VERSION ""

NS_ :

BS_:

BU_: HCM IPMA_ADAS PSCM GWM _delete SCCM PDM DDM GENERIC TSTR
VAL_TABLE_ NotPressed_Pressed_NotU_Faulty 3 "Faulty" 2 "NotUsed" 1 "Pressed" 0 "Not_Pressed" ;
VAL_TABLE_ TsrChime_D_Rq 3 "Null" 2 "Overspeed_chime" 1 "SL_change_chime" 0 "NotUsed" ;
VAL_TABLE_ Fast_Slow 1 "Slow" 0 "Fast" ;
VAL_TABLE_ Disabled_Enabled 1 "Enabled" 0 "Disabled" ;
VAL_TABLE_ NoRequest_Group1_Group2_Both 3 "Both" 2 "Group2" 1 "Group1" 0 "NoRequest" ;
VAL_TABLE_ StlnVeh1_D_StatLim 7 "NotUsed_3" 6 "NotUsed_2" 5 "NotUsed_1" 4 "Accepted" 3 "Pending" 2 "Denied" 1 "Possible" 0 "NotPossible" ;
VAL_TABLE_ StlnVeh1_D_ResLim 31 "NotUsed_14" 30 "NotUsed_13" 29 "NotUsed_12" 28 "NotUsed_11" 27 "NotUsed_10" 26 "NotUsed_9" 25 "NotUsed_8" 24 "NotUsed_7" 23 "NotUsed_6" 22 "NotUsed_5" 21 "NotUsed_4" 20 "NotUsed_3" 19 "NotUsed_2" 18 "NotUsed_1" 17 "ReversePropulsionOnly" 16 "ForwardPropulsionOnly" 15 "SaveEv" 14 "EvOnly" 13 "TqLimitMed_ReducedPower" 12 "TqLimitHigh_Truncation" 11 "VslCustom" 10 "VslHigh_HighwaySpeeds" 9 "VslMed_UrbanSpeeds" 8 "VslLow_ParkingLowSpeed" 7 "LimitedPropulsion" 6 "NonMotiveMode" 5 "SecureMode" 4 "PowerPackBlock_Inhibit" 3 "Custom2" 2 "Custom1" 1 "NoLimitRequested" 0 "Initializing" ;
VAL_TABLE_ TailLghtAnmtn_D_Stat 15 "Faulty" 14 "NotUsed_8" 13 "NotUsed_7" 12 "NotUsed_6" 11 "NotUsed_5" 10 "NotUsed_4" 9 "NotUsed_3" 8 "NotUsed_2" 7 "NotUsed_1" 6 "Type6" 5 "Type5" 4 "Type4" 3 "Type3" 2 "Type2" 1 "Type1" 0 "Null" ;
VAL_TABLE_ None_InProgress_Major_Minor 3 "Minor" 2 "Major" 1 "InProgress" 0 "None" ;
VAL_TABLE_ StopStrtImccTxt_D_Stat 7 "NotUsed_3" 6 "NotUsed_2" 5 "NotUsed_1" 4 "ClosedTimeout" 3 "ClosedYes" 2 "ClosedNo" 1 "ActiveOnDsply" 0 "NotActive" ;
VAL_TABLE_ StopStrtImccActv_D_St 7 "NotUsed_3" 6 "NotUsed_2" 5 "NotUsed_1" 4 "Deactivated" 3 "OnSuspended" 2 "OnActive" 1 "OnNotActive" 0 "Off" ;
VAL_TABLE_ TrakApplActvSet_D_Rq 15 "NotUsed_12" 14 "NotUsed_11" 13 "NotUsed_10" 12 "NotUsed_9" 11 "NotUsed_8" 10 "NotUsed_7" 9 "NotUsed_6" 8 "NotUsed_5" 7 "NotUsed_4" 6 "NotUsed_3" 5 "NotUsed_2" 4 "NotUsed_1" 3 "AccTimer_Start_Track" 2 "AccTimer_Start_Drag" 1 "AccTimer_Start_Automatic" 0 "Null" ;
VAL_TABLE_ TrakAppl_D_RqMnu 31 "NotUsed_15" 30 "NotUsed_14" 29 "NotUsed_13" 28 "NotUsed_12" 27 "NotUsed_11" 26 "NotUsed_10" 25 "NotUsed_9" 24 "NotUsed_8" 23 "NotUsed_7" 22 "NotUsed_6" 21 "NotUsed_5" 20 "NotUsed_4" 19 "NotUsed_3" 18 "NotUsed_2" 17 "NotUsed_1" 16 "Activate_LineLock" 15 "Activate_LapTimer" 14 "Activate_400m" 13 "Activate_200m" 12 "Activate_1/4mile" 11 "Activate_1/8mile" 10 "Activate_0-200kph" 9 "Activate_0-100kph" 8 "Activate_0-50kph" 7 "Activate_0-100mph" 6 "Activate_0-60mph" 5 "Activate_0-30mph" 4 "Activate_200-0kph" 3 "Activate_100-0kph" 2 "Activate_100-0mph" 1 "Activate_60-0mph" 0 "Deactivate_TrackApp" ;
VAL_TABLE_ RoadSignRgltry_D_Dsply 3 "NoEntry" 2 "Stop" 1 "Yield" 0 "None" ;
VAL_TABLE_ Null_Local_Soa_NotUsed_1 3 "NotUsed_1" 2 "Soa" 1 "Local" 0 "Null" ;
VAL_TABLE_ Null_Off_On_NotUsed 3 "NotUsed" 2 "On" 1 "Off" 0 "Null" ;
VAL_TABLE_ FailSuccess 1 "Success" 0 "Fail" ;
VAL_TABLE_ LaActAvail_D2_Actl 3 "Intervention_Available" 2 "NoIntervention_Available" 1 "Intervention_NotAvailable" 0 "NoIntervention_NotAvailabl" ;
VAL_TABLE_ LaActvStats_D2_Dsply 31 "Unused7" 30 "LA_Off" 29 "ECE_OFF_RTT" 28 "Unused4" 27 "Unused3" 26 "Unused2" 25 "Unused1" 24 "InerveneLeft_InterveneRght" 23 "WarnLeft_InterveneRight" 22 "SuppressLeft_InterveneRght" 21 "AvailLeft_InterveneRhtt" 20 "NoLeft_InterveneRight" 19 "InterveneLeft_WarnRight" 18 "WarnLeft_WarnRight" 17 "SuppressLeft_WarnRight" 16 "AvailableLeft_WarnRight" 15 "NoLeft_WarnRight" 14 "InterveneLeft_SuppressRght" 13 "WarnLeft_SuppressRight" 12 "SuppressLeft_SuppressRight" 11 "AvailLeft_SuppressRight" 10 "NoLeft_SuppressRight" 9 "InterveneLeft_AvailRight" 8 "WarnLeft_AvailRight" 7 "SuppressLeft_AvailRight" 6 "AvailableLeft_AvailRight" 5 "NoLeft_AvailableRight" 4 "InterveneLeft_NoRight" 3 "WarnLeft_NoRight" 2 "SuppressLeft_NoRight" 1 "AvailableLeft_NoRight" 0 "NoLeft_NoRight" ;
VAL_TABLE_ TjaCanclMsgTxt_D_Dsply 15 "NotUsed_9" 14 "NotUsed_8" 13 "NotUsed_7" 12 "NotUsed_6" 11 "NotUsed_5" 10 "NotUsed_4" 9 "NotUsed_3" 8 "NotUsed_2" 7 "NotUsed_1" 6 "DriverNotSeen2" 5 "DriverNotSeen1" 4 "HandsFreeUnavailInThisArea" 3 "HandsFreeUnavailForMaxSpd" 2 "CancelledForLaneConditions" 1 "CancelledForRoadCurvature" 0 "NoMessage" ;
VAL_TABLE_ NotPressed_PressedStuckNotUsed 3 "NotUsed" 2 "Stuck" 1 "Pressed" 0 "Not_Pressed" ;
VAL_TABLE_ GfhbMnu_D_Rq 3 "EnableADB" 2 "EnableGFHB" 1 "Disable" 0 "Null" ;
VAL_TABLE_ OffOn_Overruled_NotUsed_1 3 "NotUsed_1" 2 "Overruled" 1 "On" 0 "Off" ;
VAL_TABLE_ StrtrMtrCtlMsgTxt_D_Rq2 15 "Not_Used_12" 14 "Not_Used_11" 13 "Not_Used_10" 12 "Not_Used_9" 11 "Not_Used_8" 10 "Not_Used_7" 9 "Not_Used_6" 8 "Not_Used_5" 7 "Not_Used_4" 6 "Not_Used_3" 5 "Not_Used_2" 4 "Not_Used_1" 3 "Fault_UnableToStrtOrStop" 2 "PressTwiceToStart" 1 "Fault_GoToDealer" 0 "NoMessage" ;
VAL_TABLE_ BptStrtStop_D_Stat 3 "NotUsed_1" 2 "Start" 1 "Stop" 0 "NoRequest" ;
VAL_TABLE_ BptMde_D_Stat 7 "NotUsed_4" 6 "NotUsed_3" 5 "NotUsed_2" 4 "NotUsed_1" 3 "Automatic" 2 "Manual" 1 "Off" 0 "Null" ;
VAL_TABLE_ NoData_Faulty_7FFFFE_7FFFFF 8388607 "Faulty" 8388606 "NoDataExists" ;
VAL_TABLE_ NoData_Faulty_3FFFFE_3FFFFF 4194303 "Faulty" 4194302 "NoDataExists" ;
VAL_TABLE_ PersCtaSplitView_D_Rq 3 "EnabledFull" 2 "Enabled_180SwitchOnly" 1 "Disabled" 0 "Null" ;
VAL_TABLE_ DrvIdMde_D_Rq 7 "Faulty" 6 "NotUsed_2" 5 "KeepAwake" 4 "DeleteMid" 3 "ClearAll" 2 "Enroll" 1 "Recognize" 0 "Disable" ;
VAL_TABLE_ DrvIdMde_D_Stat 7 "Temp_unavailable" 6 "Idle" 5 "DBCorrupt" 4 "DeleteMid" 3 "ClearAll" 2 "Enroll" 1 "Recognize" 0 "Null" ;
VAL_TABLE_ Null_Fail_Success 3 "NotUsed" 2 "Success" 1 "Fail" 0 "Null" ;
VAL_TABLE_ DrvId_D_Stat 7 "NotUsed_3" 6 "NotUsed_2" 5 "NotUsed_1" 4 "FailTimeout" 3 "FailWeakMatch" 2 "OkNoMatch" 1 "OkMatched" 0 "Null" ;
VAL_TABLE_ DrvExpression_D_Stat 15 "NotUsed_5" 14 "NotUsed_4" 13 "NotUsed_3" 12 "FailMultipleMatches" 11 "FailNoSlot" 10 "HasRegister" 9 "ConstraintsOk" 8 "NotAFace" 7 "PoorTrackingQuality" 6 "EyesNotVisible" 5 "FaceBlockage" 4 "MouthOpen" 3 "OutsidePoseLimits" 2 "TooManyFaces" 1 "FaceNotInView" 0 "Null" ;
VAL_TABLE_ AhbFeat_D_Stat 3 "ADB" 2 "GFHB" 1 "AHBC" 0 "None" ;
VAL_TABLE_ NavIod_D_Rq 7 "NotUsed_5" 6 "NotUsed_4" 5 "NotUsed_3" 4 "NotUsed_2" 3 "NotUsed_1" 2 "ModeChange" 1 "VideoOutput" 0 "NoRequest" ;
VAL_TABLE_ NotAvailable_Down_Up_NotU 3 "NotUsed_1" 2 "Up" 1 "Down" 0 "NotAvailable" ;
VAL_TABLE_ EngIdlShutDownT_D_Stat 255 "NotUsed_13" 254 "NotUsed_12" 253 "NotUsed_11" 252 "NotUsed_10" 251 "NotUsed_9" 250 "NotUsed_8" 249 "NotUsed_7" 248 "NotUsed_6" 247 "NotUsed_5" 246 "NotUsed_4" 245 "NotUsed_3" 244 "NotUsed_2" 243 "NotUsed_1" 242 "Indefinite_Idle" 241 "Selectable_Idle_Not_Active" 240 "IdleMinutes_240" 239 "IdleMinutes_239" 238 "IdleMinutes_238" 237 "IdleMinutes_237" 236 "IdleMinutes_236" 235 "IdleMinutes_235" 234 "IdleMinutes_234" 233 "IdleMinutes_233" 232 "IdleMinutes_232" 231 "IdleMinutes_231" 230 "IdleMinutes_230" 229 "IdleMinutes_229" 228 "IdleMinutes_228" 227 "IdleMinutes_227" 226 "IdleMinutes_226" 225 "IdleMinutes_225" 224 "IdleMinutes_224" 223 "IdleMinutes_223" 222 "IdleMinutes_222" 221 "IdleMinutes_221" 220 "IdleMinutes_220" 219 "IdleMinutes_219" 218 "IdleMinutes_218" 217 "IdleMinutes_217" 216 "IdleMinutes_216" 215 "IdleMinutes_215" 214 "IdleMinutes_214" 213 "IdleMinutes_213" 212 "IdleMinutes_212" 211 "IdleMinutes_211" 210 "IdleMinutes_210" 209 "IdleMinutes_209" 208 "IdleMinutes_208" 207 "IdleMinutes_207" 206 "IdleMinutes_206" 205 "IdleMinutes_205" 204 "IdleMinutes_204" 203 "IdleMinutes_203" 202 "IdleMinutes_202" 201 "IdleMinutes_201" 200 "IdleMinutes_200" 199 "IdleMinutes_199" 198 "IdleMinutes_198" 197 "IdleMinutes_197" 196 "IdleMinutes_196" 195 "IdleMinutes_195" 194 "IdleMinutes_194" 193 "IdleMinutes_193" 192 "IdleMinutes_192" 191 "IdleMinutes_191" 190 "IdleMinutes_190" 189 "IdleMinutes_189" 188 "IdleMinutes_188" 187 "IdleMinutes_187" 186 "IdleMinutes_186" 185 "IdleMinutes_185" 184 "IdleMinutes_184" 183 "IdleMinutes_183" 182 "IdleMinutes_182" 181 "IdleMinutes_181" 180 "IdleMinutes_180" 179 "IdleMinutes_179" 178 "IdleMinutes_178" 177 "IdleMinutes_177" 176 "IdleMinutes_176" 175 "IdleMinutes_175" 174 "IdleMinutes_174" 173 "IdleMinutes_173" 172 "IdleMinutes_172" 171 "IdleMinutes_171" 170 "IdleMinutes_170" 169 "IdleMinutes_169" 168 "IdleMinutes_168" 167 "IdleMinutes_167" 166 "IdleMinutes_166" 165 "IdleMinutes_165" 164 "IdleMinutes_164" 163 "IdleMinutes_163" 162 "IdleMinutes_162" 161 "IdleMinutes_161" 160 "IdleMinutes_160" 159 "IdleMinutes_159" 158 "IdleMinutes_158" 157 "IdleMinutes_157" 156 "IdleMinutes_156" 155 "IdleMinutes_155" 154 "IdleMinutes_154" 153 "IdleMinutes_153" 152 "IdleMinutes_152" 151 "IdleMinutes_151" 150 "IdleMinutes_150" 149 "IdleMinutes_149" 148 "IdleMinutes_148" 147 "IdleMinutes_147" 146 "IdleMinutes_146" 145 "IdleMinutes_145" 144 "IdleMinutes_144" 143 "IdleMinutes_143" 142 "IdleMinutes_142" 141 "IdleMinutes_141" 140 "IdleMinutes_140" 139 "IdleMinutes_139" 138 "IdleMinutes_138" 137 "IdleMinutes_137" 136 "IdleMinutes_136" 135 "IdleMinutes_135" 134 "IdleMinutes_134" 133 "IdleMinutes_133" 132 "IdleMinutes_132" 131 "IdleMinutes_131" 130 "IdleMinutes_130" 129 "IdleMinutes_129" 128 "IdleMinutes_128" 127 "IdleMinutes_127" 126 "IdleMinutes_126" 125 "IdleMinutes_125" 124 "IdleMinutes_124" 123 "IdleMinutes_123" 122 "IdleMinutes_122" 121 "IdleMinutes_121" 120 "IdleMinutes_120" 119 "IdleMinutes_119" 118 "IdleMinutes_118" 117 "IdleMinutes_117" 116 "IdleMinutes_116" 115 "IdleMinutes_115" 114 "IdleMinutes_114" 113 "IdleMinutes_113" 112 "IdleMinutes_112" 111 "IdleMinutes_111" 110 "IdleMinutes_110" 109 "IdleMinutes_109" 108 "IdleMinutes_108" 107 "IdleMinutes_107" 106 "IdleMinutes_106" 105 "IdleMinutes_105" 104 "IdleMinutes_104" 103 "IdleMinutes_103" 102 "IdleMinutes_102" 101 "IdleMinutes_101" 100 "IdleMinutes_100" 99 "IdleMinutes_99" 98 "IdleMinutes_98" 97 "IdleMinutes_97" 96 "IdleMinutes_96" 95 "IdleMinutes_95" 94 "IdleMinutes_94" 93 "IdleMinutes_93" 92 "IdleMinutes_92" 91 "IdleMinutes_91" 90 "IdleMinutes_90" 89 "IdleMinutes_89" 88 "IdleMinutes_88" 87 "IdleMinutes_87" 86 "IdleMinutes_86" 85 "IdleMinutes_85" 84 "IdleMinutes_84" 83 "IdleMinutes_83" 82 "IdleMinutes_82" 81 "IdleMinutes_81" 80 "IdleMinutes_80" 79 "IdleMinutes_79" 78 "IdleMinutes_78" 77 "IdleMinutes_77" 76 "IdleMinutes_76" 75 "IdleMinutes_75" 74 "IdleMinutes_74" 73 "IdleMinutes_73" 72 "IdleMinutes_72" 71 "IdleMinutes_71" 70 "IdleMinutes_70" 69 "IdleMinutes_69" 68 "IdleMinutes_68" 67 "IdleMinutes_67" 66 "IdleMinutes_66" 65 "IdleMinutes_65" 64 "IdleMinutes_64" 63 "IdleMinutes_63" 62 "IdleMinutes_62" 61 "IdleMinutes_61" 60 "IdleMinutes_60" 59 "IdleMinutes_59" 58 "IdleMinutes_58" 57 "IdleMinutes_57" 56 "IdleMinutes_56" 55 "IdleMinutes_55" 54 "IdleMinutes_54" 53 "IdleMinutes_53" 52 "IdleMinutes_52" 51 "IdleMinutes_51" 50 "IdleMinutes_50" 49 "IdleMinutes_49" 48 "IdleMinutes_48" 47 "IdleMinutes_47" 46 "IdleMinutes_46" 45 "IdleMinutes_45" 44 "IdleMinutes_44" 43 "IdleMinutes_43" 42 "IdleMinutes_42" 41 "IdleMinutes_41" 40 "IdleMinutes_40" 39 "IdleMinutes_39" 38 "IdleMinutes_38" 37 "IdleMinutes_37" 36 "IdleMinutes_36" 35 "IdleMinutes_35" 34 "IdleMinutes_34" 33 "IdleMinutes_33" 32 "IdleMinutes_32" 31 "IdleMinutes_31" 30 "IdleMinutes_30" 29 "IdleMinutes_29" 28 "IdleMinutes_28" 27 "IdleMinutes_27" 26 "IdleMinutes_26" 25 "IdleMinutes_25" 24 "IdleMinutes_24" 23 "IdleMinutes_23" 22 "IdleMinutes_22" 21 "IdleMinutes_21" 20 "IdleMinutes_20" 19 "IdleMinutes_19" 18 "IdleMinutes_18" 17 "IdleMinutes_17" 16 "IdleMinutes_16" 15 "IdleMinutes_15" 14 "IdleMinutes_14" 13 "IdleMinutes_13" 12 "IdleMinutes_12" 11 "IdleMinutes_11" 10 "IdleMinutes_10" 9 "IdleMinutes_9" 8 "IdleMinutes_8" 7 "IdleMinutes_7" 6 "IdleMinutes_6" 5 "IdleMinutes_5" 4 "IdleMinutes_4" 3 "IdleMinutes_3" 2 "IdleMinutes_2" 1 "IdleMinute_1" 0 "Null" ;
VAL_TABLE_ NotCalibing_Calibing_NotU1_NotU2 3 "NotUsed_2" 2 "NotUsed_1" 1 "Calibrating" 0 "NotCalibrating" ;
VAL_TABLE_ CalibNotReq_CalibReq_NotU1_NotU2 3 "NotUsed_2" 2 "NotUsed_1" 1 "CalibrationRequested" 0 "CalibrationNotRequested" ;
VAL_TABLE_ TrlrCamraView_D_Rq 15 "NotUsed_9" 14 "NotUsed_8" 13 "NotUsed_7" 12 "NotUsed_6" 11 "NotUsed_5" 10 "NotUsed_4" 9 "NotUsed_3" 8 "NotUsed_2" 7 "NotUsed_1" 6 "TrailerRightSideView" 5 "TrailerLeftSideView" 4 "TrailerInteriorView2" 3 "TrailerInteriorView1" 2 "TrailerRearNormalView" 1 "Trailer360View" 0 "Off" ;
VAL_TABLE_ NotConnected_Conntd_NotU1_NotU2 3 "NotUsed_2" 2 "NotUsed_1" 1 "Connected" 0 "NotConnected" ;
VAL_TABLE_ SodAltLeft_D2_StatAft 3 "Faulty" 2 "ActiveDetection" 1 "ActiveNoDetection" 0 "Standby" ;
VAL_TABLE_ Null_RemoteKey_Handsfree_Not1to5 7 "NotUsed_5" 6 "NotUsed_4" 5 "NotUsed_3" 4 "NotUsed_2" 3 "NotUsed_1" 2 "Handsfree" 1 "RemoteKey" 0 "Null" ;
VAL_TABLE_ LckUnlckSrvc_D_Res 15 "Faulty" 14 "NotUsed_7" 13 "NotUsed_6" 12 "NotUsed_5" 11 "NotUsed_4" 10 "NotUsed_3" 9 "NotUsed_2" 8 "NotUsed_1" 7 "Invalid" 6 "In_Prog" 5 "Failed" 4 "Interrupted" 3 "Rejected" 2 "Pending" 1 "Success" 0 "Null" ;
VAL_TABLE_ Real_Inferred 1 "Inferred" 0 "Real" ;
VAL_TABLE_ Null_Locked_Unlocked_NoDevOrDoor 3 "NoDeviceOrDoor" 2 "Unlocked" 1 "Locked" 0 "Null" ;
VAL_TABLE_ TjaLc_D_ET 15 "NotUsed_7" 14 "NotUsed_6" 13 "NotUsed_5" 12 "NotUsed_4" 11 "NotUsed_3" 10 "NotUsed_2" 9 "NotUsed_1" 8 "LcActiveRight" 7 "LcActiveLeft" 6 "PreparingRight" 5 "PreparingLeft" 4 "AvailableLeftRight" 3 "AvailableRight" 2 "AvailableLeft" 1 "Standby" 0 "Off" ;
VAL_TABLE_ TjaLcWarn_D_ET2 7 "NotUsed_2" 6 "NotUsed_1" 5 "CancelSpeedTooLow" 4 "CancelLaneBusy" 3 "CancelNoLane" 2 "SystemCancel" 1 "DriverCancel" 0 "NoWarning" ;
VAL_TABLE_ TjaLcMsgTxt_D_ET 7 "NotUsed_2" 6 "NotUsed_1" 5 "TurnOffIndicator" 4 "AlcOff" 3 "AlcOn" 2 "LcSuggestionRight" 1 "LcSuggestionLeft" 0 "NoMessage" ;
VAL_TABLE_ Inactive_OFF_ON_NotUsed 0 "Inactive" 1 "Off" 2 "On" 3 "NotUsed" ;
VAL_TABLE_ UnlckSrcRl_D_Stat 3 "InnerHandle" 2 "RearInteriorSwitch" 1 "IpSwitch" 0 "Null" ;
VAL_TABLE_ WhlSpareMsgTxt_D_Rq 3 "NotUsed" 2 "PleaseChangeYourSpareTire" 1 "DoNotDriveAbove80kph" 0 "NoMessage" ;
VAL_TABLE_ WhlSpareDetct_D_Dsply 7 "NotUsed_2" 6 "NotUsed_1" 5 "DetectedAtVehicleRearRight" 4 "DetectedAtVehicleRearLeft" 3 "DetectedAtVehicleFrntRight" 2 "DetectedAtVehicleFrontLeft" 1 "Active" 0 "NotActive" ;
VAL_TABLE_ TiltableSteMsgTxt_D_Rq 15 "NotUsed_5" 14 "NotUsed_4" 13 "NotUsed_3" 12 "NotUsed_2" 11 "NotUsed_1" 10 "ShifToNtrlToEnblWhlTilting" 9 "VehMotionNotAllowed" 8 "Fault_VehMotionInhibited" 7 "Fault_VehNotSafeToDrive" 6 "Fault_WhlToBeForcedIntoPos" 5 "Fault_VehicleSafeToDrive" 4 "CntrSteWhlToEnblWhlTilting" 3 "ApplyPrkBrkToEnblWhlTilting" 2 "ShifToParkToEnblWhlTilting" 1 "VehMtnNotAllwAirbagDactv" 0 "NoMessage" ;
VAL_TABLE_ AflMde_D_Rq 15 "NotUsed_13" 14 "NotUsed_12" 13 "NotUsed_11" 12 "NotUsed_10" 11 "NotUsed_9" 10 "NotUsed_8" 9 "NotUsed_7" 8 "NotUsed_6" 7 "NotUsed_5" 6 "NotUsed_4" 5 "NotUsed_3" 4 "NotUsed_2" 3 "NotUsed_1" 2 "TrafficSignDeGlare" 1 "DarkSpot" 0 "None" ;
VAL_TABLE_ HeadLghtHi_D_Rq 7 "NotUsed_4" 6 "NotUsed_3" 5 "NotUsed_2" 4 "NotUsed_1" 3 "OnAutomatic" 2 "OnManual" 1 "Flash" 0 "Off" ;
VAL_TABLE_ OverruledOnOff 3 "NotUsed" 2 "Overruled" 1 "On" 0 "Off" ;
VAL_TABLE_ DcacChime_D_Rq 3 "NotUsed" 2 "SoftChime" 1 "InformationChime" 0 "NoChime" ;
VAL_TABLE_ _S_Off_On 1 "On" 0 "Off" ;
VAL_TABLE_ _S_InactiveActive 1 "Active" 0 "Inactive" ;
VAL_TABLE_ HvacCmprLim_D_Stat 7 "NotUsed_2" 6 "NotUsed_1" 5 "CompressorHeadPressure" 4 "AvailableTorque" 3 "PedalPosition" 2 "RPM" 1 "ECT" 0 "NoLimit" ;
VAL_TABLE_ VehOnSrc_D_Stat 15 "NotUsed_11" 14 "NotUsed_10" 13 "NotUsed_9" 12 "NotUsed_8" 11 "NotUsed_7" 10 "NotUsed_6" 9 "EsclRssd" 8 "AutonomousVehicle" 7 "SecureIdle" 6 "FleetVehicleInhibit" 5 "StolenVehicleInhibit" 4 "OverTheAir" 3 "RemoteParkAssist" 2 "RemoteStart" 1 "Manual" 0 "Off" ;
VAL_TABLE_ NoMessage_Msg1_63 31 "Message31" 30 "Message30" 29 "Message29" 28 "Message28" 27 "Message27" 26 "Message26" 25 "Message25" 24 "Message24" 23 "Message23" 22 "Message22" 21 "Message21" 20 "Message20" 19 "Message19" 18 "Message18" 17 "Message17" 16 "Message16" 15 "Message15" 14 "Message14" 13 "Message13" 12 "Message12" 11 "Message11" 10 "Message10" 9 "Message9" 8 "Message8" 7 "Message7" 6 "Message6" 5 "Message5" 4 "Message4" 3 "Message3" 2 "Message2" 1 "Message1" 0 "NoMessage" 63 "Message63" 47 "Message47" ;
VAL_TABLE_ TrlrRvrseEnbl_D2_Stat 7 "NotUsed" 6 "TbaActiveExpertActive" 5 "TbaActiveExpertAvail" 4 "TbaOffTrgActive" 3 "TbaOffTrgSetup" 2 "TbaSetup" 1 "TbaActive" 0 "Inactive" ;
VAL_TABLE_ StrtrMtrCtlMsgTxt_D2_Rq 3 "NoRequestPcmStartingMsgCtl" 2 "ShiftToNeutralToStart" 1 "ShiftToParkToStart" 0 "NoRequestBcmStartingMsgCtl" ;
VAL_TABLE_ PaakMyKey_D_Rq 3 "NotUsed" 2 "ConfirmNewPaakMyKey" 1 "RequestNewPaakMyKey" 0 "None" ;
VAL_TABLE_ GearPrkLck_D_Stat 7 "NotUsed_1" 6 "FetLifeLimitReached" 5 "FetOpenCircuit" 4 "FetOutputShortToPower" 3 "FetOutputShortToGround" 2 "FetNotControlled" 1 "OnPowerToLoad" 0 "OffNoPowerToLoad" ;
VAL_TABLE_ TrlrIdType_D_Stat 3 "Gooseneck" 2 "FifthWheel" 1 "Conventional" 0 "Null" ;
VAL_TABLE_ TrlrAidSetup_D2_Rq 15 "NotUsed_9" 14 "NotUsed_8" 13 "NotUsed_7" 12 "NotUsed_6" 11 "NotUsed_5" 10 "NotUsed_4" 9 "NotUsed_3" 8 "NotUsed_2" 7 "NotUsed_1" 6 "CompleteSetup" 5 "ReturnToSetup" 4 "StickerNotCircled" 3 "ConfirmSetup" 2 "EndSetup" 1 "BeginSetup" 0 "Inactive" ;
VAL_TABLE_ TrlrAidEnbl_D2_Rq 7 "NotUsed_4" 6 "NotUsed_3" 5 "NotUsed_2" 4 "NotUsed_1" 3 "Deactivate" 2 "ActivateTrg" 1 "ActivateTba" 0 "Inactive" ;
VAL_TABLE_ SwitchNotActive_Active 1 "Switch_Active" 0 "Switch_Not_Active" ;
VAL_TABLE_ LcwaMsgTxt_D_Stat 3 "SodXFaulty" 2 "SodXBlocked" 1 "TrailerConnected" 0 "NoMessage" ;
VAL_TABLE_ Level_0_3 3 "Level_3" 2 "Level_2" 1 "Level_1" 0 "Level_0" ;
VAL_TABLE_ SteWhlSwtchMde_D_Stat 3 "NotUsed_2" 2 "NotUsed_1" 1 "Dialog" 0 "Domain" ;
VAL_TABLE_ TrlrRvrse_D_Stat 3 "Faulty" 2 "TrailerReverseGuidanceLite" 1 "On" 0 "Off" ;
VAL_TABLE_ TrlrAid_D2_Stat 15 "Faulty" 14 "NotUsed_4" 13 "NotUsed_3" 12 "NotUsed_2" 11 "NotUsed_1" 10 "DirtyCamera" 9 "IncorrectLighting" 8 "TrackingLost" 7 "TrackingUnknownConfidence" 6 "TrackingHighConfidence" 5 "TrackingMediumConfidence" 4 "TrackingLowConfidence" 3 "TurnRequested" 2 "DriveStraighRequested" 1 "Initializing" 0 "NotTracking" ;
VAL_TABLE_ TrlrAidSetup_D2_Stat 7 "NotUsed_2" 6 "NotUsed_1" 5 "SetupAcquisitionSuccess" 4 "TbaTadMonitor" 3 "SetupStartAcquisition" 2 "SetupPrepForAcquisition" 1 "TbaActive" 0 "Null" ;
VAL_TABLE_ CamraRearOn_D2_Stat2 7 "Faulty" 6 "NotUsed_3" 5 "NotUsed_2" 4 "NotUsed_1" 3 "Decommission" 2 "Activate" 1 "Deactivate" 0 "Null" ;
VAL_TABLE_ OffNormalSoft 3 "NotUsed" 2 "Soft" 1 "Normal" 0 "Off" ;
VAL_TABLE_ OffOnDisabledInhibited 3 "Inhibited" 2 "Disabled" 1 "On" 0 "Off" ;
VAL_TABLE_ SldrrMsgTxt_D2_Rq 7 "NotUsed_3" 6 "NotUsed_2" 5 "NotUsed_1" 4 "SlidingDrCalibNeeded2" 3 "SlidingDrOpenCltchReleased" 2 "SlidingDrCalibNeeded" 1 "SlidingDrClutchReleased" 0 "Null" ;
VAL_TABLE_ FobTrgtZone_D_Rq 15 "NotUsed_9" 14 "NotUsed_8" 13 "NotUsed_7" 12 "NotUsed_6" 11 "NotUsed_5" 10 "NotUsed_4" 9 "NotUsed_3" 8 "NotUsed_2" 7 "NotUsed_1" 6 "Approach" 5 "RearInterior" 4 "RearExterior" 3 "Passenger" 2 "Driver" 1 "Interior" 0 "Null" ;
VAL_TABLE_ FobTrgtType_D_Rq 7 "NotUsed_4" 6 "NotUsed_3" 5 "NotUsed_2" 4 "NotUsed_1" 3 "Polling" 2 "Registry" 1 "Crypto" 0 "Null" ;
VAL_TABLE_ Null_Yes 1 "Yes" 0 "Null" ;
VAL_TABLE_ Null_NoFault_Fault 3 "NotUsed" 2 "Fault" 1 "NoFault" 0 "Null" ;
VAL_TABLE_ RstrnOnPsngr_D_RqMnu 15 "Faulty" 14 "NotUsed_11" 13 "NotUsed_10" 12 "ConfiguredOff" 11 "NotUsed_9" 10 "On" 9 "NotUsed_8" 8 "NotUsed_7" 7 "NotUsed_6" 6 "NotUsed_5" 5 "Off" 4 "NotUsed_4" 3 "NotUsed_3" 2 "NotUsed_2" 1 "NotUsed_1" 0 "NoAction" ;
VAL_TABLE_ PwStepLeft_D_Rq 1 "Deploy" 0 "Null" 3 "NotUsed" 2 "Stow" ;
VAL_TABLE_ SldrlUnlckSwtch_D_Stat 3 "InnerHandle" 2 "RearInteriorSwitch" 1 "IpSwitch" 0 "Null" ;
VAL_TABLE_ SldrlChime_D_Rq 7 "NotUsed3" 6 "NotUsed2" 5 "NotUsed1" 4 "Warning" 3 "WarningRepeated" 2 "Programming" 1 "Operation" 0 "Off" ;
VAL_TABLE_ Sldrl_D_Stat 3 "NotCalibrated" 2 "Closing" 1 "Opening" 0 "NotMoving" ;
VAL_TABLE_ NoReq_AutoUp_Stop 3 "NotUsed" 2 "Stop" 1 "AutoUp" 0 "NoRequest" ;
VAL_TABLE_ BalrSnsLeft_D_Falt 3 "Invalid" 2 "SystemFailure" 1 "Blocked" 0 "Clear" ;
VAL_TABLE_ Null_Low_Med_High 3 "High" 2 "Medium" 1 "Low" 0 "Null" ;
VAL_TABLE_ Null_NotPressed_Pressed 3 "NotUsed" 2 "Pressed" 1 "NotPressed" 0 "Null" ;
VAL_TABLE_ Low_Med_High 3 "NotUsed" 2 "High" 1 "Medium" 0 "Low" ;
VAL_TABLE_ Null_NotAvail_Avail 3 "NotUsed" 2 "Available" 1 "NotAvailable" 0 "Null" ;
VAL_TABLE_ ChrgGoTMnte_D_Stat 15 "NotUsed_4" 14 "NotUsed_3" 13 "NotUsed_2" 12 "NotUsed_1" 11 "Minute_55" 10 "Minute_50" 9 "Minute_45" 8 "Minute_40" 7 "Minute_35" 6 "Minute_30" 5 "Minute_25" 4 "Minute_20" 3 "Minute_15" 2 "Minute_10" 1 "Minute_5" 0 "Minute_0" ;
VAL_TABLE_ NoData_Faulty_1E_1F 31 "Faulty" 30 "NoDataExists" ;
VAL_TABLE_ TrlrAidMsgTxt_D2_Rq 63 "Message63" 62 "Message62" 61 "Message61" 60 "Message60" 55 "Message55" 50 "Message50" 45 "Message45" 40 "Message40" 35 "Message35" 31 "Message31" 30 "Message30" 29 "Message29" 28 "Message28" 27 "Message27" 26 "Message26" 25 "Message25" 24 "Message24" 23 "Message23" 22 "Message22" 21 "Message21" 20 "Message20" 19 "Message19" 18 "Message18" 17 "Message17" 16 "Message16" 15 "Message15" 14 "Message14" 13 "Message13" 12 "Message12" 11 "Message11" 10 "Message10" 9 "Message9" 8 "Message8" 7 "Message7" 6 "Message6" 5 "Message5" 4 "Message4" 3 "Message3" 2 "Message2" 1 "Message1" 0 "NoMessage" ;
VAL_TABLE_ TrlrAidEnbl_D2_Stat 7 "NotUsed_1" 6 "TbaActiveExpertActive" 5 "TbaActiveExpertAvail" 4 "TbaOffTrgActive" 3 "TbaOffTrgSetup" 2 "TbaSetup" 1 "TbaActive" 0 "Inactive" ;
VAL_TABLE_ RbaCta_D_Stat 7 "Faulty" 6 "NotUsed_2" 5 "NotUsed_1" 4 "Invalid" 3 "Disabled" 2 "On" 1 "Trailer_Tow_Off" 0 "Off" ;
VAL_TABLE_ NoRequest_Mode1_2_3 3 "Mode_3" 2 "Mode_2" 1 "Mode_1" 0 "NoRequest" ;
VAL_TABLE_ RvltnMatchAllw_D_Stat 3 "RevolutionMatchDisabled" 2 "RevolutionMatchEnabled" 1 "ChangeWithDriveMode" 0 "NoSelection" ;
VAL_TABLE_ NotDiagnose_FailPass 3 "NotUsed" 2 "Pass" 1 "Fail" 0 "Not_Diagnose_Yet" ;
VAL_TABLE_ Null_Off_UnavailFaulty 3 "Faulty" 2 "Unavailable" 1 "Off" 0 "Null" ;
VAL_TABLE_ OffOnDisabledNotUsed 3 "NotUsed" 2 "Disabled" 1 "On" 0 "Off" ;
VAL_TABLE_ OffGraphicTextBoth 3 "Both" 2 "Text" 1 "Graphic" 0 "Off" ;
VAL_TABLE_ NoneInactiveActive_NotUsed 3 "NotUsed" 2 "Active" 1 "Inactive" 0 "None" ;
VAL_TABLE_ Off_On_NotUsed 3 "NotUsed_2" 2 "NotUsed_1" 1 "On" 0 "Off" ;
VAL_TABLE_ OffNoPowerToLoad 7 "FetLowSideOpenOrShort" 6 "FetLifeLimitReached" 5 "FetOpenCircuit" 4 "FetOutputShortToPower" 3 "FetOutputShortToGround" 2 "FetNotControlled" 1 "OnPowerToLoad" 0 "OffNoPowerToLoad" ;
VAL_TABLE_ Null_NotPressed_Faulty 3 "Faulty" 2 "Pressed" 1 "NotPressed" 0 "Null" ;
VAL_TABLE_ Null_Off_LowMedHigh 7 "NotUsed_3" 6 "NotUsed_2" 5 "NotUsed_1" 4 "High" 3 "Medium" 2 "Low" 1 "Off" 0 "Null" ;
VAL_TABLE_ TrailCtl_D_Stat 7 "Faulty" 6 "DescentOnly" 5 "EnabledDeny" 4 "StandbyOverThreshold" 3 "StandbyOverride" 2 "Active" 1 "EnabledDescent" 0 "Off" ;
VAL_TABLE_ Faulty_3F 63 "Faulty" ;
VAL_TABLE_ ChrgOvrdExitScrn_D_Rq 3 "NotUsed_1" 2 "Request_override" 1 "Do_not_request_override" 0 "Inactive" ;
VAL_TABLE_ TrlrHitchYaw_D_Stat 15 "Faulty" 14 "NotUsed_4" 13 "NotUsed_3" 12 "NotUsed_2" 11 "NotUsed_1" 10 "FaultyYrsuConnection" 9 "FaultyYrsu" 8 "HiConfdLrndAngle" 7 "LowConfdLrndAngle" 6 "HiConfdAngleMem" 5 "LowConfdAngleMem" 4 "InitNoTadAngle" 3 "InitInputs" 2 "TadTrlrDataOutOfRange" 1 "TadNotWithinSpecification" 0 "NoConnectionWithYrsu" ;
VAL_TABLE_ NoData_Faulty_FFFFFFFFFFFE_FF -1 "Faulty_FFFFFFFFFFFF" -2 "NoDataExists_FFFFFFFFFFFE" ;
VAL_TABLE_ NoFault_Fault 1 "Fault" 0 "NoFault" ;
VAL_TABLE_ OtaTrg_D_Stat 3 "NotUsed_1" 2 "Accepted" 1 "NotAccepted" 0 "Null" ;
VAL_TABLE_ AwdCnnct_D_Stat 3 "Connecting" 2 "Disconnecting" 1 "Connected" 0 "Disconnected" ;
VAL_TABLE_ Null_Invalid_Valid 3 "NotUsed" 2 "Valid" 1 "Invalid" 0 "Null" ;
VAL_TABLE_ ElPwPoint_D_Rq 3 "On" 2 "Off2" 1 "Off1" 0 "Null" ;
VAL_TABLE_ EngExhMdeQuiet_D2_Rq 7 "NotUsed_3" 6 "NotUsed_2" 5 "NotUsed_1" 4 "Track" 3 "Sport" 2 "Normal" 1 "Stealth" 0 "Null" ;
VAL_TABLE_ NoInhibit_Inhibit 1 "Inhibit" 0 "NoInhibit" ;
VAL_TABLE_ PersRecallSrc_D_Actl 7 "NotUsed_3" 6 "NotUsed_2" 5 "NotUsed_1" 4 "MemorySwitch" 3 "RemoteStart" 2 "KeyFob" 1 "CenterStack" 0 "Null" ;
VAL_TABLE_ Null_NotInUse_InUse 3 "NotUsed" 2 "InUse" 1 "NotInUse" 0 "Null" ;
VAL_TABLE_ DrHandle_D_Stat 7 "NotUsed" 6 "Transition" 5 "FlushFault" 4 "DeployFault2" 3 "DeployFault1" 2 "Flush" 1 "Deploy" 0 "None" ;
VAL_TABLE_ TailLghtLoadMde_D_Stat 7 "Faulty" 6 "NotUsed_2" 5 "NotUsed_1" 4 "TailLightModeOverride" 3 "FalrModeActive" 2 "HitchLoadModeActive" 1 "PayloadModeActive" 0 "NoTailLightActive" ;
VAL_TABLE_ Inactive_Disable_Enable_NotUsed 3 "NotUsed" 0 "Inactive" 2 "Enable" 1 "Disable" ;
VAL_TABLE_ CrtsyLghtRear_D_Stat 3 "NotUsed_1" 2 "Automatic" 1 "Manual" 0 "Null" ;
VAL_TABLE_ Low_Med_High_Faulty 3 "Faulty" 2 "High" 1 "Medium" 0 "Low" ;
VAL_TABLE_ TrlrTireCnt_D_Stat 7 "Faulty" 6 "TwelveTire" 5 "EightTire" 4 "FourTireOneAxle" 3 "SixTire" 2 "FourTire" 1 "TwoTire" 0 "Unconfigured" ;
VAL_TABLE_ TrlrTireDual_D_Stat 15 "NotUsed_11" 14 "NotUsed_10" 13 "NotUsed_9" 12 "NotUsed_8" 11 "NotUsed_7" 10 "NotUsed_6" 9 "NotUsed_5" 8 "NotUsed_4" 7 "NotUsed_3" 6 "NotUsed_2" 5 "NotUsed_1" 4 "NotSupported" 3 "Invalid" 2 "InnerTire" 1 "OuterTire" 0 "SystemUnknown" ;
VAL_TABLE_ LoadShedRelayMde_D_Stat 3 "NotUsed_1" 2 "EngRunRelay" 1 "SnowPlow" 0 "LoadShed" ;
VAL_TABLE_ TjaLaneBias_D_Stat 7 "NotUsed" 6 "ElBiasRight" 5 "ElBiasLeft" 4 "SystemBiasRight" 3 "SystemBiasLeft" 2 "ManualBiasRight" 1 "ManualBiasLeft" 0 "NoBias" ;
VAL_TABLE_ NotAvail_OffOn_Faulty 3 "Faulty" 2 "On" 1 "Off" 0 "NotAvailable" ;
VAL_TABLE_ ClrExitAsstMsgTxt2_D_Rq 15 "NotUsed_7" 14 "NotUsed_6" 13 "NotUsed_5" 12 "NotUsed_4" 11 "NotUsed_3" 10 "NotUsed_2" 9 "NotUsed_1" 8 "FrontLeftRearRight" 7 "RearLeftFrontRight" 6 "FrontLeftFrontRight" 5 "RearLeftRearRight" 4 "FrontRight" 3 "FrontLeft" 2 "RearRight" 1 "RearLeft" 0 "NoMessage" ;
VAL_TABLE_ ApaDrvRq2MsgTxt_D_Rq 15 "NotUsed_7" 14 "NotUsed_6" 13 "NotUsed_5" 12 "NotUsed_4" 11 "NotUsed_3" 10 "NotUsed_2" 9 "NotUsed_1" 8 "CloseDoor" 7 "TakeControl" 6 "ReleaseEpb" 5 "ReleaseSteering" 4 "ReleaseBrake" 3 "DriveBackward" 2 "DriveForward" 1 "Stop" 0 "NoRequest" ;
VAL_TABLE_ ApaDrvRq1MsgTxt_D_Rq 7 "NotUsed" 6 "ExitVehicle" 5 "PressApaButton" 4 "ShiftToP" 3 "ShiftToN" 2 "ShiftToD" 1 "ShiftToR" 0 "NoRequest" ;
VAL_TABLE_ PulledAtRest 1 "Pulled" 0 "AtRest" ;
VAL_TABLE_ DcacFaltMsgTxt_D2_Rq 35 "NotUsed_1" 34 "FrontTrnkPlgWarnDertExceed" 33 "FrontTrnkPlgWarnDerate" 32 "FrontTrnkPlgWarnFullPw" 31 "IpcPlugWarnDrive" 30 "DcacbOvercurrentLp" 29 "DcacbService" 28 "DcacbNotAvailable" 27 "DcacbAcOnOutput" 26 "DcacbTemperature" 25 "DcacbGfci" 24 "DcacbOvercurrent" 23 "PpoUsageWhenVehlsCharging" 22 "RpsNewKeyCycleWarning" 21 "LowSocRpsWarning" 20 "RpsResetWarn_ChngDrvToPark" 19 "RpsResetWarning" 18 "FirstRpsWarning" 63 "NotUsed_29" 17 "PowerTakeoff" 16 "HevDerate" 15 "HvacOn" 14 "OvercurrentLP" 13 "EngineRun" 12 "Service" 11 "NotAvailable" 10 "PlugWarn" 9 "PlugWarnDrive" 8 "BreakerC" 7 "BreakerB" 6 "BreakerA" 5 "FuelLow" 4 "AcOnOutput" 3 "Temperature" 2 "Gfci" 1 "Overcurrent" 0 "Ok" ;
VAL_TABLE_ Hour5bitNull 31 "NotUsed_7" 30 "NotUsed_6" 29 "NotUsed_5" 28 "NotUsed_4" 27 "NotUsed_3" 26 "NotUsed_2" 25 "NotUsed_1" 24 "Hour23_11pm" 23 "Hour22_10pm" 22 "Hour21_9pm" 21 "Hour20_8pm" 20 "Hour19_7pm" 19 "Hour18_6pm" 18 "Hour17_5pm" 17 "Hour16_4pm" 16 "Hour15_3pm" 15 "Hour14_2pm" 14 "Hour13_1pm" 13 "Hour12_12pm" 12 "Hour11_11am" 11 "Hour10_10am" 10 "Hour9_9am" 9 "Hour8_8am" 8 "Hour7_7am" 7 "Hour6_6am" 6 "Hour5_5am" 5 "Hour4_4am" 4 "Hour3_3am" 3 "Hour2_2am" 2 "Hour1_1am" 1 "Hour0_12am" 0 "Null" ;
VAL_TABLE_ Null_Dis_En_NotConfig 3 "NotConfigured" 2 "Enabled" 1 "Disabled" 0 "Null" ;
VAL_TABLE_ IaccVAdjReas_D_Dsply 15 "NotUsed_21" 11 "NotUsed_1" 10 "SpeedSign" 9 "LeftRamp" 8 "RightRamp" 7 "Roundabout_CCW" 6 "Roundabout_CW" 5 "LeftCurve" 4 "RightCurve" 3 "LeftTurnIntersection" 2 "RightTurnIntersection" 1 "RoadGeometryUnavailable" 0 "NoDisplay" ;
VAL_TABLE_ SdarsAudioRtng_D_Stat 3 "NotUsed" 2 "APIMStereoOut" 1 "X40l2SStereoOut" 0 "NotDetermined" ;
VAL_TABLE_ ApaSlotAlrtSet_D_RqDrv 3 "TemporarySuppression" 2 "Disable" 1 "Enable" 0 "None" ;
VAL_TABLE_ ApaFeat_D_RqDrv 7 "Faulty" 6 "Off" 5 "RePA" 4 "ParkIn" 3 "POA" 2 "PPA" 1 "SAPP" 0 "Inactive" ;
VAL_TABLE_ ApaSlot_D_Stat 7 "NotUsed_3" 6 "NotUsed_2" 5 "NotUsed_1" 4 "IPeReady" 3 "IPeFound" 2 "IPaReady" 1 "IPaFound" 0 "None" ;
VAL_TABLE_ OffOnOutageFaulty 3 "Faulty" 2 "Outage" 1 "On" 0 "Off" ;
VAL_TABLE_ RmtCtlConfgSrc_D_Stat 7 "NotUsed_2" 6 "NotUsed_1" 5 "BPO" 4 "ApaHmi" 3 "FAP_Handover" 2 "User" 1 "None" 0 "NotDetermined" ;
VAL_TABLE_ RmtCtlPathPlan_D_Stat 7 "NotUsed_3" 6 "NotUsed_2" 5 "NotUsed_1" 4 "FinishedMovesExceeded" 3 "FinishedDistanceExceeded" 2 "Finished" 1 "Ongoing" 0 "None" ;
VAL_TABLE_ RmtCtlAdas_D_Stat 7 "Paused" 6 "Abort" 5 "ManeuverFinished" 4 "EndPositionReached" 3 "Backward" 2 "Forward" 1 "ManeuverBegin" 0 "Inactive" ;
VAL_TABLE_ RmtCtlSns_D_Stat 3 "Zone3" 2 "Zone2" 1 "Zone1" 0 "Off" ;
VAL_TABLE_ PrkMde_D_ET 3 "NotUsed" 2 "FreeDrive" 1 "ParkIn" 0 "None" ;
VAL_TABLE_ RmtCtlPrkInSlot_D_ET 7 "NotUsed_3" 6 "NotUsed_2" 5 "NotUsed_1" 4 "Right" 3 "Left" 2 "Rear" 1 "Front" 0 "None" ;
VAL_TABLE_ Orientation_D_ET 3 "NotUsed" 2 "Backward" 1 "Forward" 0 "Null" ;
VAL_TABLE_ MoveDir_D_ET 3 "NotUsed" 2 "Backward" 1 "Forward" 0 "None" ;
VAL_TABLE_ RmtCtlOrientAvail_D_ET 7 "NotUsed_3" 6 "NotUsed_2" 5 "NotUsed_1" 4 "Both" 3 "Backward" 2 "Forward" 1 "None" 0 "NotDetermined" ;
VAL_TABLE_ Faulty_NoData_NotWithinSpec_OK 3 "OK" 2 "NotWithinSpecifications" 1 "NoDataExists" 0 "Faulty" ;
VAL_TABLE_ ApaSys_D2_Stat 15 "NotUsed_5" 14 "NotUsed_4" 13 "NotUsed_3" 12 "NotUsed_2" 11 "NotUsed_1" 10 "NoSideSelectable" 9 "RightSideSelectable" 8 "LeftSideSelectable" 7 "BothSidesSelectable" 6 "Faulty" 5 "Finished" 4 "Cancelled" 3 "NotAvailable" 2 "Overspeed" 1 "Pause" 0 "NormalOperation" ;
VAL_TABLE_ ApaSlotTrgt_D_Stat 15 "NotUsed_7" 14 "NotUsed_6" 13 "NotUsed_5" 12 "NotUsed_4" 11 "NotUsed_3" 10 "NotUsed_2" 9 "NotUsed_1" 8 "Front" 7 "Rear" 6 "Right3" 5 "Right2" 4 "Right1" 3 "Left3" 2 "Left2" 1 "Left1" 0 "None" ;
VAL_TABLE_ ApaMsgTxt_D2_Stat 15 "ReducedFunction" 14 "TrailerFeatureNotAvailable" 13 "AcceleratorPedalInactive" 12 "SensorsBlocked" 11 "TrailerAttached" 10 "TcsDeactivated" 9 "WheelSlip" 8 "HighInclination" 7 "DoorOpen" 6 "SteeringInteraction" 5 "WrongDirection" 4 "SpeedLimitExceeded" 3 "BrakeEvent" 2 "ObstacleInPath" 1 "WaitForSteering" 0 "None" ;
VAL_TABLE_ DisplayMode 3 "NotUsed" 2 "FullScreen" 1 "Menu" 0 "Off" ;
VAL_TABLE_ ClrExitAsstMsgTxt_D_Rq 15 "NotUsed_8" 14 "NotUsed_7" 13 "NotUsed_6" 12 "NotUsed_5" 11 "NotUsed_4" 10 "NotUsed_3" 9 "NotUsed_2" 8 "NotUsed_1" 7 "SystemFault" 6 "ChildLockMaintained" 5 "WarningRight" 4 "WarningLeft" 3 "InformationRight" 2 "InformationLeft" 1 "Shutdown" 0 "NoMessage" ;
VAL_TABLE_ InactiveDisableEnableNotUsed 3 "NotUsed" 0 "Inactive" 2 "Enable" 1 "Disable" ;
VAL_TABLE_ ClrExitAsstChime_D_Rq 7 "NotUsed_4" 6 "NotUsed_3" 5 "NotUsed_2" 4 "NotUsed_1" 3 "WarningChimeFront" 2 "WarningChimeRear" 1 "InformationChime" 0 "Off" ;
VAL_TABLE_ BrkPwTest_D_Stat 3 "Faulted" 2 "Aborted" 1 "Running" 0 "NotRunning" ;
VAL_TABLE_ Null_Manual_Automatic 3 "NotUsed" 2 "Automatic" 1 "Manual" 0 "Null" ;
VAL_TABLE_ NotParked_Parked 1 "Parked" 0 "NotParked" ;
VAL_TABLE_ LongCtlSrcScnd_D_Actl 3 "MobilityController" 2 "HumanDriver" 1 "VirtualDriver" 0 "Default" ;
VAL_TABLE_ Degraded_Ok 1 "Ok" 0 "Degraded" ;
VAL_TABLE_ TrlrAlarmSpprt_D_Stat 3 "SupportedByBrakesAndLights" 2 "SupportedByLights" 1 "SupportedByBrakes" 0 "NotSupported" ;
VAL_TABLE_ Null_Extend_Retract 3 "NotUsed" 2 "Retract" 1 "Extend" 0 "Null" ;
VAL_TABLE_ SeatSlprPosPsngr_D_Stat 3 "Faulty" 2 "Sleeper" 1 "Upright" 0 "Null" ;
VAL_TABLE_ TrailOnePdlMde_D_Ind 7 "NotUsed_4" 6 "NotUsed_3" 5 "NotUsed_2" 4 "NotUsed_1" 3 "Standby" 2 "Active" 1 "Fault" 0 "Off" ;
VAL_TABLE_ DsmcMsgTxt_D_Dsply 3 "Blockage" 2 "DriverNotSeen" 1 "Fault" 0 "NoMessage" ;
VAL_TABLE_ VehInhbtMde_D_Stat 7 "NotUsed_3" 6 "NotUsed_2" 5 "NotUsed_1" 4 "FullVehicleOta" 3 "Iviota" 2 "SyncOta" 1 "NoOtaSupport" 0 "Unconfigured" ;
VAL_TABLE_ TlghtTest_D_Stat 3 "InProgress" 2 "Ended" 1 "Completed" 0 "Null" ;
VAL_TABLE_ TlightTest_D_Rq 3 "TestEndAcknowledge" 2 "StartTest" 1 "StopTest" 0 "Null" ;
VAL_TABLE_ TlghtTestPrecnd_D_Stat 7 "Error" 6 "NotStationary" 5 "InteractionPresent" 4 "PreconditionsPassed" 3 "BattSocLessThan75Percent" 2 "TailLightsOn" 1 "IgnitionNotOn" 0 "Null" ;
VAL_TABLE_ TlghtTestLght_D_Stat 7 "Error" 6 "AllOff" 5 "TestingReverseLights" 4 "TestingBrakeLights" 3 "TestingLeftTurnSignal" 2 "TestingRightTurnSignal" 1 "ParkingLightsIlluminated" 0 "Null" ;
VAL_TABLE_ RmtCtlTrgt_D_Rq 3 "NotUsed" 2 "Null" 1 "RemoteParkAssist" 0 "ManeuverId" ;
VAL_TABLE_ RmtCtlBody_D_Stat 15 "NotUsed_6" 14 "NotUsed_5" 13 "NotUsed_4" 12 "NotUsed_3" 11 "NotUsed_2" 10 "NotUsed_1" 9 "Shutdown" 8 "ManeuverFinished" 7 "ReadyForResume" 6 "Pause" 5 "Maneuvering" 4 "ReadyForManeuvering" 3 "Activation" 2 "Initialize" 1 "Preparation" 0 "Disabled" ;
VAL_TABLE_ RmtCtl_D_RqBody 7 "NotUsed_2" 6 "NotUsed_1" 5 "Error" 4 "Abort" 3 "PauseKeypad" 2 "PauseHazard" 1 "PauseDoorHandle" 0 "Null" ;
VAL_TABLE_ Null_Disabled_Enabled 3 "NotUsed" 2 "Enabled" 1 "Disabled" 0 "Null" ;
VAL_TABLE_ LghtAmbDrvMde_D_Rq 3 "NotUsed" 2 "Automatic" 1 "Manual" 0 "Null" ;
VAL_TABLE_ LghtAmbDrvMde_B_Stat 1 "Automatic" 0 "Manual" ;
VAL_TABLE_ RmtCtlRngSet_D_Rq 3 "NotUsed" 2 "RangeSetB" 1 "RangeSetA" 0 "None" ;
VAL_TABLE_ Null_NoPolling_Polling 3 "NotUsed" 2 "Polling" 1 "NoPolling" 0 "Null" ;
VAL_TABLE_ RmtCtl_D_Stat 15 "Faulty" 14 "NotUsed_5" 13 "NotUsed_4" 12 "NotUsed_3" 11 "NotUsed_2" 10 "NotUsed_1" 9 "Shutdown" 8 "ManeuverFinished" 7 "ReadyForResume" 6 "Pause" 5 "Maneuvering" 4 "ReadyForManeuvering" 3 "Activation" 2 "Initialize" 1 "Preparation" 0 "Disabled" ;
VAL_TABLE_ SelDrvMdeChassis2_D_Rq 31 "Faulty" 30 "NotUsed17" 29 "NotUsed16" 28 "NotUsed15" 27 "NotUsed14" 26 "NotUsed13" 25 "NotUsed12" 24 "NotUsed11" 23 "NotUsed10" 22 "NotUsed9" 21 "NotUsed8" 20 "NotUsed7" 19 "NotUsed6" 18 "NotUsed5" 17 "NotUsed4" 16 "OnePedalDrive" 15 "DragMode" 14 "RoughRoadMode" 13 "TrackMode" 12 "HighSpeedDesertMode" 11 "TowHaulMode" 10 "RockCrawlMode" 9 "SandMode" 8 "MudAndRutsMode" 7 "LowMuMode" 6 "ComfortAdaptiveMode" 5 "ComfortMode" 4 "SportAdaptiveMode" 3 "SportMode" 2 "EconomyMode" 1 "NormalAdaptiveMode" 0 "NormalMode" ;
VAL_TABLE_ CCOI_Policy 15 "NotUsed_4" 14 "NotUsed_3" 13 "NotUsed_2" 12 "NotUsed_1" 11 "DataStorageError" 10 "StateMachineInconsistent" 9 "UnrecoverableSyncError" 8 "OnBoardSyncFailed" 7 "OnBoardImplemented" 6 "OnBoardSynchronized" 5 "OnBoardSynchronizing" 4 "OnBoardSyncNeeded" 3 "OffBoardUpdatePending" 2 "OnBoardUpdatePending" 1 "Waiting" 0 "Null" ;
VAL_TABLE_ FactoryReset_Rq 1 "ResetFactoryDefaults" 0 "Inactive" ;
VAL_TABLE_ TCU_Init_Actvtn_St 3 "NotUsed" 2 "InitialActivateDeny" 1 "InitialActivateAccept" 0 "Invalid" ;
VAL_TABLE_ TCU_Final_Actvtn_St 3 "NotUsed" 2 "FinalActivateDeny" 1 "FinalActivateAccept" 0 "Invalid" ;
VAL_TABLE_ Null_Disable_Enable 3 "NotUsed" 2 "Enable" 1 "Disable" 0 "Null" ;
VAL_TABLE_ WaitToStartLamp_D_Falt 3 "NotUsed" 2 "Wait_to_start_lamp_failed" 1 "Diagnosis_not_ready" 0 "Wait_to_start_lamp_OK" ;
VAL_TABLE_ NonMagnetic_Magnetic 1 "Magnetic" 0 "NonMagnetic" ;
VAL_TABLE_ AutoTowAllw_D_StatMnu 3 "TowHaulCommandedOn" 2 "AutoTowHaulEnabled" 1 "AutoTowHaulDisabled" 0 "NoSelection" ;
VAL_TABLE_ SrpEventRight_D_Stat 3 "Faulty" 2 "Bump" 1 "Pothole" 0 "NoEvent" ;
VAL_TABLE_ SpkrStd_D_Stat 3 "Faulty" 2 "Normal" 1 "NotPresent" 0 "Null" ;
VAL_TABLE_ NotAllowed_Allowed 1 "Allowed" 0 "NotAllowed" ;
VAL_TABLE_ EngTrlrCnnct_D_Stat 3 "NotUsed_1" 2 "UnverifiedTrailer" 1 "HeavyTrailer" 0 "NoTrailer" ;
VAL_TABLE_ AirSprngRate_D_Rq 3 "NoRequest" 2 "Firm" 1 "Medium" 0 "Soft" ;
VAL_TABLE_ GearLvr_D_ActlDrv 15 "Fault" 14 "Unknown_Position" 13 "NotUsed_2" 12 "NotUsed_1" 11 "Range6" 10 "Range5" 9 "Range4" 8 "Range3_M3_L3" 7 "Range2_M2_L2" 6 "Range1_M1_L1" 5 "Low" 4 "Sport_DriveSport_Mposition" 3 "Drive" 2 "Neutral" 1 "Reverse" 0 "Park" ;
VAL_TABLE_ LkaActvStats_D2_Req 7 "NotUsed" 6 "LkaIncrIntervRight" 5 "LkaSupprRight" 4 "LkaStandIntervRight" 3 "LkaSupprLeft" 2 "LkaStandIntervLeft" 1 "LkaIncrIntervLeft" 0 "LkaNoInterv" ;
VAL_TABLE_ NoMessage_Msg1_3 3 "Message3" 2 "Message2" 1 "Message1" 0 "NoMessage" ;
VAL_TABLE_ TrnRng_D_RqGsm 15 "Fault" 14 "UnknownPosition" 13 "Undefined_2" 12 "Undefined_1" 11 "_6" 10 "_5" 9 "_4" 8 "_3" 7 "_2" 6 "_1" 5 "Low" 4 "Sport_DriveSport" 3 "Drive" 2 "Neutral" 1 "Reverse" 0 "Park" ;
VAL_TABLE_ PrkBrkActv_D_RqGsmGear 3 "NotUsed" 2 "RequestParkBrakeEngage" 1 "NoRequest" 0 "Null" ;
VAL_TABLE_ TrnPrkSys_D_Actl 15 "Faulty" 14 "NotUsed_5" 13 "NotUsed_4" 12 "NotUsed_3" 11 "NotUsed_2" 10 "NotUsed_1" 9 "FrequencyError" 8 "OutOfRangeHigh" 7 "OutOfRangeLow" 6 "Override" 5 "OutOfPark" 4 "TransitionCloseToOutOfPark" 3 "AtNoSpring" 2 "TransitionCloseToPark" 1 "Park" 0 "NotKnown" ;
VAL_TABLE_ OKLowUnknownInvalid 3 "Invalid" 2 "Unknown" 1 "Low" 0 "OK" ;
VAL_TABLE_ PrkAidDrvDir_D_Stat 7 "NotUsed_2" 6 "NotUsed_1" 5 "BackwardNegative" 4 "ForwardNegative" 3 "BackwardPositive" 2 "ForwardPositive" 1 "NoMotion" 0 "DirectionNotKnown" ;
VAL_TABLE_ EngExhMdeQuiet_D2_Stat 7 "Faulty" 6 "NotUsed_2" 5 "NotUsed_1" 4 "Track" 3 "Sport" 2 "Normal" 1 "Stealth" 0 "Null" ;
VAL_TABLE_ GasPrtc_D_RqDsply 7 "NotUsed_5" 6 "NotUsed_4" 5 "NotUsed_3" 4 "NotUsed_2" 3 "NotUsed_1" 2 "GpfOverLimit" 1 "GpfAtLimit" 0 "NormalOperation" ;
VAL_TABLE_ TjaWarn_D_Rq 7 "HardTakeOverEyesOff" 6 "SoftTakeOverEyesOff" 5 "HaLaneDeptWarningLeft" 4 "HaLaneDeptWarningRight" 3 "HardTakeOverLevel2" 2 "HardTakeOverLevel1" 1 "TrafficJamAssistCancel" 0 "NoWarning" ;
VAL_TABLE_ Faulty_7FF 2047 "Faulty" ;
VAL_TABLE_ Tja_D_Stat 7 "ExtendedActive" 6 "ActiveWarningRight" 5 "ActiveWarningLeft" 4 "ActiveInterventionRight" 3 "ActiveInterventionLeft" 2 "Active" 1 "Standby" 0 "Off" ;
VAL_TABLE_ TjaMsgTxt_D_Dsply 7 "Disclaimer" 6 "SmartOffering" 5 "HaSelected" 4 "HaUnavailable" 3 "TurnOnAdaptCruiseControl" 2 "TrafficJamAssistSelected" 1 "TrafficJamAssistUnavailabl" 0 "NoMessage" ;
VAL_TABLE_ ApaTrgtDist_D_Stat 15 "Step15" 14 "Step14" 13 "Step13" 12 "Step12" 11 "Step11" 10 "Step10" 9 "Step9" 8 "Step8" 7 "Step7" 6 "Step6" 5 "Step5" 4 "Step4" 3 "Step3" 2 "Step2" 1 "Step1" 0 "Off" ;
VAL_TABLE_ ApaMsgTxt_D_Rq 15 "NotUsed_6" 14 "NotUsed_5" 13 "NotUsed_4" 12 "NotUsed_3" 11 "ReleaseEpb" 10 "TrailerFeatureNotAvailable" 9 "AccelPedalInactive" 8 "WrongDirection" 7 "SteeringInteraction" 6 "BrakingActive" 5 "HighInclination" 4 "SpeedLimitExceeded" 3 "TcsDisabled" 2 "WheelSlip" 1 "None" 0 "Null" ;
VAL_TABLE_ Memory_2_SwPsngr_Stat 1 "Pressed" 0 "Null" ;
VAL_TABLE_ Pers3Key_D_Stat 3 "NotUsed_1" 2 "KeyUnAssociated" 1 "KeyAssociated" 0 "Null" ;
VAL_TABLE_ AccMsgTxt_D2_Rq 15 "Brakes_Warm" 14 "NCC_Enabled_Warning" 13 "IACC_TJA_Selected" 12 "ACC_TJA_Selected" 11 "IACC_Selected" 10 "Press_Brake_To_Hold" 9 "Only_Following_In_Low_Spd" 8 "TJA_Unavailable" 7 "Shift_Down" 6 "IACC_Unavailable" 5 "ACC_Selected" 4 "ACC_Overridden" 3 "Brake_Capacity_Warning" 2 "ACC_Cancelled" 1 "ACC_Unavailable" 0 "No_Text" ;
VAL_TABLE_ WakeAlarm0_B_Typ 1 "CanAndEcuDriveCircuit" 0 "CanOnly" ;
VAL_TABLE_ EmPrflNo_D_Rq 7 "NotUsed_3" 6 "NotUsed_2" 5 "NotUsed_1" 4 "Pers4" 3 "Pers3" 2 "Pers2" 1 "Pers1" 0 "Null" ;
VAL_TABLE_ EmPrflKeyAssoc_D_Rq 7 "NotUsed_3" 6 "DisassociatePhone" 5 "EnterPhoneAssociation" 4 "OverwriteKey" 3 "DisassociateKey" 2 "ExitKeyAssociation" 1 "EnterKeyAssociation" 0 "Null" ;
VAL_TABLE_ Em_D_Stat 3 "NotSupported" 2 "ProfilesOff" 1 "ProfilesOn" 0 "Null" ;
VAL_TABLE_ EmButtn_D_Stat 7 "ButtonAssociationFailed" 6 "ButtonAssociationExited" 5 "ButtonAssociationEntered" 4 "Button4Pressed" 3 "Button3Pressed" 2 "Button2Pressed" 1 "Button1Pressed" 0 "Null" ;
VAL_TABLE_ EmPrflButtnAssoc_D_Rq 3 "NotUsed" 2 "ExitButtonAssociation" 1 "EnterButtonAssociation" 0 "Null" ;
VAL_TABLE_ EmPrflNo_D_Stat 7 "NotUsed_3" 6 "NotUsed_2" 5 "NotUsed_1" 4 "Pers4" 3 "Pers3" 2 "Pers2" 1 "Pers1" 0 "Null" ;
VAL_TABLE_ EmPrflKeyAssoc_D_Stat 7 "WrongDevice" 6 "KeyAssociateFailed" 5 "KeyAssociateSuccess" 4 "KeyAlreadyInUse" 3 "KeyDisassociated" 2 "KeyAssociationExited" 1 "KeyAssociationEntered" 0 "Null" ;
VAL_TABLE_ EsaEnbl_D2_Rq 3 "NotConfigured" 2 "Enabled" 1 "Pending" 0 "Disabled" ;
VAL_TABLE_ PersNo_D_Actl 7 "Unused_3" 6 "Unused_2" 5 "NotDetermined" 4 "Vehicle" 3 "PERS_4" 2 "PERS_3" 1 "PERS_2" 0 "PERS_1" ;
VAL_TABLE_ WiprFront_D_Stat2 15 "NO_DATA_EXISTS" 14 "STALLED" 13 "NotUsed" 12 "AUTO_ADJUST" 11 "COURTESYWIPE" 10 "AUTO_HIGH" 9 "AUTO_LOW" 8 "WASH" 7 "MIST_FLICK" 6 "MAN_HIGH" 5 "MAN_LOW" 4 "MAN_INT_ON" 3 "MAN_INT_OFF" 2 "OFF_MOVING" 1 "AUTO_OFF" 0 "OFF" ;
VAL_TABLE_ TurnLghtSwtch_D_Stat2 3 "NotUsed" 2 "Right" 1 "Left" 0 "Off" ;
VAL_TABLE_ CcButtnOnOffCnclPress3 1 "Pressed" 0 "Not pressed" ;
VAL_TABLE_ SelDrvMdePos01_B_Avail 1 "Available" 0 "NotAvailable" ;
VAL_TABLE_ SelDrvMdePos01_D_Stat 31 "Faulty" 30 "SelDrvMde31" 29 "SelDrvMde30" 28 "SelDrvMde29" 27 "SelDrvMde28" 26 "SelDrvMde27" 25 "SelDrvMde26" 24 "SelDrvMde25" 23 "SelDrvMde24" 22 "SelDrvMde23" 21 "SelDrvMde22" 20 "SelDrvMde21" 19 "SelDrvMde20" 18 "SelDrvMde19" 17 "SelDrvMde18" 16 "SelDrvMde17" 15 "SelDrvMde16" 14 "SelDrvMde15" 13 "SelDrvMde14" 12 "SelDrvMde13" 11 "SelDrvMde12" 10 "SelDrvMde11" 9 "SelDrvMde10" 8 "SelDrvMde09" 7 "SelDrvMde08" 6 "SelDrvMde07" 5 "SelDrvMde06" 4 "SelDrvMde05" 3 "SelDrvMde04" 2 "SelDrvMde03" 1 "SelDrvMde02" 0 "SelDrvMde01" ;
VAL_TABLE_ ImmedFastMediumSlow 3 "Slow" 2 "Medium" 1 "Fast" 0 "Immediately" ;
VAL_TABLE_ AdbHiBeamKeepOff_D_Rq 3 "KeepBothOff" 2 "KeepLeftOff" 1 "KeepRightOff" 0 "BothFreeRunning" ;
VAL_TABLE_ AdbLampOnOff_D_Rq 3 "BothOn" 2 "LeftOnRightOff" 1 "RightOnLeftOff" 0 "BothOff" ;
VAL_TABLE_ Closed_Open_Active_Denied 3 "Denied" 2 "Active" 1 "Open" 0 "Closed" ;
VAL_TABLE_ IaccLamp_D_Rq 3 "NotUsed_2" 2 "NotUsed_1" 1 "DisplayIaccIcon" 0 "DoNotDisplayIaccIcon" ;
VAL_TABLE_ Low_High_Confidence 1 "High_Confidence" 0 "Low_Confidence" ;
VAL_TABLE_ Fault_Occupied_Empty_Un 3 "Unknown" 2 "Empty" 1 "Occupied" 0 "Fault" ;
VAL_TABLE_ Off_On_Flash_Triggered 3 "Triggered" 2 "Flash" 1 "On" 0 "Off" ;
VAL_TABLE_ KeyOffMde_D_Actl 15 "NotUsed_11" 14 "NotUsed_10" 13 "NotUsed_9" 12 "NotUsed_8" 11 "NotUsed_7" 10 "NotUsed_6" 9 "NotUsed_5" 8 "NotUsed_4" 7 "NotUsed_3" 6 "NotUsed_2" 5 "NotUsed_1" 4 "CriticalBattery" 3 "Hibernate" 2 "Transport" 1 "Factory" 0 "Normal" ;
VAL_TABLE_ IaccVLim_D_Rq 252 "NotUsed_2" 250 "LimitSpeed_250" 240 "LimitSpeed_240" 230 "LimitSpeed_230" 220 "LimitSpeed_220" 210 "LimitSpeed_210" 200 "LimitSpeed_200" 190 "LimitSpeed_190" 150 "LimitSpeed_150" 140 "LimitSpeed_140" 130 "LimitSpeed_130" 120 "LimitSpeed_120" 110 "LimitSpeed_110" 100 "LimitSpeed_100" 90 "LimitSpeed_90" 80 "LimitSpeed_80" 70 "LimitSpeed_70" 60 "LimitSpeed_60" 50 "LimitSpeed_50" 40 "LimitSpeed_40" 30 "LimitSpeed_30" 20 "LimtSpeed_20" 251 "NotUsed_1" 255 "Faulty" 254 "NoDataExists" 253 "NotUsed_3" 180 "LimitSpeed_180" 179 "LimitSpeed_179" 178 "LimitSpeed_178" 177 "LimitSpeed_177" 176 "LimitSpeed_176" 175 "LimitSpeed_175" 174 "LimitSpeed_174" 173 "LimitSpeed_173" 172 "LimitSpeed_172" 171 "LimitSpeed_171" 170 "LimitSpeed_170" 169 "LimitSpeed_169" 168 "LimitSpeed_168" 167 "LimitSpeed_167" 166 "LimitSpeed_166" 165 "LimitSpeed_165" 164 "LimitSpeed_164" 163 "LimitSpeed_163" 162 "LimitSpeed_162" 161 "LimitSpeed_161" 160 "LimitSpeed_160" 15 "LimitSpeed_15" 14 "LimitSpeed_14" 13 "LimitSpeed_13" 12 "LimitSpeed_12" 11 "LimitSpeed_11" 10 "LimitSpeed_10" 9 "LimitSpeed_9" 8 "LimitSpeed_8" 7 "LimitSpeed_7" 6 "LimitSpeed_6" 5 "LimitSpeed_5" 4 "LimitSpeed_4" 3 "LimitSpeed_3" 2 "LimitSpeed_2" 1 "LimitSpeed_1" 0 "LimitSpeed_0" ;
VAL_TABLE_ IaccVLimUnit_D_Rq 3 "NoDataExists" 2 "Mph" 1 "Kph" 0 "Null" ;
VAL_TABLE_ SelDrvMdeAwd_D_Rq 31 "Faulty" 30 "NotUsed_17" 29 "NotUsed_16" 28 "NotUsed_15" 27 "NotUsed_14" 26 "NotUsed_13" 25 "NotUsed_12" 24 "NotUsed_11" 23 "NotUsed_10" 22 "NotUsed_9" 21 "NotUsed_8" 20 "CustomMode" 19 "OnePedalDrive" 18 "DragMode" 17 "EvLaterChargeMode" 16 "EvNowMode" 15 "TrackMode" 14 "RoughRoadMode" 13 "NotAvailable" 12 "HighSpeedDesertMode_Baja" 11 "SportAdaptiveMode" 10 "RockCrawlMode" 9 "MudRutsMode" 8 "SandMode" 7 "EconomyMode" 6 "GrassGravelSnow" 5 "TowHaulMode" 4 "SportMode" 3 "Normal_4L" 2 "Normal_4A" 1 "Normal_2H" 0 "NormalMode" ;
VAL_TABLE_ SelDrvMdeAwd_D_Stat 0 "NotAvailable" 1 "Available" 2 "TemporarilyNotAvailable" 3 "Faulty" ;
VAL_TABLE_ RearDiffLckMsg2_D_Rq 15 "NotUsed_3" 14 "NotUsed_2" 13 "NotUsed_1" 12 "ElsdReduced" 11 "LockingFeatureNotAvailable" 10 "EsldOff" 9 "ElsdRestored" 8 "ElsdOverheated" 7 "Locker_Disabled" 6 "Locker_Enabled" 5 "LockerSpeed5" 4 "LockerSpeed4" 3 "LockerSpeed3" 2 "LockerSpeed2" 1 "LockerSpeed1" 0 "NormalNoMessage " ;
VAL_TABLE_ Counts_ZeroToSeven 4 "FourCounts" 3 "ThreeCounts" 2 "TwoCounts" 1 "OneCount" 0 "ZeroCounts" 7 "SevenOrMoreCounts" 6 "SixCounts" 5 "FiveCounts" ;
VAL_TABLE_ HeadLghtHiPrmsn_D_Stat 3 "CancelAndSuppress" 2 "Cancel" 1 "Hold" 0 "AllowChange" ;
VAL_TABLE_ SelDrvMdeSwtch 3 "Faulty" 2 "SwitchState2" 1 "SwitchState1" 0 "NotPressed" ;
VAL_TABLE_ NotAvail_Temp_Faulty 3 "Faulty" 2 "TemporarilyNotAvailable" 1 "Available" 0 "NotAvailable" ;
VAL_TABLE_ AwdDrvMde 7 "Faulty" 6 "NotAvailable" 5 "RockCrawl" 4 "Baja" 3 "MudAndSand" 2 "Weather" 1 "Sport" 0 "Normal" ;
VAL_TABLE_ SelDrvMdePt_D_Rq 31 "Faulty" 30 "NotUsed15" 29 "NotUsed14" 28 "NotUsed13" 27 "NotUsed12" 26 "NotUsed11" 25 "NotUsed10" 24 "NotUsed9" 23 "NotUsed8" 22 "NotUsed7" 21 "CustomMode" 20 "TrackMode" 19 "OnePedalDrive" 18 "EvLaterChargerMode" 17 "EvNowMode" 16 "DragMode" 15 "HighSpeedDesertMode_Baja" 14 "SportAdaptiveMode" 13 "NotAvailable_13" 12 "NotAvailable_12" 11 "NotAvailable_11" 10 "NotAvailable_10" 9 "RockCrawlMode" 8 "MudRutsMode" 7 "SandMode" 6 "EconomyMode" 5 "GrassGravelSnow" 4 "NotAvailable_04" 3 "TowHaulMode" 2 "NotAvailable_02" 1 "SportMode" 0 "NormalMode" ;
VAL_TABLE_ SelDrvMde_D_Stat 3 "NotUsed" 2 "DriveModeChangeRequest" 1 "DriveModeChangeSelection" 0 "NoDriveModeChangeRequest" ;
VAL_TABLE_ NoMessage_Msg1_15 15 "Message15" 14 "Message14" 13 "Message13" 12 "Message12" 11 "Message11" 10 "Message10" 9 "Message9" 8 "Message8" 7 "Message7" 6 "Message6" 5 "Message5" 4 "Message4" 3 "Message3" 2 "Message2" 1 "Message1" 0 "NoMessage" ;
VAL_TABLE_ SelDrvMdeChassis_D_Rq 31 "Faulty" 30 "NotUsed17" 29 "NotUsed16" 28 "NotUsed15" 27 "NotUsed14" 26 "NotUsed13" 25 "NotUsed12" 24 "NotUsed11" 23 "NotUsed10" 22 "NotUsed9" 21 "NotUsed8" 20 "NotUsed7" 19 "NotUsed6" 18 "NotUsed5" 17 "NotUsed4" 16 "OnePedalDrive" 15 "DragMode" 14 "RoughRoadMode" 13 "TrackMode" 12 "HighSpeedDesertMode" 11 "TowHaulMode" 10 "RockCrawlMode" 9 "SandMode" 8 "MudAndRutsMode" 7 "LowMuMode" 6 "ComfortAdaptiveMode" 5 "ComfortMode" 4 "SportAdaptiveMode" 3 "SportMode" 2 "EconomyMode" 1 "NormalAdaptiveMode" 0 "NormalMode" ;
VAL_TABLE_ NotAvailable_Available 1 "Available" 0 "NotAvailable" ;
VAL_TABLE_ NoMessage_Msg1_31 31 "Message31" 30 "Message30" 29 "Message29" 28 "Message28" 27 "Message27" 26 "Message26" 25 "Message25" 24 "Message24" 23 "Message23" 22 "Message22" 21 "Message21" 20 "Message20" 19 "Message19" 18 "Message18" 17 "Message17" 16 "Message16" 15 "Message15" 14 "Message14" 13 "Message13" 12 "Message12" 11 "Message11" 10 "Message10" 9 "Message9" 8 "Message8" 7 "Message7" 6 "Message6" 5 "Message5" 4 "Message4" 3 "Message3" 2 "Message2" 1 "Message1" 0 "NoMessage" ;
VAL_TABLE_ VehTrvlDir_D_Stat 7 "Faulty" 6 "NoDataExists" 5 "NotUsed2" 4 "NotUsed1" 3 "Reverse" 2 "LikelyReverse" 1 "Forward" 0 "LikelyForward" ;
VAL_TABLE_ TrnRng_D_RqFap 7 "NotUsed3" 6 "NotUsed2" 5 "NotUsed1" 4 "Backwards" 3 "Forwards" 2 "NoMotion" 1 "Immobilize" 0 "NoRequest" ;
VAL_TABLE_ SelDrvMdeSusp_D_Stat 3 "Faulty" 2 "TemporarilyNotAvailable" 1 "Available" 0 "NotAvailable" ;
VAL_TABLE_ OffOnNoReqFaulty 3 "Faulty" 2 "NoRequest" 1 "On" 0 "Off" ;
VAL_TABLE_ LatCtlSte_D_Stat 7 "NotUsed3" 6 "NotUsed2" 5 "NotUsed1" 4 "Denied" 3 "RampOut" 2 "ContLatControlInProgress" 1 "Available" 0 "Unavailable" ;
VAL_TABLE_ SlowMedFastImmed 3 "Immediately" 2 "Fast" 1 "Medium" 0 "Slow" ;
VAL_TABLE_ ComfortablePreciseNotUsed 3 "NotUsed2" 2 "NotUsed1" 1 "Precise" 0 "Comfortable" ;
VAL_TABLE_ LatCtlLim_D_Stat 3 "LimitWithDriverActive" 2 "LimitReached" 1 "LimitClose" 0 "LimitNotReached" ;
VAL_TABLE_ AwdMde_D_RqDrv 7 "Faulty" 6 "NotUsed2" 5 "NoRequest" 4 "Neutral" 3 "FourByFourLow" 2 "FourByFourHigh" 1 "FourByFourAuto" 0 "FourByTwo" ;
VAL_TABLE_ ApaBrk_D_Stat 3 "Denied" 2 "Active" 1 "Open" 0 "Closed" ;
VAL_TABLE_ AdptDrvMdePt_D_Rq 7 "Faulty" 6 "NotUsed3" 5 "NotUsed2" 4 "NotUsed1" 3 "Powertrain2Sport" 2 "Powertrain2Normal" 1 "Powertrain2Comfort" 0 "AdaptiveNotActive" ;
VAL_TABLE_ AdptDrvMdeChassis_D_Rq 7 "Faulty" 6 "NotUsed3" 5 "NotUsed2" 4 "NotUsed1" 3 "Chassis2Sport" 2 "Chassis2Normal" 1 "Chassis2Comfort" 0 "AdaptiveNotActive" ;
VAL_TABLE_ OffLowMedHigh 3 "High" 2 "Medium" 1 "Low" 0 "Off" ;
VAL_TABLE_ NotDeterminedLowMedHigh 3 "High" 2 "Medium" 1 "Low" 0 "NotDetermined" ;
VAL_TABLE_ CmbbObjClass_D_Stat 15 "NotUsed_9" 14 "NotUsed_8" 13 "NotUsed_7" 12 "NotUsed_6" 11 "NotUsed_5" 10 "NotUsed_4" 9 "NotUsed_3" 8 "NotUsed_2" 7 "NotUsed_1" 6 "Unclassified_Vehicle" 5 "Bicycle" 4 "Pedestrian" 3 "Truck" 2 "Motorcycle" 1 "Vehicle" 0 "Undetermined" ;
VAL_TABLE_ HeadLghtHiCtrl_D_RqAhb 7 "NotUsed2" 6 "NotUsed1" 5 "Auto_HiBeam" 4 "Auto_LoBeam" 3 "Flash" 2 "Man_HiBeam" 1 "Man_LoBeam" 0 "Null" ;
VAL_TABLE_ AhbHiBeam_D_Rq 3 "NotUsed" 2 "HighBeamRecommended" 1 "LowBeamRecommended" 0 "DeactivatedUnavailable" ;
VAL_TABLE_ AhbStatGfhbFdbk_D_Actl 3 "GfhbHighBeamFullyOn" 2 "GfhbHighBeamPartlyOn" 1 "GfhbHighBeamOff" 0 "GfhbUnavailable" ;
VAL_TABLE_ AhbcRampingV_D_Rq 3 "Slow" 2 "Medium" 1 "Fast" 0 "Immediately" ;
VAL_TABLE_ ApaGearShif_D_RqDrv 7 "NotUSed2" 6 "NotUsed1" 5 "ShiftToP" 4 "ShiftToN" 3 "ShiftToD" 2 "ShiftToR" 1 "NoRequest" 0 "Null" ;
VAL_TABLE_ ApaLongCtl_D_RqDrv 7 "NotUsed3" 6 "NotUsed2" 5 "ReleaseBrake" 4 "DriveBackward" 3 "DriveForward" 2 "Stop" 1 "NoRequest" 0 "Null" ;
VAL_TABLE_ ApaActvSide2_D_Stat 3 "NoSide" 2 "Right" 1 "Left" 0 "Null" ;
VAL_TABLE_ ApaScan_D_Stat 3 "ParkSlotReady" 2 "ParkSlotFound" 1 "NoParkSlot" 0 "Null" ;
VAL_TABLE_ ApaSelSapp_D_Stat 3 "NotConfigured" 2 "NotSelectable" 1 "Selectable" 0 "Null" ;
VAL_TABLE_ ApaSys_D_Stat 7 "Faulty" 6 "Finished" 5 "NotAccessible" 4 "ApaCancelled" 3 "Overspeed" 2 "On" 1 "Off" 0 "Null" ;
VAL_TABLE_ ApaAcsy_D_RqDrv 7 "CloseDoor" 6 "SelectSideRight" 5 "SelectSideLeft" 4 "CheckForObject" 3 "PressApaButton" 2 "SelectSide" 1 "NoRequest" 0 "Null" ;
VAL_TABLE_ ApaSteWhl_D_RqDrv 3 "TakeControl" 2 "RemoveHands" 1 "NoRequest" 0 "Null" ;
VAL_TABLE_ WiprFrontSwtch_D_Stat 15 "NotUsed6" 14 "NotUsed5" 13 "NotUsed4" 12 "NotUsed3" 11 "NotUsed2" 10 "NotUsed1" 9 "PositionNotDetermined" 8 "High" 7 "Low" 6 "Position6" 5 "Position5" 4 "Position4" 3 "Position3" 2 "Position2" 1 "Position1" 0 "Off" ;
VAL_TABLE_ TrlrTireSys_D_Stat 15 "NotUsed" 14 "TiresNotTrained" 13 "TrainingComplete" 12 "TrainLMTire" 11 "TrainLRTire" 10 "TrainRMTire" 9 "TrainRRTire" 8 "TrainRFTire" 7 "TrainLFTire" 6 "RequestPressureThresh" 5 "RequestTireCount" 4 "SystemActive" 3 "TireLow" 2 "SensorFault" 1 "System Fault" 0 "SystemUnknown" ;
VAL_TABLE_ Chirp_D_RqTrlr 3 "NotUsed" 2 "Chirp_2" 1 "Chirp_1" 0 "NoRequest" ;
VAL_TABLE_ Off_On_Unknown_Invalid 3 "Invalid" 2 "Unknown" 1 "On" 0 "Off" ;
VAL_TABLE_ Unknown_7FFE_Invalid_7FFF 32767 "Invalid" 32766 "Unknown" ;
VAL_TABLE_ OffOnNotUsedFaulty 3 "Faulty" 2 "NotUsed" 1 "On" 0 "Off" ;
VAL_TABLE_ BrkBstrVac_D_Stat 3 "NotUsed" 2 "BoosterVacEstimator" 1 "BoosterVacSensor" 0 "NoBoosterVacuumMonitor" ;
VAL_TABLE_ AwdMde_D_RqArb 7 "Faulty" 6 "NotUsed2" 5 "NoRequest" 4 "Neutral" 3 "FourByFourLow" 2 "FourByFourHigh" 1 "FourByFourAuto" 0 "FourByTwo" ;
VAL_TABLE_ SeatPos_D_Stat 7 "NotUsed3" 6 "NotUsed2" 5 "Error" 4 "Drive" 3 "Moving" 2 "Pending" 1 "EasyEntry" 0 "Null" ;
VAL_TABLE_ CtaAlrt2_D_Stat 7 "NotUsed3" 6 "NotUsed2" 5 "NotUsed1" 4 "AlertZone4" 3 "AlertZone3" 2 "AlertZone2" 1 "AlertZone1" 0 "Off" ;
VAL_TABLE_ BttRightLeft_D_Stat 7 "BTT5GFault" 6 "Disabled" 5 "Off" 4 "OffTemp" 3 "NotConnected" 2 "Pending" 1 "Connected" 0 "NotDetermined" ;
VAL_TABLE_ Null_NoRequest_Request 3 "NotUsed" 2 "Request" 1 "NoRequest" 0 "Null" ;
VAL_TABLE_ PoliceIdlMde_D_Stat 15 "NotUsed_7" 14 "NotUsed_6" 13 "NotUsed_5" 12 "NotUsed_4" 11 "NotUsed_3" 10 "UtilityIdleActive" 9 "PepsActive" 8 "Decommissioned" 7 "ActiveFault" 6 "ArmFault" 5 "PrearmedFault" 4 "OffFault" 3 "Active" 2 "Arm" 1 "Prearmed" 0 "Off" ;
VAL_TABLE_ LghtAmbIntns_D_Sns 3 "Faulty" 2 "High" 1 "Low" 0 "Null" ;
VAL_TABLE_ TripComputerMetricImperial 0 "TripComputer_metric" 1 "TripComputer_imperial" ;
VAL_TABLE_ PrkBrkMsgTxt_D_Rq 15 "Message15" 14 "Message14" 13 "Message13" 12 "Message12" 11 "Message11" 10 "Message10" 9 "Message9" 8 "Message8" 7 "Message7" 6 "Message6" 5 "Message5" 4 "Message4" 3 "Message3" 2 "Message2" 1 "Message1" 0 "No_Message" ;
VAL_TABLE_ AutoHoldMsgTxt_D_Rq 15 "Message15" 14 "Message14" 13 "Message13" 12 "Message12" 11 "Message11" 10 "Message10" 9 "Message9" 8 "Message8" 7 "Message7" 6 "Message6" 5 "Message5" 4 "Message4" 3 "Message3" 2 "Message2" 1 "Message1" 0 "NoMessage" ;
VAL_TABLE_ AutoHoldMde_D_Ind 3 "Indication_3" 2 "Indication_2" 1 "Indication_1" 0 "Off" ;
VAL_TABLE_ TrnGearMsgTxt_D_Rq 15 "Message_15" 14 "Message_14" 13 "Message_13" 12 "Message_12" 11 "Message_11" 10 "Message_10" 9 "Message_9" 8 "Message_8" 7 "Message_7" 6 "Message_6" 5 "Message_5" 4 "Message_4" 3 "Message_3" 2 "Message_2" 1 "Message_1" 0 "NoMessage" ;
VAL_TABLE_ ACU_AutoStoreResult_St 2 "No_Station_Found" 1 "Inactive" 0 "Invalid" ;
VAL_TABLE_ ACU_DirectTune_St 2 "Valid_Station" 1 "Invalid_Station" 0 "Invalid" ;
VAL_TABLE_ ACU_RadioSeekMode2_St 16 "ContAutoDown" 15 "ContAutoUp" 14 "PISeek" 13 "TpSeek" 12 "Autostore" 11 "PtySeekDown" 10 "PtySeekUp" 9 "ScanDown" 8 "ScanUp" 7 "ContManualDown" 6 "ContManualUp" 5 "ManSingleStepDown" 4 "ManSingleStepUp" 3 "AutoDown" 2 "AutoUp" 1 "SeekOff" 0 "Invalid" ;
VAL_TABLE_ ACU_CurrTUBand_St 10 "SAT2" 9 "SAT1" 8 "DAB2" 7 "DAB1" 6 "Fm3" 5 "AmAst" 4 "Am" 3 "FmAst" 2 "Fm2" 1 "Fm1" 0 "Invalid" 13 "reserved1" 15 "reserved_last" 12 "DAB3" 11 "SAT3" ;
VAL_TABLE_ EngExhMdeQuiet_D_Stat 3 "Faulty" 2 "QuietExhaust" 1 "LoudExhaust" 0 "Null" ;
VAL_TABLE_ GearSelLck_D_Rq 3 "PreventionBlocker" 2 "Unlock" 1 "Lock" 0 "Null" ;
VAL_TABLE_ BrkPadMsgTxt_D_Rq 3 "Faulty" 2 "PadsOk" 1 "ReplacePads" 0 "Null" ;
VAL_TABLE_ SuspDrvMde_D_Rq 7 "Faulty" 6 "NotUsed2" 5 "NotUsed1" 4 "Drag" 3 "Track" 2 "Snow_Wet" 1 "Sport" 0 "Normal" ;
VAL_TABLE_ NotPressed_PressedNotUsed 3 "NotUsed2" 2 "NotUsed1" 1 "Pressed" 0 "Not_Pressed" ;
VAL_TABLE_ TracKeyMde_D_Stat 3 "NotUsed" 2 "NotActive" 1 "Active" 0 "ModeNotDetermined" ;
VAL_TABLE_ LsmcBrkDecel_D_Stat 7 "NotUsed_3" 6 "NotUsed_2" 5 "NotUsed_1" 4 "Denied" 3 "FaultDegraded" 2 "FaultExt" 1 "On" 0 "Off" ;
VAL_TABLE_ StePinOffst_D_Stat 3 "FineOffset" 2 "CoarseOffset" 1 "StoredOffset" 0 "OffsetNotCalculated" ;
VAL_TABLE_ NoMessage_Override_Faulty 3 "NotUsed" 2 "Faulty" 1 "Override" 0 "NoMessage" ;
VAL_TABLE_ TrnIpcDsplyRng2_D_Actl 15 "No_Range_Selected" 14 "Range_14" 13 "Range_13" 12 "Range_12" 11 "Range_11" 10 "Range_10" 9 "Range_9" 8 "Range_8" 7 "Range_7" 6 "Range_6" 5 "Range_5" 4 "Range_4" 3 "Range_3" 2 "Range_2" 1 "Range_1" 0 "NotUsed" ;
VAL_TABLE_ OffOn_RampUpDown 3 "Ramp_Down" 2 "Ramp_Up" 1 "On" 0 "Off" ;
VAL_TABLE_ NoMessage_Msg1_7 7 "Message7" 6 "Message6" 5 "Message5" 4 "Message4" 3 "Message3" 2 "Message2" 1 "Message1" 0 "NoMessage" ;
VAL_TABLE_ LnchCtl 3 "NotUsed2" 2 "NotUsed1" 1 "LC_On" 0 "LC_Off" ;
VAL_TABLE_ BrkLineLck_D_Rq 3 "Off" 2 "Engage" 1 "Initiate" 0 "NoRequest" ;
VAL_TABLE_ BrkLineLck_D_Stat 7 "NotUsed_3" 6 "NotUsed_2" 5 "NotUsed_1" 4 "NotAvailable" 3 "Off" 2 "Engaged" 1 "Initiated" 0 "Available" ;
VAL_TABLE_ LnchCtlSys_D_Stat 7 "NotUsed" 6 "On_LC_Unavailable_TC_Off" 5 "On_LC_Available_TC_Off" 4 "On_LC_Unavailable_TC_On" 3 "On_LC_Unavailable" 2 "On_LC_Available" 1 "On_LC_Active" 0 "LC_OFF" ;
VAL_TABLE_ ActvFrontSteLck_D_Stat 3 "Test_passed" 2 "Test_failed" 1 "Test_cannot_run" 0 "Test_incomplete" ;
VAL_TABLE_ Rght_Lefthand_Traffic 1 "Left_Hand_Traffic" 0 "Right_Hand_Traffic" ;
VAL_TABLE_ NotPressed_Pressed_Faulty 3 "Faulty" 2 "NotUsed" 1 "Pressed" 0 "Not_Pressed" ;
VAL_TABLE_ TrlrTrgtAcquire_D_Rq 7 "NotUsed_2" 6 "NotUsed_1" 5 "ActivateRVCforTBA" 4 "CancelAcquisition" 3 "RetryAcquisition" 2 "AcquisitionSuccessful" 1 "StartAcquisition" 0 "Inactive" ;
VAL_TABLE_ TrlrTrgtAcquire_D_Stat 7 "Faulty" 6 "NotUsed_2" 5 "NotUsed_1" 4 "RVCforTBA_Activated" 3 "Processing" 2 "TargetNotAcquired" 1 "TargetAcquired" 0 "Null" ;
VAL_TABLE_ TrlBrkInitOut 3 "Heavy" 2 "Medium" 1 "Light" 0 "Null" ;
VAL_TABLE_ IsaOffst_D_Stat 15 "Faulty" 14 "Null" 13 "Thirteen" 12 "Twelve" 11 "Eleven" 10 "Ten" 9 "Nine" 8 "Eight" 7 "Seven" 6 "Six" 5 "Five" 4 "Four" 3 "Three" 2 "Two" 1 "One" 0 "Zero" ;
VAL_TABLE_ IsaVLimUnit_D_Rq 3 "NoDataExists" 2 "Mph" 1 "Kph" 0 "Null" ;
VAL_TABLE_ ApaChime_D_Rq 7 "NotUsed2" 6 "NotUsed1" 5 "Warning_Chime" 4 "Finish_Chime" 3 "Stop_Now_Chime" 2 "Spot_Ready_Chime" 1 "Spot_Found_Chime" 0 "No_Chime" ;
VAL_TABLE_ SlMde_D_Rq 3 "IsaNotConfigured" 2 "Manual_Mode" 1 "Auto_Mode" 0 "Null" ;
VAL_TABLE_ OffOn_NotUsed_NoData 3 "No_Data_Present" 2 "NotUsed" 1 "On" 0 "Off" ;
VAL_TABLE_ Faulty_FF 255 "Faulty" ;
VAL_TABLE_ BrkDrvMde_D_Rq 7 "Faulty" 6 "RockCrawl" 5 "Baja" 4 "DragOrMudAndSand" 3 "Track" 2 "Snow_Wet" 1 "Sport" 0 "Normal" ;
VAL_TABLE_ TrnIpcDsplyRng_D_Stat 3 "NotUsed" 2 "Flash" 1 "On" 0 "Blank_No_Display" ;
VAL_TABLE_ NoYesNoDataFaulty 3 "Faulty" 2 "NoDataExists" 1 "Yes" 0 "No" ;
VAL_TABLE_ SidePrkSnsR4_D_Stat 15 "NotUsed" 14 "NotFullyScannedYet" 13 "NoObjectInSector" 12 "Zone12" 11 "Zone11" 10 "Zone10" 9 "Zone9" 8 "Zone8" 7 "Zone7" 6 "Zone6" 5 "Zone5" 4 "Zone4" 3 "Zone3" 2 "Zone2" 1 "Zone1" 0 "Off" ;
VAL_TABLE_ TsrVlPrmntMsgTxt_D_Rq 3 "NotUsed" 2 "ShowPermanentlyWithSupp" 1 "ShowPermanentlyWithoutSupp" 0 "DoNotShowSignPermanent" ;
VAL_TABLE_ TsrVl1RstrcMsgTxt2_D_Rq 7 "NotUsed" 6 "Time" 5 "Trailer" 4 "Snow" 3 "RainWet" 2 "NoRecognizableRestrictn" 1 "NoSpeedLimitRestrictn" 0 "Null" ;
VAL_TABLE_ PtDrvMde_D_Rq 15 "Faulty" 14 "NotUsed11" 13 "NotUsed10" 12 "NotUsed9" 11 "NotUsed8" 10 "NotUsed7" 9 "NotUsed6" 8 "Track" 7 "Drag" 6 "Rock" 5 "Baja" 4 "Sand" 3 "TowHaulGradeAssist" 2 "SnowWet" 1 "Sport" 0 "Normal" ;
VAL_TABLE_ SteEffort_D_Stat 7 "NotUsed_3" 6 "NotUsed_2" 5 "NotUsed_1" 4 "SpecialMode_2" 3 "SpecialMode_1" 2 "Comfort" 1 "Sport" 0 "Normal" ;
VAL_TABLE_ TsrOvtkMsgTxt2_D_Rq 15 "NotUsed5" 14 "NotUsed4" 13 "NotUsed3" 12 "NotUsed2" 11 "NotUsed1" 10 "LimForTrucksCancelled" 9 "LimForTrucksWoQlfdRstrc" 8 "LimForTrucksWithoutRstrc" 7 "LimAllCancelled" 6 "LimAllWithRstrcTime" 5 "LimAllWithRstrcTrailer" 4 "LimAllWithRstrcSnow" 3 "LimAllWithRstrcRain" 2 "LimAllWithoutQlfdRstrc" 1 "LimAllWithoutRestriction" 0 "OvertakingAllowed" ;
VAL_TABLE_ TrlrAnOffstDir 3 "NotUSed" 2 "Right" 1 "Left_or_Center" 0 "Null" ;
VAL_TABLE_ Null_Off_On 3 "NotUsed" 2 "On" 1 "Off" 0 "Null" ;
VAL_TABLE_ TrlrBrkMde_D_Rq 1 "ElectricOverHydraulic" 0 "Electric" ;
VAL_TABLE_ Invalid_Off_On 0 "Invalid" 1 "Off" 2 "On" ;
VAL_TABLE_ ACU_RadioError_St 0 "Invalid" 1 "NoError" 2 "PiNotFound" 3 "PtyNotFound" ;
VAL_TABLE_ ACU_HardwareError_St 0 "Invalid" 1 "NoError" 2 "EepromReadError" 3 "KeycodeLocked" 4 "KeycodeLockedForever" 5 "CommunicationError" 6 "OverTemperature" 7 "FocusError" ;
VAL_TABLE_ ACU_CurrentRadioBand_St 6 "Fm3" 0 "Invalid" 1 "Fm1" 2 "Fm2" 3 "FmAst" 4 "Am" 5 "AmAst" ;
VAL_TABLE_ ACU_AFMode_St 0 "Invalid" 1 "AfOn" 2 "AfOff" 3 "Auto" ;
VAL_TABLE_ TrlrAidSetup_D_Stat 7 "Faulty" 6 "NotUsed_3" 5 "NotUsed_2" 4 "NotUsed_1" 3 "EnterParameters" 2 "EndSetup" 1 "BeginSetup" 0 "Null" ;
VAL_TABLE_ TrlrAidMsgTxt_D_Rq 31 "Message31" 30 "Message30" 29 "Message29" 28 "Message28" 27 "Message27" 26 "Message26" 25 "Message25" 24 "Message24" 23 "Message23" 22 "Message22" 21 "Message21" 20 "Message20" 19 "Message19" 18 "Message18" 17 "Message17" 16 "Message16" 15 "Message15" 14 "Message14" 13 "Message13" 12 "Message12" 11 "Message11" 10 "Message10" 9 "Message9" 8 "Message8" 7 "Message7" 6 "Message6" 5 "Message5" 4 "Message4" 3 "Message3" 2 "Message2" 1 "Message1" 0 "NoMessage" ;
VAL_TABLE_ Invalid_7F 127 "Invalid" ;
VAL_TABLE_ Faulty_1FFF 8191 "Faulty" ;
VAL_TABLE_ VehStab_D_Stat 15 "Faulty" 14 "No_Data_Exists" 13 "NotUsed6" 12 "NotUsed5" 11 "NotUsed4" 10 "NotUsed3" 9 "NotUsed2" 8 "Combined_OS_and_US" 7 "High_SSRA_no_OS" 6 "Straight" 5 "Post_Oversteer" 4 "Post_Transition" 3 "Countersteer" 2 "Understeer" 1 "Oversteer" 0 "Linear" ;
VAL_TABLE_ NoData_Faulty_1FF_1FE 511 "Faulty" 510 "NoDataExists" ;
VAL_TABLE_ Null_Hi_NotUsed_Low 3 "Low" 2 "Not_Used" 1 "High" 0 "Null" ;
VAL_TABLE_ Current_Color 15 "NotUsed7" 14 "NotUsed6" 13 "NotUsed5" 12 "NotUsed4" 11 "NotUsed3" 10 "NotUsed2" 9 "NotUsed1" 8 "Null" 7 "Color7" 6 "Color6" 5 "Color5" 4 "Color4" 3 "Color3" 2 "Color2" 1 "Color1" 0 "Off" ;
VAL_TABLE_ Blended_Color 15 "NotUsed10" 14 "NotUsed9" 13 "NotUsed8" 12 "NotUsed7" 11 "NotUsed6" 10 "NotUsed5" 9 "NotUsed4" 8 "NotUsed3" 7 "NotUsed2" 6 "NotUsed1" 5 "_5" 4 "_4" 3 "_3" 2 "_2" 1 "_1" 0 "Null" ;
VAL_TABLE_ OffOn_Null_NotUsed 3 "NotUsed" 2 "Null" 1 "On" 0 "Off" ;
VAL_TABLE_ Null_Pers1_4_Vehicle 7 "Unused_2" 6 "Unused_1" 5 "Vehicle" 4 "PERS_4" 3 "PERS_3" 2 "PERS_2" 1 "PERS_1" 0 "Null" ;
VAL_TABLE_ PrkLckCtlEnbl_D_RqIpc 3 "Rq_Towing" 2 "Rq_Enable" 1 "Rq_Disable" 0 "Null" ;
VAL_TABLE_ PrkLckCtlUnlck_D_Stat 3 "Trans_And_Steer_Unlckd" 2 "Steering_Unlckd" 1 "Transmission_Unlckd" 0 "Null" ;
VAL_TABLE_ VehKeyActv_D_Stat 15 "NotUsed7" 14 "NotUsed6" 13 "NotUsed5" 12 "NotUsed4" 11 "NotUsed3" 10 "NotUsed2" 9 "NotUsed1" 8 "Key8Active" 7 "Key7Active" 6 "Key6Active" 5 "Key5Active" 4 "Key4Active" 3 "Key3Active" 2 "Key2Active" 1 "Key1Active" 0 "NoKeyActive" ;
VAL_TABLE_ VehLckInd_D_Rq 3 "NotUsed" 2 "On_Day" 1 "On_Night" 0 "Off" ;
VAL_TABLE_ PrkBrkDynmc_D_Allw 3 "NotUsed" 2 "EPB_ECD_NotPossible" 1 "EPB_ECD_Possible" 0 "Used_at_Start_Up" ;
VAL_TABLE_ TowBarMsgTxt_D_Rq 7 "NotUsed3" 6 "NotUsed2" 5 "NotUsed1" 4 "TowBar_Ext_No_Trlr" 3 "Error_Dealer_Fix" 2 "Start_Engine_Swivel" 1 "Check_Tow_Bar" 0 "Null" ;
VAL_TABLE_ NoData_Faulty_3E_3F 63 "Faulty" 62 "NoDataExists" ;
VAL_TABLE_ Faulty_1FF 511 "Faulty" ;
VAL_TABLE_ NoData_Faulty_1FFF_1FFE 8191 "Faulty" 8190 "NoDataExists" ;
VAL_TABLE_ Null_Off_On_Faulty 3 "Faulty" 2 "On" 1 "Off" 0 "Null" ;
VAL_TABLE_ AirSusp_D_RqDrv 3 "NotUsed" 2 "On" 1 "Off" 0 "NoModeSelected" ;
VAL_TABLE_ AwdSys_D_Stat 3 "Faulty" 2 "NotUsed" 1 "_4x4_L_H_Active" 0 "_4x4_L_H_Inactive" ;
VAL_TABLE_ AutoRgen_D_Rq 3 "NotUsed" 2 "AutExhFilterCleanOFF" 1 "AutExhFilterCleanON" 0 "No_Mode_Selected" ;
VAL_TABLE_ TrnSrvcRqd_B_Rq 1 "On" 0 "Off" ;
VAL_TABLE_ immoSecureIdleMode 3 "NotUsed2" 2 "NotUsed1" 1 "Active" 0 "Inactive" ;
VAL_TABLE_ SteMdule_D_Stat 7 "NotUsed" 6 "EPAS_Failure3" 5 "EPAS_Failure2" 4 "System_Failure" 3 "EPAS_Shutdown" 2 "Normal_Op_Full_Assist" 1 "Normal_Op_Limited_Assist" 0 "EPAS_Initialization" ;
VAL_TABLE_ Faulty_FFF 4095 "Faulty" ;
VAL_TABLE_ Faulty_3FF 1023 "Faulty" ;
VAL_TABLE_ NoData_Faulty_FE_FF 255 "Faulty" 254 "NoDataExists" ;
VAL_TABLE_ TrnLvrV_D_Rq 3 "Full_Speed" 2 "Aggressive" 1 "Normal" 0 "Quiet" ;
VAL_TABLE_ DynoMde_B_Cmd 1 "DynomometerMode" 0 "NormalOperation" ;
VAL_TABLE_ HybMdeStat_D_Dsply 7 "NotUsed2" 6 "EV_Charge" 5 "EV_Override" 4 "Forced_EV_Mode" 3 "Forced_Charge_Sustain_Mode" 2 "Auto_Charge_Sustain_Mode" 1 "Auto_Charge_Deplete_Mode" 0 "Null_State" ;
VAL_TABLE_ PwFlowPlgBatt_D_Dsply 3 "NotUsed" 2 "Flow_from_Plug_to_Batt" 1 "Flow_from_Batt_to_Plug" 0 "No_Flow" ;
VAL_TABLE_ PwFlowEngMtr_D_Dsply 3 "NotUsed" 2 "Flow_from_Eng_to_Mtr" 1 "Flow_from_Mtr_to_Eng" 0 "No_Flow" ;
VAL_TABLE_ PwFlowEngFuel_D_Dsply 3 "NotUsed" 2 "Flow_from_Eng_to_Fuel" 1 "Flow_from_Fuel_to_Eng" 0 "No_Flow" ;
VAL_TABLE_ PwFlowMtrDrv_D_Dsply 3 "NotUsed" 2 "Flow_from_Mtr_to_Axle" 1 "Flow_from_Axle_to_Mtr" 0 "No_FLow" ;
VAL_TABLE_ PwFlowEngDrv_D_Dsply 3 "NotUsed" 2 "Flow_from_Eng_to_Axle" 1 "Flow_from_Axle_to_Eng" 0 "No_Flow" ;
VAL_TABLE_ PwFlowBattMtr_D_Dsply 3 "NotUsed" 2 "Flow_from_Batt_to_Mtr" 1 "Flow_from_Mtr_to_Batt" 0 "No_Flow" ;
VAL_TABLE_ CenterStackRing_D_Actl 3 "LimitedOn" 2 "On" 1 "Off" 0 "Null" ;
VAL_TABLE_ NoData_Faulty_FFFE_FFFF 65535 "Faulty" 65534 "NoDataExists" ;
VAL_TABLE_ NoData_Faulty_FFE_FFF 4095 "Faulty" 4094 "NoDataExists" ;
VAL_TABLE_ NoData_Faulty_3FE_3FF 1023 "Faulty" 1022 "NoDataExists" ;
VAL_TABLE_ OffOn_NotUsed 3 "NotUsed2" 2 "NotUsed1" 1 "On" 0 "Off" ;
VAL_TABLE_ DrQltyDrv_D_StatGsm 7 "Faulty" 6 "NoDataExists" 5 "NotUsed2" 4 "NotUsed1" 3 "ClosedDegraded" 2 "OpenDegraded" 1 "ClosedOkay" 0 "OpenOkay" ;
VAL_TABLE_ BattTracLoThres_D_Stat 7 "NotUsed" 6 "Thres80km_50mi" 5 "Thres50km_31mi" 4 "Thres30km_18mi" 3 "Thres50mi_80km" 2 "Thres30mi_48km" 1 "Thres20mi_32km" 0 "Null" ;
VAL_TABLE_ KeyPadCodeDgt1_D_Stat 15 "NotUsed_4" 14 "NotUsed_3" 13 "NotUsed_2" 12 "NotUsed_1" 11 "Button7_8and9_0" 10 "Button0" 9 "Button9_0or9" 8 "Button8" 7 "Button7_8or7" 6 "Button6" 5 "Button5_6or5" 4 "Button4" 3 "Button3_4or3" 2 "Button2" 1 "Button1_2or1" 0 "EndofString" ;
VAL_TABLE_ OrtaMde_D_Ind 2 "StandbyRight" 1 "StandbyLeft" 0 "Off" 7 "Faulty" 6 "NotUsed_2" 5 "NotUsed_1" 4 "ActiveRight" 3 "ActiveLeft" ;
VAL_TABLE_ SelDrvMde_1_31 31 "Faulty" 30 "SelDrvMde31" 29 "SelDrvMde30" 28 "SelDrvMde29" 27 "SelDrvMde28" 26 "SelDrvMde27" 25 "SelDrvMde26" 24 "SelDrvMde25" 23 "SelDrvMde24" 22 "SelDrvMde23" 21 "SelDrvMde22" 20 "SelDrvMde21" 19 "SelDrvMde20" 18 "SelDrvMde19" 17 "SelDrvMde18" 16 "SelDrvMde17" 15 "SelDrvMde16" 14 "SelDrvMde15" 13 "SelDrvMde14" 12 "SelDrvMde13" 11 "SelDrvMde12" 10 "SelDrvMde11" 9 "SelDrvMde10" 8 "SelDrvMde09" 7 "SelDrvMde08" 6 "SelDrvMde07" 5 "SelDrvMde06" 4 "SelDrvMde05" 3 "SelDrvMde04" 2 "SelDrvMde03" 1 "SelDrvMde02" 0 "SelDrvMde01" ;
VAL_TABLE_ PwRnngBoardT_D_Rq 3 "NotUsed" 2 "Timer2" 1 "Timer1" 0 "Inactive" ;
VAL_TABLE_ ApaSteScanMde_D_Stat 0 "Null" 1 "NotScanning" 2 "Scanning" 3 "Steering" ;
VAL_TABLE_ PwRnngBoardT_D_Stat 3 "NotUsed" 2 "Timer2" 1 "Timer1" 0 "Inactive" ;
VAL_TABLE_ OffPendingActiveNotUsed 3 "NotUsed" 2 "Active" 1 "Pending" 0 "Off" ;
VAL_TABLE_ NotDeterminedNotPresentFaulty 3 "Faulty" 2 "Present" 1 "NotPresent" 0 "NotDetermined" ;
VAL_TABLE_ OtaActv_D_Stat 15 "NotUsed_10" 14 "NotUsed_9" 13 "NotUsed_8" 12 "NotUsed_7" 11 "NotUsed_6" 10 "NotUsed_5" 9 "NotUsed_4" 8 "NotUsed_3" 7 "NotUsed_2" 6 "NotUsed_1" 5 "NonInterruptible_Pending" 4 "NonInterruptible_Config" 3 "NonInterruptible_ER" 2 "NonInterruptible_AB" 1 "Interruptible_AB" 0 "NoInVehicleOta" ;
VAL_TABLE_ PwRnngBoardPoll_D_Stat 3 "NotUsed" 2 "PkPresent" 1 "PkNotPresent" 0 "NotPolling" ;
VAL_TABLE_ InactiveOffOutAuto 0 "Inactive" 1 "Off" 2 "Out" 3 "Auto" ;
VAL_TABLE_ PwRnngBoardSwtch_D_Rq 3 "NotUsed" 2 "DeployUnlocked" 1 "AlwaysActive" 0 "Inactive" ;
VAL_TABLE_ LongCtrlEnbl_D_Rq 7 "Faulty" 6 "NotUsed_3" 5 "NotUsed_2" 4 "NotUsed_1" 3 "RemoteParking" 2 "Autohitch" 1 "AutomaticParking" 0 "None" ;
VAL_TABLE_ BrkHold_D_Stat 7 "NotUsed_3" 6 "NotUsed_2" 5 "NotUsed_1" 4 "HeldSecondary" 3 "HeldSecure" 2 "Held" 1 "Inactive" 0 "Off" ;
VAL_TABLE_ AccStopStat_D_Dsply 3 "PressResume" 2 "Stopped" 1 "ResumeReady" 0 "NoDisplay" ;
VAL_TABLE_ Null_Left_Right 3 "NotUsed" 2 "Right" 1 "Left" 0 "Null" ;
VAL_TABLE_ TrlrHitch_D_RqMnu 15 "NotUsed_10" 14 "NotUsed_9" 13 "NotUsed_8" 12 "NotUsed_7" 11 "NotUsed_6" 10 "NotUsed_5" 9 "NotUsed_4" 8 "NotUsed_3" 7 "NotUsed_2" 6 "NotUsed_1" 5 "GoToTraileringDomain" 4 "Confirm" 3 "TurnOnTba" 2 "TurnOnAutohitch" 1 "CancelAutohitch" 0 "NoRequest" ;
VAL_TABLE_ NotFaulted_Faulted 1 "Faulted" 0 "NotFaulted" ;
VAL_TABLE_ Null_NotAccepted_Accepted 3 "NotUsed" 2 "Accepted" 1 "NotAccepted" 0 "Null" ;
VAL_TABLE_ NotAvailable_Available_GreyedOut 3 "NotUsed" 2 "GreyedOut" 1 "Available" 0 "NotAvailable" ;
VAL_TABLE_ LatCtl_D2_Rq 7 "NotUsed_5" 6 "NotUsed_4" 5 "NotUsed_3" 4 "NotUsed_2" 3 "SafeRampOut" 2 "PathFollowingExtendedMode" 1 "PathFollowingLimitedMode" 0 "NoLateralControl" ;
VAL_TABLE_ DrvEngageLevel_D_Stat 7 "Faulty" 6 "NotUsed_2" 5 "NotUsed_1" 4 "Disengaged" 3 "Distracted" 2 "Attentive" 1 "Invalid" 0 "NotDetermined" ;
VAL_TABLE_ DrvImpairLvl_D_Stat 15 "Faulty" 14 "NotUsed_5" 13 "NotUsed_4" 12 "NotUsed_3" 11 "NotUsed_2" 10 "NotUsed_1" 9 "Incapacitated" 8 "Asleep" 7 "Microsleep" 6 "MostDrowsy" 5 "Drowsy_4" 4 "Drowsy_3" 3 "Drowsy_2" 2 "LeastDrowsy" 1 "Alert" 0 "NotDetermined" ;
VAL_TABLE_ DrvAttentZone_D_Stat 15 "Faulty" 14 "NotUsed_5" 13 "NotUsed_4" 12 "NotUsed_3" 11 "NotConfigured" 10 "DriverLap" 9 "PassengerSideWindow" 8 "DriverSideWindow" 7 "DriverSideMirror" 6 "RearviewMirror" 5 "PassengerSideMirror" 4 "Infotainment" 3 "Cluster" 2 "FrontWindshield" 1 "Other" 0 "NotDetermined" ;
VAL_TABLE_ DrvAlertSt_D_Stat 3 "Faulty" 2 "EyesOffRoad" 1 "EyesOnRoad" 0 "NotDetermined" ;
VAL_TABLE_ DrvEngLvlConfid_D_Stat 7 "Faulty" 6 "NotUsed" 5 "High" 4 "MediumHigh" 3 "Medium" 2 "LowMedium" 1 "Low" 0 "NotDetermined" ;
VAL_TABLE_ DrvCamIR_D_Stat 3 "Faulty" 2 "Blocked" 1 "Ok" 0 "TemporaryUnavailable" ;
VAL_TABLE_ PoliceDmngLvl_D_Stat 7 "NotUsed" 6 "Off_Night" 5 "Off_Day" 4 "Low1Night" 3 "Low1Day" 2 "Inactive" 1 "Decommissioned" 0 "Null" ;
VAL_TABLE_ AdbBeam_D_Rq 7 "NotUsed_3" 6 "NotUsed_2" 5 "NotUsed_1" 4 "FullHighBeam" 3 "Spot_BothSide" 2 "Spot_OnlyRightSide" 1 "Spot_OnlyLeftSide" 0 "NoHighBeam" ;
VAL_TABLE_ NoRequest_Up 1 "Up" 0 "NoRequest" ;
VAL_TABLE_ VehWlcmFrwl_D_Stat 3 "RunStart" 2 "Farewell" 1 "Welcome" 0 "Null" ;
VAL_TABLE_ VehWlcmFrwlMde_D_Stat 7 "IlluminatedExit" 6 "CourtesyLightingDelayExt" 5 "CourtesyLightingExtended" 4 "CourtesyLightingDelayAll" 3 "CourtesyLightingAll" 2 "IlluminatedEntry" 1 "Approach" 0 "Null" ;
VAL_TABLE_ OnePdlDrv_D_Stat 3 "Enabled_BrkLampAndFbrk" 2 "Enabled_BrkLamp" 1 "Enabled_NoAction" 0 "Disabled" ;
VAL_TABLE_ LatCtlCpblty_D_Stat 3 "Faulty" 2 "ExtendedModeAvailable" 1 "LimitedModeAvailable" 0 "NoModeAvailable" ;
VAL_TABLE_ TsrRegionTxt_D_Stat 31 "Faulty" 30 "NotUsed_8" 29 "NotUsed_7" 28 "NotUsed_6" 27 "NotUsed_5" 26 "NotUsed_4" 25 "NotUsed_3" 24 "NotUsed_2" 23 "NotUsed_1" 22 "Region_22" 21 "Region_21" 20 "Region_20" 19 "Region_19" 18 "Region_18" 17 "Region_17" 16 "Region_16" 15 "Region_15" 14 "Region_14" 13 "Region_13" 12 "Region_12" 11 "Region_11" 10 "Region_10" 9 "Region_09" 8 "Region_08" 7 "Region_07" 6 "Region_06" 5 "Region_05" 4 "Region_04" 3 "Region_03" 2 "Region_02" 1 "Region_01" 0 "NotDetermined" ;
VAL_TABLE_ TrlrAidEnbl_D_RqAdas 7 "NotUsed_4" 6 "NotUsed_3" 5 "NotUsed_2" 4 "NotUsed_1" 3 "Deactivate" 2 "NotAvailable" 1 "ActiveTba" 0 "Inactive" ;
VAL_TABLE_ TrlrHitchIcon_D_Rq 15 "Icon15" 14 "Icon14" 13 "Icon13" 12 "Icon12" 11 "Icon11" 10 "Icon10" 9 "Icon9" 8 "Icon8" 7 "Icon7" 6 "Icon6" 5 "Icon5" 4 "Icon4" 3 "Icon3" 2 "Icon2" 1 "Icon1" 0 "NoIcon" ;
VAL_TABLE_ TrlrHitchChime_D_Rq 7 "NotUsed_1" 6 "NotUsed_1" 5 "WarningChime" 4 "NonCriticalAlertChime" 3 "StopNowChime" 2 "ManeuveringReadyChime" 1 "TrailerFoundChime" 0 "NoChime" ;
VAL_TABLE_ _S_No_Yes 1 "Yes" 0 "No" ;
VAL_TABLE_ UpDownNotUsedFaulty 3 "Faulty" 2 "NotUsed" 1 "Down" 0 "Up" ;
VAL_TABLE_ PtWakeReas_D_Stat 15 "NotUsed_9" 14 "NotUsed_8" 13 "NotUsed_7" 12 "NotUsed_6" 11 "NotUsed_5" 10 "NotUsed_4" 9 "NotUsed_3" 8 "NotUsed_2" 7 "NotUsed_1" 6 "ElapsedTime" 5 "ThirdPartyWakeup" 4 "DoorAjar" 3 "EarlyWake" 2 "NonMotiveStart" 1 "MotiveStart" 0 "Null" ;
VAL_TABLE_ ExtLght_D_Falt 3 "Error" 2 "NoStationary" 1 "StartEngine" 0 "Null" ;
VAL_TABLE_ MemStoreMsgTxt_D_Rq 10 "NotUsed_2" 9 "NotUsed_1" 8 "Mem4Saved_ShowLinkMsg" 7 "Mem3Saved_ShowLinkMsg" 6 "Mem2Saved_ShowLinkMsg" 5 "Mem1Saved_ShowLinkMsg" 4 "Mem4Saved_DoNotShowLinkMsg" 3 "Mem3Saved_DoNotShowLinkMsg" 2 "Mem2Saved_DoNotShowLinkMsg" 1 "Mem1Saved_DoNotShowLinkMsg" 0 "Null" ;
VAL_TABLE_ MemSetButtnMsgTxt_D_Rq 3 "NotUsed" 2 "Press1or2or3" 1 "Press1or2" 0 "Null" ;
VAL_TABLE_ MildHybStat_D_Dsply 7 "NotUsed" 6 "Recovery" 5 "Charge" 4 "Assist" 3 "Boost" 2 "SystemInhibited" 1 "SystemError" 0 "Off" ;
VAL_TABLE_ InfotainmentAudio_St 3 "NotUsed" 2 "ErrorState_NoAudio" 1 "NormalOperation" 0 "Null" ;
VAL_TABLE_ BattTracClntVlv_D_Stat 7 "FetLowSideOpenOrShort" 6 "FetLifeLimitReached" 5 "FetOpenCircuit" 4 "FetOutputShortToPower" 3 "FetOutputShortToGround" 2 "FetNotControlled" 1 "OnPowerToLoad" 0 "OffNoPowerToLoad" ;
VAL_TABLE_ NoReqHiDecelLowDecel 3 "NotUsed" 2 "LowDecel" 1 "HighDecel" 0 "NoRequest" ;
VAL_TABLE_ OpenClosedRetainDisable 3 "Disable" 2 "Retain" 1 "Closed" 0 "Open" ;
VAL_TABLE_ DrTgateChime2_D_Rq 7 "NotUsed3" 6 "NotUsed2" 5 "NotUsed1" 4 "Long_Repeated" 3 "Fast" 2 "Short" 1 "Long" 0 "Off" ;
VAL_TABLE_ DrvPerfMde 3 "Sport" 2 "Normal" 1 "NotUsed" 0 "NoModeSelected" ;
VAL_TABLE_ NoData_Fault_1FF_1FE 511 "Fault" 510 "NoDataExists" ;
VAL_TABLE_ NoData_Fault_FFE_FFF 4095 "Fault" 4094 "NoDataExists" ;
VAL_TABLE_ StopStrtDrvMde_D_Indic 3 "NotUsed" 2 "StartStop_IndirectDeselect" 1 "StopStart_Deselected" 0 "StopStart_Selected" ;
VAL_TABLE_ StopStrtDrvMde_D_RqMnu 3 "NotUsed2" 2 "NotUsed1" 1 "StopStart_Deselected" 0 "StopStart_Selected" ;
VAL_TABLE_ StopStrtStdby_D_Indic 6 "Telltale_On_Grey" 5 "Telltale_Struck_Out" 4 "Telltale_Flashing_Amber" 3 "Telltale_On_Amber" 2 "Telltale_Flashing_Green" 1 "Telltale_On_Green" 0 "Telltale_Off" 7 "NotUsed3" ;
VAL_TABLE_ Quality_Faulty 3 "OK" 2 "Degraded" 1 "No_Data_Exists" 0 "Faulty" ;
VAL_TABLE_ TrnDtpCmd_D_Actl 7 "NotUsed4" 6 "NotUsed3" 5 "NotUsed2" 4 "Relatch" 3 "Deploy" 2 "Self_Test" 1 "No_Command" 0 "NotUsed1" ;
VAL_TABLE_ TrnGsmNtmState_D_Actl 3 "Faulty" 2 "Neutral_Tow_Mode" 1 "Car_Wash_Mode" 0 "None" ;
VAL_TABLE_ TrnTrcmPwmSig_D_Actl 15 "Faulty" 14 "NoDataExists" 13 "NotUsed5" 12 "NotUsed4" 11 "NotUsed3" 10 "NotUsed2" 9 "NotUsed1" 8 "Default_To_Park" 7 "Neutral_Tow" 6 "Car_Wash_Mode" 5 "Manual" 4 "Drive" 3 "Neutral" 2 "Reverse" 1 "Park" 0 "No_Gear" ;
VAL_TABLE_ Fault_3FFF 16383 "Fault" ;
VAL_TABLE_ CtaInnr_D_Stat 3 "Reporting" 2 "Not_Reporting" 1 "System_Standby" 0 "Initialization" ;
VAL_TABLE_ PrkBrkActv_D_RqTrnGear 3 "NotUsed2" 2 "RequestParkBrakeEngage" 1 "NoRequest" 0 "NotUsed1" ;
VAL_TABLE_ NoRequest_Request 1 "Request" 0 "NoRequest" ;
VAL_TABLE_ Fault_FFF_NoData 4094 "NoDataExists" 4095 "Fault" ;
VAL_TABLE_ Fault_3FF_NoData 1022 "NoDataExists" 1023 "Fault" ;
VAL_TABLE_ ICI_Coding_BtnID_A 15 "Idle" 5 "Stuck" 4 "LongEvent" 3 "ShortElapsed" 2 "ShortEvent" 1 "Active" 0 "Inactive" ;
VAL_TABLE_ Foh_D_Stat 7 "Unused3" 6 "Unused2" 5 "Unused1" 4 "Stopping" 3 "Running" 2 "Starting" 1 "Prestart" 0 "Off" ;
VAL_TABLE_ ActiveStoragePassenger 7 "Unused3" 6 "Unused2" 5 "Unused1" 4 "StoreDipMemoryButton4" 3 "StoreDipMemoryButton3" 2 "StoreDipMemoryButton2" 1 "StoreDipMemoryButton1" 0 "Off" ;
VAL_TABLE_ DipMirror 1 "Dipped" 0 "Off" ;
VAL_TABLE_ WindowCmd 7 "Unused2" 6 "Unused1" 5 "NotDefined" 4 "Audo_Down" 3 "Manual_Down" 2 "Auto_Up" 1 "Manual_Up" 0 "Idle" ;
VAL_TABLE_ MirrorCmd 7 "Unused" 6 "Unfold" 5 "Fold" 4 "Right" 3 "Left" 2 "Down" 1 "Up" 0 "Idle" ;
VAL_TABLE_ WindowPosition 7 "Unused2" 6 "Unused1" 5 "Fully_Open" 4 "Bet60Percent_FullyOpen" 3 "Bet10Percent_60Percent" 2 "BetFully_10PercentOpen" 1 "Fully_Closed" 0 "Undefined" ;
VAL_TABLE_ OffOnNoDataUnused 3 "Unused" 2 "NoDataExists" 1 "On" 0 "Off" ;
VAL_TABLE_ FohFalt_D_Stat 15 "NotUsed4" 14 "NotUsed3" 13 "NotUsed2" 12 "NotUsed1" 11 "FuelTypeDoesNotMatchFOH" 10 "Lifecycle_ModeNotSet" 9 "AuxElectricCoolantPumpInop" 8 "TimeDelayAvoidExcessCycl" 7 "Fuel_Level_OutofRange" 6 "External_Fault" 5 "Internal_Fault" 4 "Voltage_limitation" 3 "Impact_Event" 2 "CoolantTemp_OutofRange" 1 "AmbientTemp_OutofRange" 0 "No_Disable" ;
VAL_TABLE_ FohRqRun_B_Rq 1 "SubmitRequest_toRun" 0 "DoesNotSubmitRequest_toRun" ;
VAL_TABLE_ OKLowVeryLow 3 "NotUsed" 2 "VeryLow" 1 "Low" 0 "OK" ;
VAL_TABLE_ Fault_1FF 511 "Fault" ;
VAL_TABLE_ SteWhlHeat 15 "NotUsed6" 14 "NotUsed5" 13 "NotUsed4" 12 "NotUsed3" 11 "NotUsed2" 10 "NotUsed1" 9 "Reserved_3" 8 "Reserved_2" 7 "Reserved_1" 6 "Level_3_Heating" 5 "Level_3_Heating_LS" 4 "Level_2_Heating" 3 "Level_2_Heating_LS" 2 "Level_1_Heating" 1 "Level_1_Heating_LS" 0 "Off" ;
VAL_TABLE_ OffOnUnusedFault 3 "Fault" 2 "Unused" 1 "On" 0 "Off" ;
VAL_TABLE_ NullKphMph 3 "NoDataExists" 2 "Mph" 1 "Kph" 0 "Null" ;
VAL_TABLE_ TsrVLim1MsgTxt_D_Rq 255 "NoLimit" 254 "NotUsed2" 253 "NotUsed1" 252 "NotToBeDisplayed" 251 "LimitCancelled" 31 "1F_FA_Message31_250" 30 "Message30" 29 "Message29" 28 "Message28" 27 "Message27" 26 "Message26" 25 "Message25" 24 "Message24" 23 "Message23" 22 "Message22" 21 "Message21" 20 "Message20" 19 "Message19" 18 "Message18" 17 "Message17" 16 "Message16" 15 "Message15" 14 "Message14" 13 "Message13" 12 "Message12" 11 "Message11" 10 "Message10" 9 "Message9" 8 "Message8" 7 "Message7" 6 "Message6" 5 "Message5" 4 "Message4" 3 "Message3" 2 "Message2" 1 "Message1" 0 "Null" ;
VAL_TABLE_ TsrVl1RstrcMsgTxt_D_Rq 3 "NotUsed" 2 "NoRecognizableRestriction" 1 "NoSpeedLimitRestriction" 0 "Null" ;
VAL_TABLE_ TsrMsgTxt_D_Rq 15 "NotUsed6" 14 "NotUsed5" 13 "NotUsed4" 12 "NotUsed3" 11 "NotUsed2" 10 "NotUsed1" 9 "RecgnzdSignNotUsblForDsply" 8 "LimitedSystemPerformance" 7 "OffRoad" 6 "RegionNotSupported" 5 "CountryNotSupported" 4 "WrngNavDatIncompDatCarrier" 3 "NoNavDataAvailable" 2 "NoNavAvailableSwitchedOff" 1 "NoInformationAllOK" 0 "Null" ;
VAL_TABLE_ TsrOvtkStatMsgTxt_D_Rq 3 "LimitOutdated" 2 "LimitReiable" 1 "LimitChanged" 0 "Null" ;
VAL_TABLE_ TsrOvtkMsgTxt_D_Rq 7 "LimForTrucksCancelled" 6 "LimForTrucksWoQlfdRstrc" 5 "LimForTrucksWithoutRstrc" 4 "LimAllCancelled" 3 "LimAllWithoutQlfdRstrc" 2 "LimAllWithoutRestriction" 1 "OvertakingAllowed" 0 "Null" ;
VAL_TABLE_ Null_False_True 3 "NotUsed" 2 "True" 1 "False" 0 "Null" ;
VAL_TABLE_ TsrStatMsgTxt_D_Rq 7 "NotUsed" 6 "NoDataExists" 5 "TSR_Error" 4 "Available_NavigationOnly" 3 "Available_CameraOnly" 2 "Available_FusionMode" 1 "TSR_Off" 0 "Null" ;
VAL_TABLE_ NoMessage_DisplayMessage 1 "DisplayMessage" 0 "NoMessage" ;
VAL_TABLE_ EngineBrakeOff_Active 1 "Engine_Braking_Activated" 0 "Engine_Braking_Off" ;
VAL_TABLE_ Allowed_Denied 1 "Denied" 0 "Allowed" ;
VAL_TABLE_ PrkAidMsgTxt_D_Rq 15 "All_Sns_Blk" 14 "R_Sns_ON_F_Sns_Blk" 13 "R_Sns_Blk_F_Sns_ON" 12 "R_Sns_Inactive_Trlr_atch" 11 "Not_Avail_Trlr_attchd" 10 "Fail_Mode_no_Chime" 9 "Fail_Mode_with_Chime" 8 "R_Sns_Trlr_F_Sns_Blk" 7 "NotUsed3" 6 "Park_Sys_Alternate_Mode" 5 "R_Snsrs_On_F_Snsrs_On" 4 "NotUsed2" 3 "Reset_Message_Warn" 2 "R_Snsrs_Off_F_Snsrs_On" 1 "R_Snsrs_On_F_Snsrs_Off" 0 "All_Park_Sensors_Off" ;
VAL_TABLE_ PrkAidSns_D_Stat 15 "Zone_15" 14 "Zone_14" 13 "Zone_13" 12 "Zone_12" 11 "Zone_11" 10 "Zone_10" 9 "Zone_9" 8 "Zone_8" 7 "Zone_7" 6 "Zone_6" 5 "Zone_5" 4 "Zone_4" 3 "Zone_3" 2 "Zone_2" 1 "Zone_1" 0 "Off" ;
VAL_TABLE_ PrkAid_D_Falt 7 "NotUsed2" 6 "NotUsed1" 5 "Failure_Front_PSM_Sensors" 4 "No_Data_Exists" 3 "Failure_Rear_Sensors" 2 "Speaker_Fault" 1 "ECU_Fault" 0 "No_Fault" ;
VAL_TABLE_ OffOnNoDataFault 3 "Fault" 2 "No_Data_Exists" 1 "On" 0 "Off" ;
VAL_TABLE_ ApaActvSd_D_Actl 3 "Dirver_Side" 2 "Passenger_Side" 1 "No_Side" 0 "Null" ;
VAL_TABLE_ ApaMdeStat_D_RqDrv 7 "Faulty" 6 "Off" 5 "NotUsed2" 4 "NotUsed1" 3 "POA" 2 "PPA" 1 "SAPP" 0 "Inactive" ;
VAL_TABLE_ ApaMde_D_Avail 15 "NotUsed7" 14 "NotUsed6" 13 "NotUsed5" 12 "NotUsed4" 11 "NotUsed3" 10 "NotUsed2" 9 "NotUsed1" 8 "PPA_POA" 7 "SAPP_POA" 6 "POA" 5 "PPA" 4 "SAPP" 3 "SAPP_PPA_POA" 2 "SAPP_PPA" 1 "None" 0 "Null" ;
VAL_TABLE_ ApaMde_D_Stat 7 "NotUsed" 6 "RePA" 5 "ParkIn" 4 "POA" 3 "PPA" 2 "SAPP" 1 "Off" 0 "Null" ;
VAL_TABLE_ FrostWarn_D_Stat 3 "NotUsed" 2 "On_Amber" 1 "On_Red" 0 "Off" ;
VAL_TABLE_ SteWhlLckMsgTxt_D_Rq 3 "Message_3" 2 "Message_2" 1 "Message_1" 0 "No_Message" ;
VAL_TABLE_ Null_Off_LowHigh 3 "High" 2 "Low" 1 "Off" 0 "Null" ;
VAL_TABLE_ GearRvrse_D_Actl 7 "Fault" 6 "NotUsed_3" 5 "NotUsed_2" 4 "NotUsed_1" 3 "Active_confirmed" 2 "Active_not_confirmed" 1 "Inactive_confirmed" 0 "Inactive_not_confirmed" ;
VAL_TABLE_ SideDetect_SnStat_Invalid 3 "Invalid" 2 "System_Failure" 1 "Blocked" 0 "Clear" ;
VAL_TABLE_ SideDetect_OpStat 7 "NotUsed_3" 6 "NotUsed_2" 5 "NotUsed_1" 4 "Invalid" 3 "Disabled" 2 "On" 1 "Trailer_Tow_Off" 0 "Off" ;
VAL_TABLE_ SideDetect_Present 4 "Sensor_Blocked" 3 "Sensor_Fault" 2 "Flash_On" 1 "Alert_On" 0 "AlertOff_FlashOff_SensrClr" ;
VAL_TABLE_ Off_On_Flash_BulbProveout 3 "Bulb_Proveout" 2 "Flash" 1 "On" 0 "Off" ;
VAL_TABLE_ SideDetect_BLIS_Off_On 3 "No_Selection_Made" 2 "BLIS_On_Second_Warning_ON" 1 "BLIS_On_Second_Warning_OFF" 0 "Off" ;
VAL_TABLE_ SideDetect_report 3 "Reporting" 2 "Not_Reporting" 1 "System_Standby" 0 "Initialization" ;
VAL_TABLE_ DrTGate_D_Rq 3 "NotUsed" 2 "Closing" 1 "Opening" 0 "Not_Moving" ;
VAL_TABLE_ WndwSide_D_Stat 3 "BothWindow_Operating" 2 "RearWindow_Operating" 1 "FrontWindow_Operating" 0 "NoWindows_Operating" ;
VAL_TABLE_ DcacElPw_D_Rq 3 "NotUsed" 2 "AC_HighPower_Requested" 1 "AC_LowPower_Requested" 0 "AC_Power_NotRequested" ;
VAL_TABLE_ False_True 1 "True" 0 "False" ;
VAL_TABLE_ Null_Up_Down 3 "Unused" 2 "Down" 1 "Up" 0 "Null" ;
VAL_TABLE_ Null_Fwd_Rwd 3 "Unused" 2 "Rearward" 1 "Forward" 0 "Null" ;
VAL_TABLE_ Null_Reset 1 "Reset" 0 "Null" ;
VAL_TABLE_ Unknown_FFFD_Invalid_NotSup 65535 "Not_Supported" 65534 "Invalid" 65533 "Unknown" ;
VAL_TABLE_ HvacBlwrFront_D_Stat 31 "Not_Used" 20 "Full_On" 19 "95_Percent" 18 "90_Percent" 17 "85_Percent" 16 "80_Percent" 15 "75_Percent" 14 "70_Percent" 13 "65_Percent" 12 "60_Percent" 11 "55_Percent" 10 "50_Percent" 9 "45_Percent" 8 "40_Percent" 7 "35_Percent" 6 "30_Percent" 5 "25_Percent" 4 "20_Percent" 3 "15_Percent" 2 "10_Percent" 1 "5_Percent" 0 "Off" ;
VAL_TABLE_ immoMsgTxt_D_Rq 15 "Immo_Msg_15" 14 "Immo_Msg_14" 13 "Immo_Msg_13" 12 "Immo_Msg_12" 11 "Immo_Msg_11" 10 "Immo_Msg_10" 9 "Immo_Msg_9" 8 "Immo_Msg_8" 7 "Immo_Msg_7" 6 "Immo_Msg_6" 5 "Immo_Msg_5" 4 "Immo_Msg_4" 3 "Immo_Msg_3" 2 "Immo_Msg_2" 1 "Immo_Msg_1" 0 "Immo_Msg_0_Null" ;
VAL_TABLE_ NoData_Faulty_7E_7F 127 "Faulty" 126 "NoDataExists" ;
VAL_TABLE_ HMI_HMIMode_St 7 "NotUsed2" 6 "NotUsed1" 5 "Load_Shed_Active" 0 "Invalid" 1 "OffMode" 2 "On" 3 "Phone" 4 "Climate" ;
VAL_TABLE_ FuelPumpPwr_D_Stat 7 "NotUsed3" 6 "NotUsed2" 5 "NotUsed1" 4 "Power_Off_Default" 3 "Power_Off_Command" 2 "Power_Off_Service" 1 "Power_Off_Impact" 0 "Power_On" ;
VAL_TABLE_ PrmtrAlrmEvnt_D_Stat 15 "Diag_Tamper" 14 "Trailer" 13 "Shock_Sensor" 12 "Post_Crash" 11 "Panic" 10 "Intrusion" 9 "Inclination" 8 "Ign_Tamper" 7 "LG_Door" 6 "Decklid" 5 "Hood" 4 "PR_Door" 3 "PF_Door" 2 "DR_Door" 1 "DF_Door" 0 "Null" ;
VAL_TABLE_ SecurityMsgTxt_D_Rq 3 "Message3" 2 "Message2" 1 "Message1" 0 "NoMessage" ;
VAL_TABLE_ PtcHtr_D_Cmd 3 "TurnOn" 2 "AutoMode" 1 "TurnOff" 0 "NoDecision_Initializing" ;
VAL_TABLE_ Fault_FFFFFF 16777215 "Fault" ;
VAL_TABLE_ NoData_Fault_FFFE_FFFF 65535 "Fault" 65534 "NoDataExists" ;
VAL_TABLE_ Fault_1FFF 8191 "Fault" ;
VAL_TABLE_ TrlrBattChrg_D_Stat 3 "Reverse" 2 "Normal" 1 "Low" 0 "Null" ;
VAL_TABLE_ TrlrLampCtl_D_Stat 3 "NotUsed" 2 "TrlrLampCnnctDrvFailure" 1 "TrlrLampNotCnnctDrvFailure" 0 "Null" ;
VAL_TABLE_ ElPw_D_StatStrtStop 15 "NotUsed6" 14 "NotUsed5" 13 "NotUsed4" 12 "NotUsed3" 11 "NotUsed2" 10 "NotUsed1" 9 "Supported_Level_4" 8 "Supported_Level_3" 7 "Supported_Level_2" 6 "Supported_Level_1" 5 "Limited_Support" 4 "Fault_Limited" 3 "LV_Event_in_Progress" 2 "Not_Supported_Imminent" 1 "Supported_All" 0 "Not_Supported" ;
VAL_TABLE_ ImpactEvntFdbck_D_Stat 3 "NotUsed" 2 "EventComplete" 1 "EventInProgress" 0 "Normal" ;
VAL_TABLE_ StopStrtIODTxt_D_Rq 31 "Message31" 30 "Message30" 29 "Message29" 28 "Message28" 27 "Message27" 26 "Message26" 25 "Message25" 24 "Message24" 23 "Message23" 22 "Message22" 21 "Message21" 20 "Message20" 19 "Message19" 18 "Message18" 17 "Message17" 16 "Message16" 15 "Message15" 14 "Message14" 13 "Message13" 12 "Message12" 11 "Message11" 10 "Message10" 9 "Message9" 8 "Message8" 7 "Message7" 6 "Message6" 5 "Message5" 4 "Message4" 3 "Message3" 2 "Message2" 1 "Message1" 0 "NoMessage" ;
VAL_TABLE_ NoData_Fault_7FFE_7FFF 32767 "Fault" 32766 "NoDataExists" ;
VAL_TABLE_ NoData_Fault_3E_3F 63 "Fault" 62 "NoDataExists" ;
VAL_TABLE_ DrvSte_D_Stat 15 "NotUsed10" 14 "NotUsed9" 13 "NotUsed8" 12 "NotUsed7" 11 "NotUsed6" 10 "NotUsed5" 9 "NotUsed4" 8 "NotUsed3" 7 "NotUsed2" 6 "NotUsed1" 5 "Request_Active" 4 "Ignition_Off" 3 "DSR_in_Normal_Idle_Mode" 2 "EPAS_Comm_Disturbed" 1 "DSR_Request_Not_Applicable" 0 "DSR_Deactivated" ;
VAL_TABLE_ StrtrMtrCtlMsgTxt_D_Rq 7 "Start_In_Gear_Allowed" 6 "Pending_Start_Cancelled" 5 "Start_Pending_Please_Wait" 4 "Cranking_Limit_Exceeded" 3 "Press_Brk_and_Shift_to_P_N" 2 "Press_Clutch_and_Brake" 1 "Press_Clutch_To_Start" 0 "No_Display" ;
VAL_TABLE_ Null_Open 1 "Open" 0 "Null" ;
VAL_TABLE_ Invalid_OffOn 0 "Invalid" 1 "Off" 2 "On" ;
VAL_TABLE_ TempDegreesC_DegreesF 0 "Temperature_deg_c" 1 "Temperature_deg_f" ;
VAL_TABLE_ BeltminderAudioMute 2 "On" 1 "Off" 0 "Invalid" ;
VAL_TABLE_ Chime_Source 2 "Cluster" 1 "Infotainment_Sys" 0 "Invalid" ;
VAL_TABLE_ Invalid_DayNight 2 "Night" 1 "Day" 0 "Invalid" ;
VAL_TABLE_ Invalid_12h_24h 2 "24h_mode" 1 "12h_mode" 0 "Invalid" ;
VAL_TABLE_ Invalid_Theme1_2 2 "Theme_2" 1 "Theme_1" 0 "Invalid" ;
VAL_TABLE_ LanguageSelect_St 33 "Ukrainian" 32 "Indian_English" 31 "Thai" 30 "Slovak" 29 "Arabic" 28 "Taiwanese" 27 "Mandarin_Chinese" 26 "Korean" 25 "AU_English" 24 "Japanese" 23 "Braz_Portuguese" 22 "EU_Portuguese" 21 "Finish" 20 "Norwegian" 19 "Danish" 18 "Swedish" 17 "Hungarian" 16 "Greek" 15 "Czech" 14 "Polish" 13 "Flemish" 12 "Dutch" 11 "Russian" 10 "Turkish" 9 "Mex_Spanish" 8 "EU_Spanish" 7 "Cana_French" 6 "EU_French" 5 "Italian" 4 "German" 3 "NA_English" 2 "UK_English" 1 "Unknown" 0 "Invalid" ;
VAL_TABLE_ HeadLghtHiFdbck_D_Stat 3 "NotUsed" 2 "Cancel" 1 "Hold" 0 "Allow_Change" ;
VAL_TABLE_ Backlit_LED_Status 15 "Unused3" 14 "Unused2" 13 "Unused1" 12 "Night_12" 11 "Night_11" 10 "Night_10" 9 "Night_9" 8 "Night_8" 7 "Night_7" 6 "Night_6" 5 "Night_5" 4 "Night_4" 3 "Night_3" 2 "Night_2" 1 "Night_1" 0 "Off" ;
VAL_TABLE_ Veh_Lock_Status 3 "UNLOCK_DRV" 2 "UNLOCK_ALL" 1 "LOCK_ALL" 0 "LOCK_DBL" ;
VAL_TABLE_ PrkLckCtlMsgTxt_D_Rq 3 "BTSI_DI_3" 2 "BTSI_DI_2" 1 "BTSI_DI_1" 0 "Null_BTSI_DI" ;
VAL_TABLE_ NoShift_Shift 1 "Shift" 0 "NoShift" ;
VAL_TABLE_ CcdMsgTxt_D_RqDsply 15 "Unused8" 14 "Unused7" 13 "Unused6" 12 "Unused5" 11 "Unused4" 10 "Unused3" 9 "Unused2" 8 "StationaryMode" 7 "Mode_Change_Unavailable" 6 "CCD_Temporarily_Off" 5 "CCD_Service_Required" 4 "Faulty" 3 "Sport" 2 "Normal" 1 "Comfort" 0 "No_Mode_Selected" ;
VAL_TABLE_ CrashEvnt_D_Stat 3 "Invalid" 2 "Fuel_Cutoff_Event" 1 "Deploy_Event" 0 "No_Event" ;
VAL_TABLE_ ReducedGuard_D_Stat 3 "NotUsed" 2 "Alarm_On" 1 "Alarm_Off_Previously_On" 0 "Alarm_Off" ;
VAL_TABLE_ HvacPrecondBlwr_D_Rq 15 "NotUsed6" 14 "NotUsed5" 13 "NotUsed4" 12 "NotUsed3" 11 "NotUsed2" 10 "NotUsed1" 9 "Last_User_Setting" 8 "Auto" 7 "Speed7" 6 "Speed6" 5 "Speed5" 4 "Speed4" 3 "Speed3" 2 "Speed2" 1 "Speed1" 0 "Off" ;
VAL_TABLE_ HvacPrecondMode_D_Rq 15 "NotUsed4" 14 "NotUsed3" 13 "NotUsed2" 12 "Low_Blower_Auto" 11 "Last_User_Settings" 10 "Auto" 9 "Max_Defrost" 8 "Windshield_Panel_Floor" 7 "Windshield_Panel" 6 "Windshield" 5 "Windshield_Floor" 4 "Floor" 3 "Panel_Floor" 2 "Panel" 1 "MAX_AC" 0 "Off" ;
VAL_TABLE_ ButtonNotPressed 1 "Button_Pressed" 0 "Button_Not_Pressed" ;
VAL_TABLE_ Null_Pressed 1 "Pressed" 0 "Null" ;
VAL_TABLE_ FobComm_D_Stat 3 "NotUsed" 2 "RemEngStartOK" 1 "RemEngStartFail" 0 "Null" ;
VAL_TABLE_ PudLamp_D_Rq 3 "RAMP_DOWN" 2 "RAMP_UP" 1 "ON" 0 "OFF" ;
VAL_TABLE_ WndwGlbl_D_Cmd 7 "NotUsed3" 6 "NotUsed2" 5 "NotUsed1" 4 "GLEARN" 3 "GCLOSE" 2 "GOPEN" 1 "GSTOP" 0 "Null" ;
VAL_TABLE_ LockMsg 7 "MSG7" 6 "MSG6" 5 "MSG5" 4 "MSG4" 3 "MSG3" 2 "MSG2" 1 "MSG1" 0 "NO_WARNING" ;
VAL_TABLE_ ChildLockDisplay 3 "NOT_SUPPORTED" 2 "ERROR" 1 "CHILD_UNLOCK" 0 "CHILD_LOCK" ;
VAL_TABLE_ Null_Lock_Unlock 3 "NotUsed" 2 "Unlock" 1 "Lock" 0 "Null" ;
VAL_TABLE_ Wiper 15 "NO_DATA_EXISTS" 14 "STALLED" 13 "RESERVED" 12 "AUTO_ADJUST" 11 "COURTESYWIPE" 10 "AUTO_HIGH" 9 "AUTO_LOW" 8 "WASH" 7 "MIST_FLICK" 6 "MAN_HIGH" 5 "MAN_LOW" 4 "MAN_INT_ON" 3 "MAN_INT_OFF" 2 "OFF_MOVING" 1 "AUTO_OFF" 0 "OFF" ;
VAL_TABLE_ Turn_switch 3 "Unused_Treat_As_Off" 2 "Right" 1 "Left" 0 "Off" ;
VAL_TABLE_ PrkLght_D_Stat 3 "Park_Both" 2 "Park_Right" 1 "Park_Left" 0 "Off" ;
VAL_TABLE_ LghtAmb_D_Sns 7 "No_Data_Exists" 6 "Unused2" 5 "Unused1" 4 "Tunnel_Off" 3 "Tunnel_On" 2 "Twilight" 1 "Light" 0 "Dark" ;
VAL_TABLE_ HeadLghtSwtch_D_Stat 3 "Autolamp" 2 "Headlamp" 1 "Parklamp" 0 "Off" ;
VAL_TABLE_ EmgcyBrkLamp_D_Rq 3 "NotUsed" 2 "Active_at_standstill" 1 "Active_at_speed" 0 "Inactive" ;
VAL_TABLE_ EDrvTqMntrRconfg_D_Cmd 7 "OK" 6 "Disable_Cruise" 5 "NotUsed4" 4 "Supercreep" 3 "NotUsed3" 2 "NotUsed2" 1 "Engine_shutdown" 0 "NotUsed" ;
VAL_TABLE_ OpenPressedFault 3 "Fault" 2 "Unused" 1 "Pressed" 0 "Open" ;
VAL_TABLE_ LaHandsOff_D_Dsply 3 "Suppressed" 2 "Level2" 1 "Level1" 0 "HandsOn" ;
VAL_TABLE_ Avail_Unavail 1 "Unavailable" 0 "Available" ;
VAL_TABLE_ LaActvStats_D_Dsply 31 "Unused7" 30 "LA_Off" 29 "Unused5" 28 "Unused4" 27 "Unused3" 26 "Unused2" 25 "Unused1" 24 "InerveneLeft_InterveneRght" 23 "WarnLeft_InterveneRight" 22 "SuppressLeft_InterveneRght" 21 "AvailLeft_InterveneRhtt" 20 "NoLeft_InterveneRight" 19 "InterveneLeft_WarnRight" 18 "WarnLeft_WarnRight" 17 "SuppressLeft_WarnRight" 16 "AvailableLeft_WarnRight" 15 "NoLeft_WarnRight" 14 "InterveneLeft_SuppressRght" 13 "WarnLeft_SuppressRight" 12 "SuppressLeft_SuppressRight" 11 "AvailLeft_SuppressRight" 10 "NoLeft_SuppressRight" 9 "InterveneLeft_AvailRight" 8 "WarnLeft_AvailRight" 7 "SuppressLeft_AvailRight" 6 "AvailableLeft_AvailRight" 5 "NoLeft_AvailableRight" 4 "InterveneLeft_NoRight" 3 "WarnLeft_NoRight" 2 "SuppressLeft_NoRight" 1 "AvailableLeft_NoRight" 0 "NoLeft_NoRight" ;
VAL_TABLE_ AhbcHiBeam_D_Rq 3 "Deactivated_Unavailabl" 2 "Unused" 1 "Main_HighBeamRecommend" 0 "Dipped_LowBeamRecommend" ;
VAL_TABLE_ LifeCycMde_D_Actl 3 "Transport" 2 "NotUsed" 1 "Factory" 0 "Normal" ;
VAL_TABLE_ TrnMsgTxt_D_Rq 15 "Message_15" 14 "Message_14" 13 "Message_13" 12 "Message_12" 11 "Message_11" 10 "Message_10" 9 "Message_9" 8 "Message_8" 7 "Message_7" 6 "Message_6" 5 "Message_5" 4 "Message_4" 3 "Message_3" 2 "Message_2" 1 "Message_1" 0 "NoMessage" ;
VAL_TABLE_ TrnNtrlTowCmd_D_Actl 3 "NotUsed" 2 "Neutral_Tow_Entry" 1 "Car_Wash_Mode" 0 "Normal_Mode" ;
VAL_TABLE_ TrnValidGear_D_Cnfm 3 "Accept" 2 "Reject" 1 "Internal_Request" 0 "No_Command" ;
VAL_TABLE_ TrnGear_D_RqPt 7 "Fault" 6 "NotUsed" 5 "Manual" 4 "Drive" 3 "Neutral" 2 "Reverse" 1 "Park" 0 "No_Gear" ;
VAL_TABLE_ TrnValidGearRq_D_Stat 3 "Valid_Request" 2 "Valid_Degraded_Request" 1 "Invalid_Request" 0 "No_Request" ;
VAL_TABLE_ NoData_Fault_3FE_3FF 1023 "Fault" 1022 "NoDataExists" ;
VAL_TABLE_ Fault_FFF 4095 "Fault" ;
VAL_TABLE_ VehStrtStop_D_Rq 3 "NotUsed" 2 "Vehicle_Start_Request" 1 "Vehicle_Stop_Request" 0 "NoRequest" ;
VAL_TABLE_ FuelCtlOpenLp_B_Inhbt 1 " Inhibit_FullPedal_Actions" 0 "Normal_Operation" ;
VAL_TABLE_ PrkBrkStatus 7 "GeneralFault_MaintenceMode" 6 "ECD_by_Brake_ECU_Active" 5 "EPB_Limphome_Active" 4 "Rear_Caliper_Open" 3 "RWU_By_EPB_Active" 2 "Rear_Caliper_Transition" 1 "Rear_Caliper_Closed" 0 "Not_Supported" ;
VAL_TABLE_ ElLoadCtl_D_Rq 7 "Unused3" 6 "Unused2" 5 "Unused1" 4 "HoldAllDrvrInvisibleLoads" 3 "StdDriverInvisibleLoadsOn" 2 "AllDriverInvisibleLoadsOn" 1 "All_Possible_Loads_Off" 0 "No_Request" ;
VAL_TABLE_ DontCare_StartInhibit 1 "Start_Inhibit" 0 "Dont_Care" ;
VAL_TABLE_ BattULoChrg_D_Rq 3 "Low_Battery_Temperature" 2 "Charging_Requested" 1 "Chrg_Requested_HighCurrent" 0 "No_Request" ;
VAL_TABLE_ PwSysULoFalt_D_Stat 15 "Not_Used_6" 14 "LowBatterySOC" 13 "PSS_Shed2_Contin" 12 "Not_Used_4" 11 "Not_Used_3" 10 "Not_Used_2" 9 "BattMonitoringSensorFault" 8 "LowBattVoltDuringPwSrcOn" 7 "LowBatt2_PowerSaveMode" 6 "LowBatt1_Warning" 5 "Overvoltage" 4 "Fault_NoOutput" 3 "Fault_ReducedOutput" 2 "Fault_Nonspecific" 1 "Cluster_Proveout" 0 "No_Fault" ;
VAL_TABLE_ AccStopMde_D_Rq 3 "Stop_Mode_Active" 2 "EPBApplyOrBrakeReleaseWarn" 1 "Limit_Rolling_Speed" 0 "Stop_Mode_Not_Active" ;
VAL_TABLE_ Eng_D_Stat 3 "NotUsed" 2 "EngAutoStopped" 1 "EngOn" 0 "EngOff" ;
VAL_TABLE_ ElPw_D_Stat 7 "NotUsed_3" 6 "NotUsed_2" 5 "NotUsed_1" 4 "Fault_Limited" 3 "LV_Event_In_Progress" 2 "Not_Supported_Imminent" 1 "Supported" 0 "Not_Supported" ;
VAL_TABLE_ PwPckTq_D_Stat 3 "PwPckOn_TqAvailable" 2 "StartInPrgrss_TqNotAvail" 1 "PwPckOn_TqNotAvailable" 0 "PwPckOff_TqNotAvailable" ;
VAL_TABLE_ Fault_FF 255 "Fault" ;
VAL_TABLE_ Southern_Northern 3 "Fault" 2 "Northern" 1 "Southern" 0 "Invalid" ;
VAL_TABLE_ PsngrFrntDetct_D_Actl 3 "Unknown" 2 "Empty" 0 "Faulty" 1 "Occupied" ;
VAL_TABLE_ Normal_Mode1_2 3 "Undefined" 2 "Mode2" 1 "Mode1" 0 "Normal_Mode" ;
VAL_TABLE_ LaActvAvail 3 "LKA_LCA_LDW_Avail" 2 "LCA_LKA_Avail_LDW_Suppress" 1 "LCA_LKA_Suppress_LDW_Avail" 0 "LCA_LKA_LDW_Suppress" ;
VAL_TABLE_ LA_NotDenied 1 "LA_Denied" 0 "LA_Not_Denied" ;
VAL_TABLE_ HandsOn_Off 1 "Hands_Off" 0 "Hands_On" ;
VAL_TABLE_ Smooth_Quick 1 "Quick" 0 "Smooth" ;
VAL_TABLE_ None_Low_Med_High 3 "High" 2 "Medium" 1 "Low" 0 "None" ;
VAL_TABLE_ LdwActvStats 7 "LDW_Suppress_Right_Left" 6 "Not_Used2" 5 "LDW_Suppress_Right" 4 "LDW_Warning_Right" 3 "LDW_Suppress_Left" 2 "LDW_Warning_Left" 1 "LDW_DemoVibration" 0 "LDW_Idle" ;
VAL_TABLE_ Fault_3FF 1023 "Fault" ;
VAL_TABLE_ Fault_F 15 "Fault" ;
VAL_TABLE_ Fault_1F 31 "Fault" ;
VAL_TABLE_ LockInhibit 1 "Inhibit" 0 "No_Inhibit" ;
VAL_TABLE_ DieslFuelBio_B_ActlDrv 1 "Biodiesel_User" 0 "Non_Biodiesel_User" ;
VAL_TABLE_ Invalid_FFF 4095 "Invalid" ;
VAL_TABLE_ ParkAid_Chime 15 "Zone15_Chime" 14 "Zone14_Chime" 13 "Zone13_Chime" 12 "Zone12_Chime" 11 "Zone11_Chime" 10 "Zone10_Chime" 9 "Zone9_Chime" 8 "Zone8_Chime" 7 "Zone7_Chime" 6 "Zone6_Chime" 5 "Zone5_Chime" 4 "Zone4_Chime" 3 "Zone3_Chime" 2 "Zone2_Chime" 1 "Zone1_Chime" 0 "No_Chime" ;
VAL_TABLE_ Shed_Feature_Group_ID 16 "PtcHeater" 30 "NotUsed_7" 29 "NotUsed_6" 28 "NotUsed_5" 27 "NotUsed_4" 26 "NotUsed_3" 25 "NotUsed_2" 24 "NotUsed_1" 23 "Dcac" 22 "UpFitter_6" 21 "UpFitter_5" 20 "UpFitter_4" 19 "UpFitter_3" 18 "UpFitter_2" 17 "UpFitter_1" 14 "HtdMirr" 13 "HvacRearBlwr_Third" 12 "HvacRearBlwr_Second" 11 "HvacRearBlwr_First" 31 "All LSHED1 Features" 10 "Htd_Windscrn" 9 "SpltHtdBcklight_HtdMirr" 8 "HtdBcklight_HtdMirr" 7 "HtdCoolSeat_FrtDriver" 6 "HtdCoolSeat_FrtPass" 5 "HtdCoolSeat_RearPass" 4 "HtdCoolSeat_RearDriver" 3 "SmartTrlrTowBattCharge" 2 "Htd_StrWhl" 1 "Htd_Washer_Fluid" 0 "No_LSHED1_Features" 15 "Engine_Coolant_Fan" ;
VAL_TABLE_ Null_Cancel 1 "Cancel" 0 "Null" ;
VAL_TABLE_ Null_Drive_EasyEntry 2 "Easy_Entry" 1 "Drive" 0 "Null" ;
VAL_TABLE_ Veh_Lock_Requestor 31 "Walk_Away_Locking" 30 "Remote_Park_Assist" 29 "DoorsOffToOn_Smart_Unlock" 28 "Rgtm_Shutlock_Switch" 27 "Boundary_Alert" 26 "Transit_Vehicle_Relock" 25 "Transit_Cargo_Relock" 24 "Transit_Ajar_Lock" 23 "Diagnostics" 22 "Console_Lock" 21 "Child_Lock" 20 "Double_Lock" 19 "Passive_Pasenger" 18 "Passive_Driver" 17 "Slam_Lock_Protect" 16 "SYNC" 15 "Passport" 14 "Passive_Smart_Unlock" 13 "Autorelock" 12 "RemoteStart" 0 "Null" 1 "Autolock" 11 "Smart_Unlock" 10 "Sliding_Door" 9 "Passive" 8 "Remote" 7 "Programming" 6 "Powerslide" 5 "Keypad" 4 "Key_Cylinder" 3 "Interior" 2 "Auto_Unlock" ;
VAL_TABLE_ EPAS_FAILURE 3 "SERVICE_POWER_STEERING_NOW" 2 "SERVICE_POWER_STEERING" 1 "POWER_STRG_ASSIST_FAULT" 0 "EPAS_OK_NO_MESSAGE" ;
VAL_TABLE_ Perimeter_Alarm_Mode 3 "Activated" 2 "Armed" 1 "Prearmed" 0 "Disarmed" ;
VAL_TABLE_ Invalid_FFFF 65535 "Invalid" ;
VAL_TABLE_ MyKey_KeyTypeChangeReq 3 "Search_PE_BackupSlot" 2 "Clear_All_MyKeys" 1 "Request_New_MyKey" 0 "None" ;
VAL_TABLE_ MyKey_Key_Count 13 "Thirteen" 12 "Twelve" 11 "Eleven" 10 "Ten" 9 "Nine" 8 "Eight" 7 "Seven" 6 "Six" 5 "Five" 4 "Four" 3 "Three" 2 "Two" 1 "One" 0 "Zero" 15 "Invalid" 14 "Unlimited" ;
VAL_TABLE_ GearEngag_D_Actl 7 "Undefined" 6 "Fwd_Clutch_Fully_Engaged" 5 "Neutral_Idle" 4 "Disengaged_to_Neutral_Idle" 3 "Disengaged_to_Neutral_Park" 2 "Engagement_in_Progress" 1 "InitializeFwdClutchEngagmt" 0 "Park_Neutral" ;
VAL_TABLE_ Shed_Level_Req 7 "SHED3" 6 "Loads_On" 5 "SHED_ENG_OFF" 4 "SOON_ENG_OFF" 3 "SHED2_CONTIN" 2 "SHED2_TRANS" 1 "SHED1" 0 "NO_SHED" ;
VAL_TABLE_ BpedMove_D_Actl 3 "Unknown" 2 "DriverApplyingBrakePedal" 1 "NoAutonomousBrkPdlMovement" 0 "AutonomousBrkPedalMove" ;
VAL_TABLE_ Eastern_Western 0 "Invalid" 1 "Eastern" 2 "Western" 3 "Fault" ;
VAL_TABLE_ ChargeMode 7 "Undefined_2" 6 "Undefined_1" 5 "Battery_Identify" 4 "Battery_Refresh" 3 "SlowRegenAllowNoDischarge" 2 "Fast_Regen_Allowed" 1 "Slow_Regen_Allowed" 0 "Conventional_Charging" ;
VAL_TABLE_ Unknown_FFFE_Invalid_FFFF 65535 "Invalid" 65534 "Unknown" ;
VAL_TABLE_ SAPPAngleControlStat5 1 "StrgColTorqueExceed_EAROn" 0 "ExternalSigContentOKforEAC" ;
VAL_TABLE_ Closed_Open_Active_Fault 3 "Fault" 2 "Active" 1 "Open" 0 "Closed" ;
VAL_TABLE_ SAPPAngleControlStat2 1 "Rel_ExtSteeringAngleReqx" 0 "NoRel_ExtSteeringAngleReqx" ;
VAL_TABLE_ SAPPAngleControlStat3 1 "EARactiveNoReverseEngage" 0 "ExternalSigContentOKforEAC" ;
VAL_TABLE_ RstrnImpactEvntStatus 7 "Invalid" 6 "Not_Used_4" 5 "Threshold_2_Exceeded" 4 "Not_Used_3" 3 "Threshold_1_Exceeded" 2 "Not_Used_2" 1 "Not_Used_1" 0 "Normal" ;
VAL_TABLE_ EDRTriggerEvntSync 1 "Threshold_Exceeded" 0 "Normal" ;
VAL_TABLE_ HILL_DESC_MC 7 "Fault_Detected" 6 "Cooling_Down" 5 "Abort_Apply_Brakes" 4 "Active" 3 "Disabled" 2 "Enabled" 1 "Off_Road" 0 "Normal" ;
VAL_TABLE_ Closed_Ajar 1 "Ajar" 0 "Closed" ;
VAL_TABLE_ CADS_Autio_Mute 7 "Unknown" 6 "Attenuation_6" 5 "Attenuation_5" 4 "Attenuation_4" 3 "Attenuation_3" 2 "Attenuation_2" 1 "Attenuation_1" 0 "No_Attenuation_of_Audio" ;
VAL_TABLE_ Quality_Factor 3 "OK" 2 "Not_Within_Specifications" 1 "No_Data_Exists" 0 "Faulty" ;
VAL_TABLE_ Null_Day_Night 3 "NotUsed" 2 "Night" 1 "Day" 0 "Null" ;
VAL_TABLE_ Null_Flash_High 3 "NotUsed" 2 "High" 1 "Flash_to_Pass" 0 "Null" ;
VAL_TABLE_ GearPos_D_Actl 15 "Unknown" 14 "Reverse" 13 "Undefined_5" 12 "Undefined_4" 11 "Undefined_3" 10 "Tenth" 9 "Ninth" 8 "Eighth" 7 "Seventh" 6 "Sixth" 5 "Fifth" 4 "Fourth" 3 "Third" 2 "Second" 1 "First" 0 "Neutral" ;
VAL_TABLE_ OffOn_SlowFast_Flash 3 "Fast_Flash" 2 "Slow_Flash" 1 "On" 0 "Off" ;
VAL_TABLE_ AwdStat_D_RqDsply 31 "Rear_Diff_Lock_Not_Avail" 30 "_4wd_Lock_Required" 29 "Cfg_Perf_Redc_See_Manual" 28 "To_Engage_4x4_Release_Aped" 27 "To_Engage_4x4_Slow_To_3MPH" 26 "Shift_To_Neutral" 25 "Lkr_Mode_Unavail_TMS" 24 " _4x4_Mode_Unavail_TMS" 23 "Out_of_4Low_Crawl" 22 "AWD_PTU_Oil_Changed" 21 "Change_AWD_PTU_Oil" 20 "Neutral_Tow_Disabled" 19 "Neutral_Tow_Enabled" 18 "AWD_OFF" 17 "_4x4_Off_Road_Speed" 16 "_4x4_Extreme_Off_Road_Mode" 15 "_4x4_Exiting_Off_Road" 14 "_4x4_Off_Road_Mode" 10 "_4x4_Locked_Temporarily" 9 "Shift_In_Progress" 13 "Blocked_Shift_Assist" 12 "_4x4_Auto_Restored" 11 "_4x4_Disabled_Temporarily" 7 "Out_of_4Low__Neutral" 6 "Out_of_4Low__Brake" 5 "Out_of_4Low__Speed" 4 "Into_4Low__Clutch" 3 "Into_4Low__Neutral" 2 "Into_4Low__Brake" 1 "Into_4Low__Speed" 0 "Normal__No_Message" 8 "Out_of_4Low__Clutch" ;
VAL_TABLE_ AngleReached 1 "RequestedAngleNotReached" 0 "RequestedAngleCanBeReached" ;
VAL_TABLE_ WhlDir 3 "Faulty" 2 "NoDataExists" 1 "Backward" 0 "Forward" ;
VAL_TABLE_ Unknown_Fault_1FE_1FF 511 "Fault" 510 "Unknown" ;
VAL_TABLE_ Fault_NoFault 1 "Fault" 0 "No_Fault" ;
VAL_TABLE_ TrnIpcDsplyMde_D_Actl 7 "Manual_3" 6 "Manual_2" 5 "Manual_1_Low" 4 "Sport" 3 "Drive" 2 "Neutral" 1 "Reverse" 0 "Park" ;
VAL_TABLE_ TrnIpcDsplyMde_D_Stat 3 "Reserved_Blank_No_Display" 2 "Flash" 1 "On" 0 "Blank_No_Display" ;
VAL_TABLE_ TrnIpcDsplyGear_D_Actl 15 "No_Gear_Selected" 14 "_14th_Gear" 13 "_13th_Gear" 12 "_12th_Gear" 11 "_11th_Gear" 10 "_10th_Gear" 9 "_9th_Gear" 8 "_8th_Gear" 7 "_7th_Gear" 6 "_6th_Gear" 5 "_5th_Gear" 4 "_4th_Gear" 3 "_3rd_Gear" 2 "_2nd_Gear" 1 "_1st_Gear" 0 "Neutral" ;
VAL_TABLE_ TerrMde_D_Actl 7 "Fail_Safe_Default" 6 "Dynamic_Mode" 5 "Rock_Crawl_Mode" 4 "Mud_Ruts_Mode" 3 "Sand_Mode" 2 "Undefined" 1 "Low_Mu_Mode" 0 "Special_Operating_Mode_Off" ;
VAL_TABLE_ TerrMdeChng_D_Rdy 7 "Fault" 6 "Undefined_2" 5 "Undefined_1" 4 "ModeUnavailDrInputRqd" 3 "SpOpModes_NotSupported" 2 "ModeUnavailDynamicCond" 1 "Module_In_Initialization" 0 "Mode_Change_Available" ;
VAL_TABLE_ Unknown_Fault_FFFE_FFFF 65535 "Fault" 65534 "Unknown" ;
VAL_TABLE_ Invalid_FFFFFF 16777215 "Invalid" ;
VAL_TABLE_ AutoParkSpdExitCond 1 "SpeedLimitExceededEAROn" 0 "ExternalSigContentOKforEAC" ;
VAL_TABLE_ EngOilLvlDsply_D_Rq 15 "EngOil_LevelSys_CheckFault" 14 "Reserved_2" 13 "Reserved_1" 12 "Conditions_Unsuitable" 11 "Dipstick_Below_Minimum" 10 "Dipstick_Above_Maximum" 9 "Dipstick_Minimum" 8 "Dipstick_12_5_MinMaxRange" 7 "Dipstick_25_MinMaxRange" 6 "Dipstick_37_5_MinMaxRange" 5 "Dipstick_50_MinMaxRange" 4 "Dipstick_62_5_MinMaxRange" 3 "Dipstick_75_MinMaxRange" 2 "Dipstick_87_5_MinMaxRange" 1 "Dipstick_Maximum_Displayed" 0 "No_Message" ;
VAL_TABLE_ HdcMde_D_Actl 7 "Fault" 6 "Temporarily_Unavailable" 5 "NotEnabled_WrongGearSel" 4 "NotEnabled_SpdLimitExceed" 3 "Active_Braking" 2 "Not_Active_Braking" 1 "Off" 0 "Undefined" ;
VAL_TABLE_ GearLvrPos_D_Actl 15 "Fault" 14 "Unknown_Position" 13 "Undefined_Treat_as__Fault" 12 "Undefined_Treat_as_Fault" 11 "sixth" 10 "fifth" 9 "fourth" 8 "third" 7 "second" 6 "first" 5 "Low" 4 "Sport_DriveSport" 3 "Drive" 2 "Neutral" 1 "Reverse" 0 "Park" ;
VAL_TABLE_ FcwMsgTxt_D_Rq 7 "Undefined_3" 6 "Undefined_2" 5 "Low_Visibility" 4 "Unavailable_DueTo_LowSpeed" 3 "Available" 2 "Unavailable" 1 "Off" 0 "No_Text" ;
VAL_TABLE_ FcwSens_B_Actl 3 "FCW_Sensitivity_3" 2 "FCW_Sensitivity_2" 1 "FCW_Sensitivity_1" 0 "Not_Used" ;
VAL_TABLE_ DrvHdcMsg_D_Rq 7 "Undefined" 6 "Speed_too_High" 5 "Temporarily_Unavailable" 4 "System_Fault" 3 "Select_Gear" 2 "Off" 1 "On" 0 "No_Message" ;
VAL_TABLE_ CmbbBrkPrchg_B_Rq 3 "Undefined" 2 "Level_2_PreCharge_Request" 1 "Level_1_PreCharge_Request" 0 "No_PreCharge_Request" ;
VAL_TABLE_ CmbbBaSens_D_Rq 3 "Level_3" 2 "Level_2" 1 "Level_1" 0 "Normal" ;
VAL_TABLE_ CcStat_D_Actl 7 "Undefined_2" 6 "Undefined_1" 5 "Active" 4 "Active_Que_Assist" 3 "Standby" 2 "Standby_Denied" 1 "Denied" 0 "Off" ;
VAL_TABLE_ BpedDrvAppl_D_Actl 3 "_Not_Allowed" 2 "Driver_Braking" 1 "Driver_Not_Braking" 0 "Not_Allowed" ;
VAL_TABLE_ AslIconDsply_D_Rq 3 "On_Passive_Overridden" 2 "On_Active" 1 "On_Passive" 0 "Off" ;
VAL_TABLE_ Unknown_Fault_3E_3F 63 "Fault" 62 "Unknown" ;
VAL_TABLE_ AccWarn_D_Dsply 3 "BrakeReleaseWarn_In_StopMd" 2 "Brake_Capacity_Warning" 1 "Cancel_Warning" 0 "No_Warning" ;
VAL_TABLE_ AccTrgDist2_D_Dsply 15 "DIST_ACTIVE_13_Farthest" 14 "DIST_ACTIVE_12" 13 "DIST_ACTIVE_11" 12 "DIST_ACTIVE_10" 11 "DIST_ACTIVE_9" 10 "DIST_ACTIVE_8" 9 "DIST_ACTIVE_7" 8 "DIST_ACTIVE_6" 7 "DIST_ACTIVE_5" 6 "DIST_ACTIVE_4" 5 "DIST_ACTIVE_3" 4 "DIST_ACTIVE_2" 3 "DIST_ACTIVE_1_Closest" 2 "DIST_ACTIVE_No_Target" 1 "DIST_STANDBY" 0 "DIST_OFF" ;
VAL_TABLE_ AccTGap_D_Dsply 7 "Undefined_2" 6 "Undefined_1" 5 "Time_Gap_5" 4 "Time_Gap_4" 3 "Time_Gap_3" 2 "Time_Gap_2" 1 "Time_Gap_1" 0 "Not_Used" ;
VAL_TABLE_ AccEngStat_D_Actl 7 "Undefined_2" 6 "Undefined_1" 5 "ACCSoonCancel_due_Low_Spd" 4 "Shift_Down_Recommendation" 3 "Shift_Up_Recommendation" 2 "ACCNotAllowedToBeActivated" 1 "ACCStandby_due_Auto_Cancel" 0 "Normal_Operation" ;
VAL_TABLE_ NotPressed_Pressed 1 "Pressed" 0 "Not_Pressed" ;
VAL_TABLE_ TrnGear_D_RqDrv 31 "Fault" 30 "NotUsed_25" 29 "NotUsed_24" 28 "NotUsed_23" 27 "NotUsed_22" 26 "NotUsed_21" 25 "NotUsed_20" 24 "NotUsed_19" 23 "NotUsed_18" 22 "NotUsed_17" 21 "Return_To_Park" 20 "NotUsed_15" 19 "NotUsed_14" 18 "NotUsed_13" 17 "NotUsed_12" 16 "Manual" 15 "Not_Used11" 14 "Not_Used10" 13 "NotUsed_9" 12 "NotUsed_8" 11 "NotUsed_7" 10 "NotUsed_6" 9 "NotUsed_5" 8 "Drive" 7 "NotUsed_4" 6 "NotUsed_3" 5 "NotUsed_2" 4 "Neutral" 3 "NotUsed_1" 2 "Reverse" 1 "Park" 0 "No_Gear" ;
VAL_TABLE_ OpenCloseRetainUndef 3 "Undefined" 2 "Retain" 1 "Close" 0 "Open" ;
VAL_TABLE_ DasWarn 3 "Undefined" 2 "Warning_Level_2" 1 "Warning_Level_1" 0 "No_Warning" ;
VAL_TABLE_ DasAlert 5 "Alertness_Level_5" 4 "Alertness_Level_4" 3 "Alertness_Level_3" 2 "Alertness_Level_2" 1 "Alertness_Level_1" 0 "Undefined" ;
VAL_TABLE_ DasStat 3 "Available" 2 "Unavailable_Other" 1 "Feedback_due_to_Speed" 0 "Off" ;
VAL_TABLE_ No_Crank_Req 1 "Crank_Request" 0 "No_Crank_Request" ;
VAL_TABLE_ DrvSlipCtlMde_D_Rq 3 "App_Specific_Off_Mode_3" 2 "App_Specific_Off_Mode_2" 1 "App_Specific_Off_Mode_1" 0 "Default_Mode" ;
VAL_TABLE_ AwdOffRoadMode 3 "Invalid" 2 "Extreme_Off_Road" 1 "Off_Road" 0 "Normal_Mode" ;
VAL_TABLE_ NotQuiet_Quiet 1 "Quiet" 0 "Not_Quiet" ;
VAL_TABLE_ Normal_AdaptiveCruise 1 "Adaptive_Cruise" 0 "Normal_Cruise" ;
VAL_TABLE_ Remote_Device_Feedback 7 "Unused3" 6 "Unused2" 5 "Unused1" 4 "Shutdown" 3 "Running" 2 "Starting" 1 "Acknowledge" 0 "Null" ;
VAL_TABLE_ Unlock_Lock 1 "Locked" 0 "Unlock" ;
VAL_TABLE_ PE_BackupSlot_Status 3 "No_Valid_FOB_In_Slot" 2 "MyKey_FOB_In_Slot" 1 "Standard_FOB_In_Slot" 0 "Null" ;
VAL_TABLE_ Unknown_Fault_FFE_FFF 4095 "Fault" 4094 "Unknown" ;
VAL_TABLE_ Unknown_Fault_1FFE_1FFF 8191 "Fault" 8190 "Unknown" ;
VAL_TABLE_ TrnCnvtClu_D_Actl 3 "Transition_or_Micro_Slip" 2 "Lock_Up_Fixed" 1 "Lock_Up_Slip" 0 "No_Lock_Up" ;
VAL_TABLE_ InhibitNoinhibit 1 "Inhibit" 0 "No_Inibit" ;
VAL_TABLE_ DisableEnable 1 "Enable" 0 "Disable" ;
VAL_TABLE_ Unknown_Fault_7FFE_7FFF 32767 "Fault" 32766 "Unknown" ;
VAL_TABLE_ Side_Detect_Sn_State 3 "Second_Warning_Audio" 2 "System_Failure" 1 "Blocked" 0 "Clear" ;
VAL_TABLE_ Litval_values 255 "Invalid" 254 "Unknown" 5 "Day" 4 "Twilight_4" 3 "Twilight_3" 2 "Twilight_2" 1 "Twilight_1" 0 "Night" ;
VAL_TABLE_ Dimming_Lvl 255 "Invalid" 254 "Unknown" 18 "Day_6" 17 "Day_5" 16 "Day_4" 15 "Day_3" 14 "Day_2" 13 "Day_1" 12 "Night_12" 11 "Night_11" 10 "Night_10" 9 "Night_9" 8 "Night_8" 7 "Night_7" 6 "Night_6" 5 "Night_5" 4 "Night_4" 3 "Night_3" 2 "Night_2" 1 "Night_1" 0 "Off" ;
VAL_TABLE_ EngDiag_D_RqHtrn 7 "NotUsed4" 6 "NotUsed3" 5 "NotUsed2" 4 "NoUsed1" 3 "Eng_Diag_Cstdn" 2 "Eng_Diag_Run" 1 "Eng_Diag_Crank" 0 "Eng_Diag_Normal" ;
VAL_TABLE_ CamraStat 3 "FrtCam_TempUnavailOther" 2 "FrtCam_TempUnavailVisibile" 1 "Front_Camera_Service_Reqd" 0 "Front_Camera_OK" ;
VAL_TABLE_ ManRgen_D_Rq 3 "NotUsed2" 2 "NotUsed1" 1 "CustInitManExhFilterClean" 0 "No_Customer_Request" ;
VAL_TABLE_ Remote_Start_Status 3 "Invalid" 2 "Unknown" 1 "Remote" 0 "Null" ;
VAL_TABLE_ Lock_Subld 15 "Unused7" 14 "Unused6" 13 "Unused5" 12 "Unused4" 11 "Unused3" 10 "Unused2" 9 "Unused1" 8 "Customer_8" 7 "Customer_7" 6 "Customer_6" 5 "Customer_5" 4 "Customer_4" 3 "Customer_3" 2 "Customer_2" 1 "Customer_1" 0 "Null" ;
VAL_TABLE_ Brake_Fluid 3 "Invalid" 2 "Unknown" 1 "Low" 0 "OK" ;
VAL_TABLE_ Unknown_Invalid_FE_FF 255 "Invalid" 254 "Unknown" ;
VAL_TABLE_ Invalid_FF 255 "Invalid" ;
VAL_TABLE_ NotLow_Low 1 "Low" 0 "Not_Low" ;
VAL_TABLE_ Disabled_Enabled_Status 2 "Status" 3 "NotUsed" 1 "Enabled" 0 "Disabled" ;
VAL_TABLE_ Key_In_Ignition_Status 1 "In" 0 "Out" ;
VAL_TABLE_ Ignition_Status 0 "Unknown" 1 "Off" 15 "Invalid" 8 "Start" 4 "Run" 2 "Accessory" ;
VAL_TABLE_ Disabled_Enabled_Faulted 3 "Faulted" 2 "Unused" 1 "Enabled" 0 "Disabled" ;
VAL_TABLE_ Disabled_Enabled_NoSupport 2 "Unused" 3 "Not_Supported" 1 "Enabled" 0 "Disabled" ;
VAL_TABLE_ Unknown_Fault_FE_FF 255 "Fault" 254 "Unknown" ;
VAL_TABLE_ Null_Active 1 "Active" 0 "Null" ;
VAL_TABLE_ MemoryCmd 7 "Recall_3" 4 "Store_4" 3 "Store_3" 6 "Recall_2" 5 "Recall_1" 2 "Store_2" 1 "Store_1" 0 "Null" 8 "Recall_4" ;
VAL_TABLE_ HsaStat_D_Actl 7 "Faulty" 6 "FaultyWithDriverIndication" 5 "SlowRelease" 4 "FastRelease" 3 "ActiveBrakePedalReleased" 2 "ActiveBrakePedalPressed" 1 "FindingGradient" 0 "Inactive" ;
VAL_TABLE_ Off_Auto_Manual 3 "Undefined" 2 "Manual" 1 "Automatic" 0 "Off" ;
VAL_TABLE_ HsaStat_D_Dsply 7 "NotUsed3" 6 "NotUsed2" 5 "NotUsed1" 4 "NotAvailable" 3 "SlowReleaseWithChime" 2 "SlowReleaseWithoutChime" 1 "Active" 0 "Inactive" ;
VAL_TABLE_ PassRstrnInd_Req 3 "ABOnNotIllum_OffNotIllum" 2 "AirbagOnNot_Illum_OffIllum" 1 "AirbagOn_Illum_OffNotIllum" 0 "AirbagOn_Illum_Off_Illum" ;
VAL_TABLE_ GPS_dimension 2 "_3D" 1 "_2D" 0 "No_Fix" ;
VAL_TABLE_ GPS_Compass_dirctn 7 "NorthWest" 6 "West" 5 "SouthWest" 4 "South" 3 "SouthEast" 2 "East" 1 "NorthEast" 0 "North" ;
VAL_TABLE_ GPS_Actual_Infer 1 "Inferred_Position" 0 "Actual_Postition" ;
VAL_TABLE_ DrvHdcWarnInfo_D_Rq 3 "Undefined" 2 "Lamp_On_Continuously" 1 "Lamp_Flashing" 0 "Lamp_Off_Continuously" ;
VAL_TABLE_ Off_On 1 "On" 0 "Off" ;
VAL_TABLE_ CcMde_D_Actl 7 "TapDownWaiting" 6 "TapUpWaiting" 5 "Resuming_Low" 4 "Resuming_High" 3 "Decelerating" 2 "Accelerating" 1 "Keeping_Speed" 0 "Not_Active" ;
VAL_TABLE_ InactiveActive 1 "Active" 0 "Inactive" ;
VAL_TABLE_ Unknown_Invalid_1E_1F 31 "Invalid" 30 "Unknown" ;
VAL_TABLE_ Unknown_Invalid_3FFE_3FFF 16383 "Invalid" 16382 "Unknown" ;
VAL_TABLE_ NoYes 1 "Yes" 0 "No" ;
VAL_TABLE_ AwdRnge_D_Actl 7 "Unknown" 6 "High_Range_2wd" 5 "High_Range_Auto" 4 "High_Range_Locked" 3 "Neutral" 2 "Low_Range_2wd" 1 "Low_Range_Auto" 0 "Low_Range_Locked" ;
VAL_TABLE_ AwdLck_D_Stat 9 "Undefined" 8 "Under_External_Torque_Ctrl" 7 "Torque_Limited_by_Cmd" 6 "Fully_Locked_by_Cmd" 5 "Disabled" 4 "Warning" 3 "Fault" 2 "Inactive" 1 "Completely_Opened_by_Cmd" 0 "OK" ;
VAL_TABLE_ Unknown_Fault_3FE_3FF 1023 "Fault" 1022 "Unknown" ;
VAL_TABLE_ LockSwStat 3 "Invalid" 2 "Unlock" 1 "Lock" 0 "Null" ;
VAL_TABLE_ Null_Override 1 "Override" 0 "Null" ;
VAL_TABLE_ Off_On_Flash 3 "Not_Used" 2 "Flash" 1 "On" 0 "Off" ;
VAL_TABLE_ BeltBuckle 3 "Unknown" 2 "Unbelted" 1 "Belted" 0 "Faulty" ;
VAL_TABLE_ RILReqCoding 3 "Not_Used" 2 "Plant_Mode" 1 "On" 0 "Off" ;
VAL_TABLE_ Running_Board 3 "Unused" 2 "Manually_Deployed" 1 "All_Enabled" 0 "All_Disabled" ;
VAL_TABLE_ HudFlashRate 3 "Unused" 2 "Flash_4Hz_50Prct_DutyCycle" 1 "On" 0 "Off" ;
VAL_TABLE_ Turn_Seq 3 "Seq" 2 "On" 1 "Off" 0 "Null" ;
VAL_TABLE_ Rvc_Zoom 7 "Unknown" 6 "Invalid" 5 "Zoom_Level_V" 4 "Zoom_Level_IV" 3 "Zoom_Level_III" 2 "Zoom_Level_II" 1 "Zoom_Level_I" 0 "Off" ;
VAL_TABLE_ NotPark 1 "Park" 0 "Not_Park" ;
VAL_TABLE_ Electric_EOH 1 "Electric_Over_Hydraulic" 0 "Electric" ;
VAL_TABLE_ PersOptIn 1 "OPTED_IN" 0 "NOT_OPTED_IN" ;
VAL_TABLE_ PersonalSetUp 3 "Non_Moveable_Person" 2 "Moveable_Person" 1 "Vehicle" 0 "Factory" ;
VAL_TABLE_ Full_Limited 1 "Limited" 0 "Full" ;
VAL_TABLE_ NoConflict_Conflict 1 "Conflict" 0 "No_Conflict" ;
VAL_TABLE_ Assoc_Confirm 0 "None" 7 "Associate" 6 "Keycode_Rejected" 5 "Keycode_Accepted" 4 "In_Progress" 3 "Erase" 2 "Duplicate" 1 "Disassociate" ;
VAL_TABLE_ Complete_Inprogress 3 "Unused" 2 "Null" 1 "InProgress" 0 "Complete" ;
VAL_TABLE_ Null_Pers1_4 7 "Unused_3" 6 "Unused_2" 5 "Unused_1" 4 "PERS_4" 3 "PERS_3" 2 "PERS_2" 1 "PERS_1" 0 "Null" ;
VAL_TABLE_ Pers1_4 7 "Unused_3" 6 "Unused_2" 5 "Unused_1" 4 "Vehicle" 3 "PERS_4" 2 "PERS_3" 1 "PERS_2" 0 "PERS_1" ;
VAL_TABLE_ Null_Query 7 "Unused_2" 6 "Unused_1" 5 "Copy" 4 "Restore" 3 "Upload" 2 "Set" 1 "Query" 0 "Null" ;
VAL_TABLE_ CCOverridden 1 "Cruise_Overridden" 0 "Cruise_Req_Not_Overridden" ;
VAL_TABLE_ Ign_Key_Device_Type 15 "Invalid" 14 "Unknown" 3 "Key_Not_Prgrm_Read_Failure" 2 "Key_In_Ign_My_Key" 1 "Key_In_Ign_Standard_Key" 0 "Key_Read_In_Progress" ;
VAL_TABLE_ Off_No_Eff_Unknown_Invalid 3 "Invalid" 2 "Unknown" 1 "No_Effect" 0 "Off" ;
VAL_TABLE_ Null_Out 1 "Out" 0 "Null" ;
VAL_TABLE_ FUEL_SENSORS 1 "Dual_Sensors" 0 "Single_Sensor" ;

BO_ 3221225472 VECTOR__INDEPENDENT_SIG_MSG: 0 Vector__XXX
 SG_ TrailOnePdlMde_D_Ind : 0|3@0+ (1,0) [0|7] "SED" Vector__XXX
 SG_ BrkObdData_No_Actl : 0|8@0+ (1,0) [0|255] "unitless" Vector__XXX
 SG_ BrkObdIndex_No_Actl : 0|6@0+ (1,0) [0|63] "unitless" Vector__XXX
 SG_ RaceTrakMde_D_Stat : 0|2@0+ (1,0) [0|3] "SED" Vector__XXX
 SG_ SuspClkSync_No_Rq : 0|8@0+ (1,0) [0|253] "unitless" Vector__XXX
 SG_ PrplWhlPrim_Tq_RqMx : 0|12@0+ (8,0) [0|32760] "Nm" Vector__XXX
 SG_ HsaTrnAout_Tq_Rq : 0|16@0+ (4,-131072) [-131072|131060] "Nm" Vector__XXX
 SG_ HsaStat_D_Dsply : 0|3@0+ (1,0) [0|7] "SED" Vector__XXX
 SG_ CrnkInhbtActv_B_Stat : 0|1@0+ (1,0) [0|1] "SED" Vector__XXX
 SG_ CrnkInhbtHlthRate_B_Rq : 0|1@0+ (1,0) [0|1] "SED" Vector__XXX
 SG_ VehVActlBrk_No_Corr : 0|8@0+ (0.001,0.9) [0.9|1.153] "unitless" Vector__XXX
 SG_ SelDrvMdeMsgTxt2_D_Rq : 0|4@0+ (1,0) [0|15] "SED" Vector__XXX
 SG_ PrplBrkTqAsst_Pw_Rq : 0|8@0+ (100,0) [0|25500] "watts" Vector__XXX
 SG_ RearDiffLckLamp_D_Rq2 : 0|2@0+ (1,0) [0|3] "SED" Vector__XXX
 SG_ BpedDiffLckTq_No_Cs : 0|8@0+ (1,0) [0|255] "unitless" Vector__XXX
 SG_ SeatRelxPosDact_B_Stat : 0|1@0+ (1,0) [0|1] "SED" Vector__XXX
 SG_ SeatRelxPosActv_B_Stat : 0|1@0+ (1,0) [0|1] "SED" Vector__XXX
 SG_ SeatRelxPosSet_B_Stat : 0|1@0+ (1,0) [0|1] "SED" Vector__XXX
 SG_ StopStrtImccSel_B_Rq : 0|1@0+ (1,0) [0|1] "SED" Vector__XXX
 SG_ StopStrtImccTxt_D_Stat : 0|3@0+ (1,0) [0|7] "SED" Vector__XXX
 SG_ StopStrtImccSel_B_Falt : 0|1@0+ (1,0) [0|1] "SED" Vector__XXX
 SG_ LnchCtl_N_Rq2 : 0|8@0+ (50,0) [0|12750] "rpm" Vector__XXX
 SG_ LnchCtl_D_Rq2 : 0|2@0+ (1,0) [0|3] "SED" Vector__XXX
 SG_ DrvSlipCtlMde_B_Rq6 : 0|1@0+ (1,0) [0|1] "SED" Vector__XXX
 SG_ TrakApplActvSet_D_Rq : 0|4@0+ (1,0) [0|15] "SED" Vector__XXX
 SG_ TrakAppl_D_RqMnu : 0|5@0+ (1,0) [0|31] "SED" Vector__XXX
 SG_ VgfSet_D_Stat : 0|2@0+ (1,0) [0|3] "SED" Vector__XXX
 SG_ PtDrvMde_D_Rq : 0|4@0+ (1,0) [0|15] "SED" Vector__XXX
 SG_ DrvPerfMde_D_Rq : 0|2@0+ (1,0) [0|3] "SED" Vector__XXX
 SG_ StopStrtDrvMde_D_RqMnu : 0|2@0+ (1,0) [0|3] "SED" Vector__XXX
 SG_ FrostWarn_D_Stat : 0|2@0+ (1,0) [0|3] "SED" Vector__XXX
 SG_ PrkLckCtlEnbl_D_RqIpc : 0|2@0+ (1,0) [0|3] "SED" Vector__XXX
 SG_ Fda_B_Stat : 0|1@0+ (1,0) [0|1] "SED" Vector__XXX
 SG_ CabnAmb_Te2_Actl : 0|8@0+ (0.5,-42) [-42|85] "degC" Vector__XXX
 SG_ RearDiffLck_D_RqDrv4 : 0|2@0+ (1,0) [0|3] "SED" Vector__XXX
 SG_ HtrCoreRearSov_D_Stat : 0|3@0+ (1,0) [0|7] "SED" Vector__XXX
 SG_ CamraRearBttn_D_Stat : 0|1@0+ (1,0) [0|1] "SED" Vector__XXX
 SG_ TrailCtlSwtch_B_Stat : 0|1@0+ (1,0) [0|1] "SED" Vector__XXX
 SG_ GlvBoxRleas_No_Actl : 0|3@0+ (1,0) [0|7] "unitless" Vector__XXX
 SG_ LpdbDfrstFrOn_B_Rq : 0|1@0+ (1,0) [0|1] "SED" Vector__XXX
 SG_ LpdbDfrstFlOn_B_Rq : 0|1@0+ (1,0) [0|1] "SED" Vector__XXX
 SG_ LpdbAuxBlwr_B_Rq : 0|1@0+ (1,0) [0|1] "SED" Vector__XXX
 SG_ PrkAidSwtch_No_Cnt : 0|4@0+ (1,0) [0|15] "unitless" Vector__XXX
 SG_ PrkAidSwtch_D_RqDrv : 0|1@0+ (1,0) [0|1] "SED" Vector__XXX
 SG_ DrvSlipCtlMde_B_Rq : 0|1@0+ (1,0) [0|1] "SED" Vector__XXX
 SG_ CamraFrntBttn_D_Stat : 0|1@0+ (1,0) [0|1] "SED" Vector__XXX
 SG_ AutoTowAllw_D_RqMnu : 0|2@0+ (1,0) [0|3] "SED" Vector__XXX
 SG_ EngExhMdeQuiet_D_Rq : 0|2@0+ (1,0) [0|3] "SED" Vector__XXX
 SG_ Mc_VehDayNightUsrSel_St : 0|3@0+ (1,0) [0|7] "SED" Vector__XXX
 SG_ Mc_VehThemeUsrSel_St : 0|4@0+ (1,0) [0|15] "SED" Vector__XXX
 SG_ EngExhMdeQuiet_D2_Rq : 0|3@0+ (1,0) [0|7] "SED" Vector__XXX
 SG_ BrkLineLck_D_Rq : 0|2@0+ (1,0) [0|3] "SED" Vector__XXX
 SG_ ApaSwtch_D_RqDrv : 0|2@0+ (1,0) [0|3] "SED" Vector__XXX
 SG_ HvacBlwrRear_D_Stat : 0|5@0+ (1,0) [0|31] "SED" Vector__XXX
 SG_ ApaSwtch_No_Cnt : 0|4@0+ (1,0) [0|15] "unitless" Vector__XXX
 SG_ BattTracLoThres_D_Rq2 : 0|3@0+ (1,0) [0|7] "SED" Vector__XXX
 SG_ WwaActv_B_Stat : 0|1@0+ (1,0) [0|1] "SED" Vector__XXX
 SG_ OffRdSwtch_D_RqMnu : 0|2@0+ (1,0) [0|3] "SED" Vector__XXX
 SG_ SelDrvMdeSwtchOk_D_Stat : 0|2@0+ (1,0) [0|3] "SED" Vector__XXX
 SG_ AutoHoldSwtch_D_Stat2 : 0|2@0+ (1,0) [0|3] "SED" Vector__XXX
 SG_ PrkAidSwtch_D_RqDrv3 : 0|1@0+ (1,0) [0|1] "SED" Vector__XXX
 SG_ ApaSwtch_D_RqDrv3 : 0|2@0+ (1,0) [0|3] "SED" Vector__XXX
 SG_ StopStrtDrvMde_B_RqBtn2 : 0|1@0+ (1,0) [0|1] "SED" Vector__XXX

BO_ 1563 EPS_XCP_RES: 64 PSCM
 SG_ EPS_XCP_Res : 0|64@1+ (1,0) [0|0] "" Vector__XXX

BO_ 1562 EPS_XCP_REQ: 64 TSTR
 SG_ EPS_XCP_Req : 7|64@0+ (1,0) [0|0] ""  PSCM

BO_ 1565 EPS_Data_Pages_B: 8 PSCM
 SG_ EPS_DataPageB : 0|64@1+ (1,0) [0|0] "" Vector__XXX

BO_ 1564 EPS_Data_Pages_A: 8 PSCM
 SG_ EPS_DataPageA : 0|64@1+ (1,0) [0|0] "" Vector__XXX

BO_ 1569 FIH_Out_2: 8 PSCM
 SG_ HSCAN_Out2_Low : 7|32@0+ (1,0) [0|0] "" Vector__XXX
 SG_ HSCAN_Out2_High : 39|32@0+ (1,0) [0|0] "" Vector__XXX

BO_ 1568 FIH_Out_1: 8 PSCM
 SG_ HSCAN_Out1_Low : 7|32@0+ (1,0) [0|0] "" Vector__XXX
 SG_ HSCAN_Out1_High : 39|32@0+ (1,0) [0|0] "" Vector__XXX

BO_ 1567 FIH_In_2: 8 TSTR
 SG_ HSCAN_In2_Low : 7|32@0+ (1,0) [0|0] ""  PSCM
 SG_ HSCAN_In2_High : 39|32@0+ (1,0) [0|0] ""  PSCM

BO_ 1566 FIH_In_1: 8 TSTR
 SG_ HSCAN_In1_Low : 7|32@0+ (1,0) [0|0] ""  PSCM
 SG_ HSCAN_In1_High : 39|32@0+ (1,0) [0|0] ""  PSCM

BO_ 465 EngineData_12_FD3: 8 GWM
 SG_ NnMtvMdeLim_B_Stat : 47|1@0+ (1,0) [0|1] "SED" Vector__XXX
 SG_ HwyVLim_B_Stat : 32|1@0+ (1,0) [0|1] "SED" Vector__XXX
 SG_ CtyVLim_B_Stat : 33|1@0+ (1,0) [0|1] "SED" Vector__XXX
 SG_ SecMdeLim_B_Stat : 34|1@0+ (1,0) [0|1] "SED" Vector__XXX
 SG_ PrkLotVLim_B_Stat : 35|1@0+ (1,0) [0|1] "SED" Vector__XXX
 SG_ PwPckInhbtLim_B_Stat : 36|1@0+ (1,0) [0|1] "SED" Vector__XXX
 SG_ PrplLim_B_Stat : 37|1@0+ (1,0) [0|1] "SED" Vector__XXX
 SG_ VflCstmLim_B_Stat : 38|1@0+ (1,0) [0|1] "SED" Vector__XXX
 SG_ VflCstmVLim_B_Stat : 39|1@0+ (1,0) [0|1] "SED" Vector__XXX
 SG_ Fleet2_D_StatLim : 26|3@0+ (1,0) [0|7] "SED" Vector__XXX
 SG_ Fleet1_D_StatLim : 18|3@0+ (1,0) [0|7] "SED" Vector__XXX
 SG_ Fleet2_D_ResLim : 31|5@0+ (1,0) [0|31] "SED" Vector__XXX
 SG_ Fleet1_D_ResLim : 23|5@0+ (1,0) [0|31] "SED" Vector__XXX
 SG_ StlnVeh2_D_StatLim : 10|3@0+ (1,0) [0|7] "SED" Vector__XXX
 SG_ StlnVeh1_D_StatLim : 2|3@0+ (1,0) [0|7] "SED" Vector__XXX
 SG_ StlnVeh2_D_ResLim : 15|5@0+ (1,0) [0|31] "SED" Vector__XXX
 SG_ StlnVeh1_D_ResLim : 7|5@0+ (1,0) [0|31] "SED" Vector__XXX

BO_ 2609967320 OTAPhysGWM_ECGtoDCMH: 64 GWM
 SG_ OTAPhysGWM_ECGtoDCMH : 7|29@0+ (1,0) [0|536870911] "unitless" Vector__XXX

BO_ 2611015896 PARSEDPhysGWM_ECGtoDCMH: 64 GWM
 SG_ PARSEDPhysGWM_ECGtoDCMH : 7|29@0+ (1,0) [0|536870911] "unitless" Vector__XXX

BO_ 2612064472 PARSEDPushFcGWM_ECGtoDCMH: 8 GWM
 SG_ PARSEDPushFcGWM_ECGtoDCMH : 7|29@0+ (1,0) [0|536870911] "unitless" Vector__XXX

BO_ 2613113048 SymKeyPhysGWM_ECGtoDCMH: 64 GWM
 SG_ SymKeyPhysGWM_ECGtoDCMH : 7|29@0+ (1,0) [0|536870911] "unitless" Vector__XXX

BO_ 2609966296 OTAPhysGWM_ECGtoDCMG: 64 GWM
 SG_ OTAPhysGWM_ECGtoDCMG : 7|29@0+ (1,0) [0|536870911] "unitless" Vector__XXX

BO_ 2611014872 PARSEDPhysGWM_ECGtoDCMG: 64 GWM
 SG_ PARSEDPhysGWM_ECGtoDCMG : 7|29@0+ (1,0) [0|536870911] "unitless" Vector__XXX

BO_ 2612063448 PARSEDPushFcGWM_ECGtoDCMG: 8 GWM
 SG_ PARSEDPushFcGWM_ECGtoDCMG : 7|29@0+ (1,0) [0|536870911] "unitless" Vector__XXX

BO_ 2613112024 SymKeyPhysGWM_ECGtoDCMG: 64 GWM
 SG_ SymKeyPhysGWM_ECGtoDCMG : 7|29@0+ (1,0) [0|536870911] "unitless" Vector__XXX

BO_ 2609975512 OTAPhysGWM_ECGtoSCCM: 64 GWM
 SG_ OTAPhysGWM_ECGtoSCCM : 7|29@0+ (1,0) [0|536870911] "unitless"  SCCM

BO_ 2610126916 OTAPhysSCCMtoGWM_ECG: 64 SCCM
 SG_ OTAPhysSCCMtoGWM_ECG : 7|29@0+ (1,0) [0|536870911] "unitless"  GWM

BO_ 2612072664 PARSEDPushFcGWM_ECGtoSCCM: 8 GWM
 SG_ PARSEDPushFcGWM_ECGtoSCCM : 7|29@0+ (1,0) [0|536870911] "unitless"  SCCM

BO_ 2612224068 PARSEDPushSCCMtoGWM_ECG: 8 SCCM
 SG_ PARSEDPushSCCMtoGWM_ECG : 7|29@0+ (1,0) [0|536870911] "unitless"  GWM

BO_ 2613121240 SymKeyPhysGWM_ECGtoSCCM: 64 GWM
 SG_ SymKeyPhysGWM_ECGtoSCCM : 7|29@0+ (1,0) [0|536870911] "unitless"  SCCM

BO_ 2613272644 SymKeyPhysSCCMtoGWM_ECG: 64 SCCM
 SG_ SymKeyPhysSCCMtoGWM_ECG : 7|29@0+ (1,0) [0|536870911] "unitless"  GWM

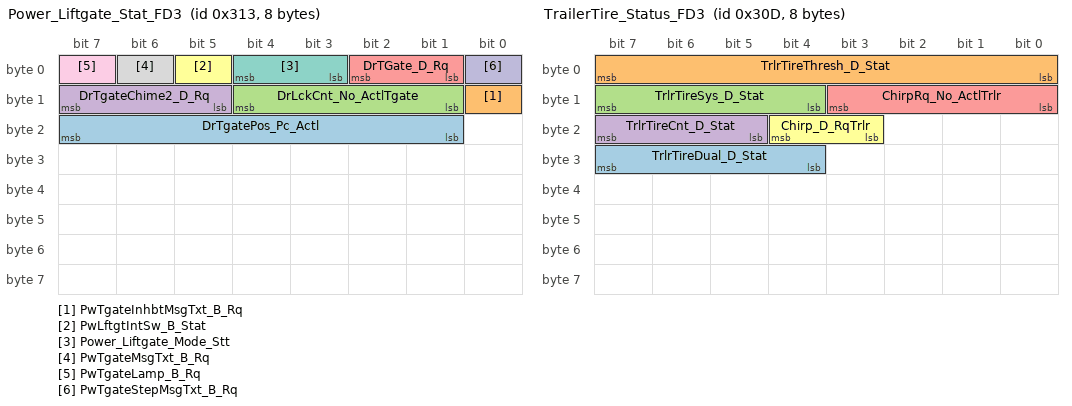
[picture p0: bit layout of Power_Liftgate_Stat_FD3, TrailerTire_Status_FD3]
BO_ 787 Power_Liftgate_Stat_FD3: 8 GWM
 SG_ DrTgatePos_Pc_Actl : 23|7@0+ (1,0) [0|125] "percent"  IPMA_ADAS
 SG_ PwTgateInhbtMsgTxt_B_Rq : 8|1@0+ (1,0) [0|1] "SED" Vector__XXX
 SG_ DrLckCnt_No_ActlTgate : 12|4@0+ (1,0) [0|15] "unitless" Vector__XXX
 SG_ DrTgateChime2_D_Rq : 15|3@0+ (1,0) [0|7] "SED" Vector__XXX
 SG_ DrTGate_D_Rq : 2|2@0+ (1,0) [0|3] "SED" Vector__XXX
 SG_ PwLftgtIntSw_B_Stat : 5|1@0+ (1,0) [0|1] "SED" Vector__XXX
 SG_ Power_Liftgate_Mode_Stt : 4|2@0+ (1,0) [0|3] "SED" Vector__XXX
 SG_ PwTgateMsgTxt_B_Rq : 6|1@0+ (1,0) [0|1] "SED" Vector__XXX
 SG_ PwTgateLamp_B_Rq : 7|1@0+ (1,0) [0|1] "SED" Vector__XXX
 SG_ PwTgateStepMsgTxt_B_Rq : 0|1@0+ (1,0) [0|1] "SED" Vector__XXX

BO_ 781 TrailerTire_Status_FD3: 8 GWM
 SG_ TrlrTireDual_D_Stat : 31|4@0+ (1,0) [0|15] "SED" Vector__XXX
 SG_ TrlrTireThresh_D_Stat : 7|8@0+ (1,0) [0|255] "unitless" Vector__XXX
 SG_ TrlrTireSys_D_Stat : 15|4@0+ (1,0) [0|15] "SED"  IPMA_ADAS
 SG_ TrlrTireCnt_D_Stat : 23|3@0+ (1,0) [0|6] "SED" Vector__XXX
 SG_ ChirpRq_No_ActlTrlr : 11|4@0+ (1,0) [0|15] "unitless" Vector__XXX
 SG_ Chirp_D_RqTrlr : 20|2@0+ (1,0) [0|3] "SED" Vector__XXX

BO_ 931 Body_Info_9_FD3: 16 GWM
 SG_ VehOnSrc_D_Stat : 19|4@0+ (1,0) [0|15] "SED"  DDM,PDM
 SG_ StrtrMtrCtlDStat_No_Cs : 31|8@0+ (1,0) [0|255] "unitless" Vector__XXX
 SG_ EngStrtActv_B_Stat : 39|1@0+ (1,0) [0|1] "SED" Vector__XXX
 SG_ EngStrt_B_Rq : 0|1@0+ (1,0) [0|1] "SED" Vector__XXX
 SG_ DrvInCtl_B_Stat : 1|1@0+ (1,0) [0|1] "SED" Vector__XXX
 SG_ PtWakeReas_D_Stat : 38|4@0+ (1,0) [0|15] "SED" Vector__XXX
 SG_ CrnkInhbt_No_Cs : 15|8@0+ (1,0) [0|255] "unitless" Vector__XXX
 SG_ CrnkInhbt_No_Cnt : 6|4@0+ (1,0) [0|15] "unitless" Vector__XXX
 SG_ CrnkInhbt_B_Stat : 7|1@0+ (1,0) [0|1] "SED" Vector__XXX
 SG_ AdvStrt_No_Stat : 23|4@0+ (1,0) [0|15] "unitless" Vector__XXX
 SG_ IgnPreOffActv_B_Stat : 2|1@0+ (1,0) [0|1] "SED" Vector__XXX

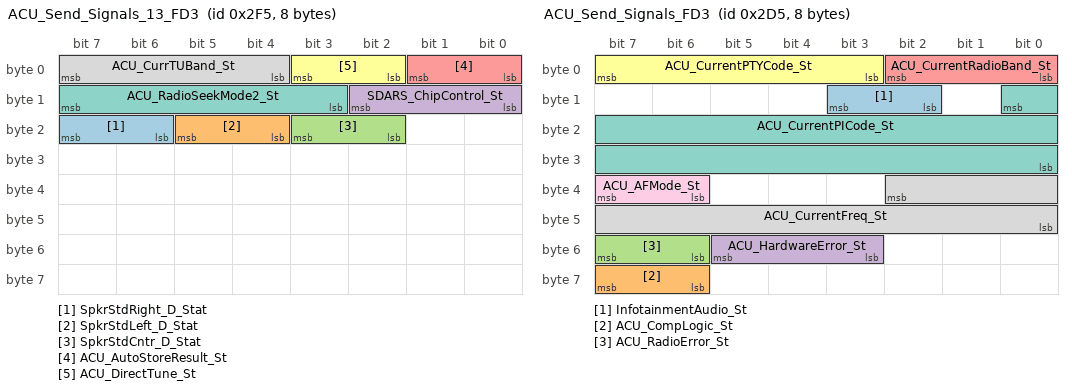
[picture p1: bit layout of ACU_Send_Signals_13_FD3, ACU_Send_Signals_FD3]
BO_ 757 ACU_Send_Signals_13_FD3: 8 GWM
 SG_ SpkrStdRight_D_Stat : 23|2@0+ (1,0) [0|3] "SED" Vector__XXX
 SG_ SpkrStdLeft_D_Stat : 21|2@0+ (1,0) [0|3] "SED" Vector__XXX
 SG_ SpkrStdCntr_D_Stat : 19|2@0+ (1,0) [0|3] "SED" Vector__XXX
 SG_ SDARS_ChipControl_St : 10|3@0+ (1,0) [0|7] "SED" Vector__XXX
 SG_ ACU_AutoStoreResult_St : 1|2@0+ (1,0) [0|3] "SED" Vector__XXX
 SG_ ACU_DirectTune_St : 3|2@0+ (1,0) [0|3] "SED" Vector__XXX
 SG_ ACU_RadioSeekMode2_St : 15|5@0+ (1,0) [0|31] "SED"  DDM,PDM
 SG_ ACU_CurrTUBand_St : 7|4@0+ (1,0) [0|15] "SED"  DDM,PDM

BO_ 725 ACU_Send_Signals_FD3: 8 GWM
 SG_ InfotainmentAudio_St : 11|2@0+ (1,0) [0|3] "SED" Vector__XXX
 SG_ ACU_CompLogic_St : 63|2@0+ (1,0) [0|3] "SED" Vector__XXX
 SG_ ACU_RadioError_St : 55|2@0+ (1,0) [0|3] "SED" Vector__XXX
 SG_ ACU_HardwareError_St : 53|3@0+ (1,0) [0|7] "SED" Vector__XXX
 SG_ ACU_CurrentRadioBand_St : 2|3@0+ (1,0) [0|7] "SED" Vector__XXX
 SG_ ACU_CurrentPTYCode_St : 7|5@0+ (1,0) [0|31] "unitless" Vector__XXX
 SG_ ACU_CurrentPICode_St : 8|17@0+ (1,0) [0|65535] "unitless" Vector__XXX
 SG_ ACU_CurrentFreq_St : 34|11@0+ (1,0) [0|1557] "unitless"  DDM,PDM
 SG_ ACU_AFMode_St : 39|2@0+ (1,0) [0|3] "SED" Vector__XXX

BO_ 932 Body_Info_13_FD3: 16 GWM
 SG_ RmtCtlBattMntr_B_Falt : 16|1@0+ (1,0) [0|1] "SED" Vector__XXX
 SG_ VehStrtInhbt_D_Stat : 23|1@0+ (1,0) [0|1] "SED"  DDM,PDM
 SG_ VehOnCtl_D_Stat : 22|2@0+ (1,0) [0|3] "SED" Vector__XXX
 SG_ VehOnSrc2_D_Stat : 20|4@0+ (1,0) [0|15] "SED"  DDM,PDM
 SG_ CanMsg3A4_No_Crc : 7|8@0+ (1,0) [0|255] "unitless" Vector__XXX
 SG_ CanMsg3A4_No_Cnt : 11|4@0+ (1,0) [0|15] "unitless" Vector__XXX
 SG_ VehInhbtMde_D_Stat : 14|3@0+ (1,0) [0|7] "SED" Vector__XXX
 SG_ ChildLck_D_Dsply : 31|2@0+ (1,0) [0|3] "SED"  DDM

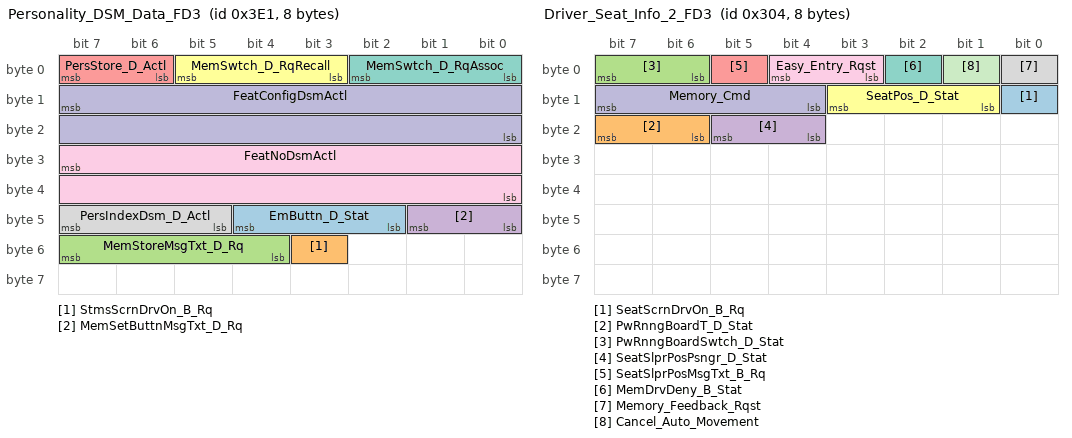
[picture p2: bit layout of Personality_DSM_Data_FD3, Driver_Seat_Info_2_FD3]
BO_ 993 Personality_DSM_Data_FD3: 8 GWM
 SG_ EmButtn_D_Stat : 44|3@0+ (1,0) [0|7] "SED"  _delete
 SG_ StmsScrnDrvOn_B_Rq : 51|1@0+ (1,0) [0|1] "SED" Vector__XXX
 SG_ MemStoreMsgTxt_D_Rq : 55|4@0+ (1,0) [0|15] "SED" Vector__XXX
 SG_ MemSetButtnMsgTxt_D_Rq : 41|2@0+ (1,0) [0|3] "SED" Vector__XXX
 SG_ PersStore_D_Actl : 7|2@0+ (1,0) [0|3] "SED" Vector__XXX
 SG_ MemSwtch_D_RqRecall : 5|3@0+ (1,0) [0|7] "SED" Vector__XXX
 SG_ MemSwtch_D_RqAssoc : 2|3@0+ (1,0) [0|7] "SED" Vector__XXX
 SG_ PersIndexDsm_D_Actl : 47|3@0+ (1,0) [0|7] "SED" Vector__XXX
 SG_ FeatNoDsmActl : 31|16@0+ (1,0) [0|65535] "Number" Vector__XXX
 SG_ FeatConfigDsmActl : 15|16@0+ (1,0) [0|65535] "Undefined" Vector__XXX

BO_ 945 Body_Info_7_FD3: 16 GWM
 SG_ AdasRelay_B_Stat2 : 35|1@0+ (1,0) [0|1] "SED" Vector__XXX
 SG_ StrtrMtrCtlMsgTxt_D_Rq2 : 55|4@0+ (1,0) [0|15] "SED" Vector__XXX
 SG_ PrkLckCtlMsgTxt_D2_Rq : 2|3@0+ (1,0) [0|7] "SED" Vector__XXX
 SG_ PwLoApim_T_Actl : 34|11@0+ (1,0) [0|2047] "minute" Vector__XXX
 SG_ KeyOffMde_D_Actl : 7|4@0+ (1,0) [0|15] "SED"  PDM,DDM
 SG_ KeyPadCodeDgt7_D_Dsply : 39|4@0+ (1,0) [0|15] "SED" Vector__XXX
 SG_ KeyPadCodeDgt6_D_Dsply : 27|4@0+ (1,0) [0|15] "SED" Vector__XXX
 SG_ KeyPadCodeDgt5_D_Dsply : 31|4@0+ (1,0) [0|15] "SED" Vector__XXX
 SG_ KeyPadCodeDgt4_D_Dsply : 19|4@0+ (1,0) [0|15] "SED" Vector__XXX
 SG_ KeyPadCodeDgt3_D_Dsply : 23|4@0+ (1,0) [0|15] "SED" Vector__XXX
 SG_ KeyPadCodeDgt2_D_Dsply : 11|4@0+ (1,0) [0|15] "SED" Vector__XXX
 SG_ KeyPadCodeDgt1_D_Dsply : 15|4@0+ (1,0) [0|15] "SED" Vector__XXX
 SG_ PrkLckCtlLatch_B_Rq : 3|1@0+ (1,0) [0|1] "SED" Vector__XXX

BO_ 772 Driver_Seat_Info_2_FD3: 8 GWM
 SG_ SeatScrnDrvOn_B_Rq : 8|1@0+ (1,0) [0|1] "SED" Vector__XXX
 SG_ PwRnngBoardT_D_Stat : 23|2@0+ (1,0) [0|3] "SED" Vector__XXX
 SG_ PwRnngBoardSwtch_D_Stat : 7|2@0+ (1,0) [0|3] "SED" Vector__XXX
 SG_ SeatSlprPosPsngr_D_Stat : 21|2@0+ (1,0) [0|3] "SED" Vector__XXX
 SG_ SeatSlprPosMsgTxt_B_Rq : 5|1@0+ (1,0) [0|1] "SED" Vector__XXX
 SG_ SeatPos_D_Stat : 11|3@0+ (1,0) [0|7] "SED" Vector__XXX
 SG_ MemDrvDeny_B_Stat : 2|1@0+ (1,0) [0|1] "SED" Vector__XXX
 SG_ Memory_Feedback_Rqst : 0|1@0+ (1,0) [0|1] "SED" Vector__XXX
 SG_ Easy_Entry_Rqst : 4|2@0+ (1,0) [0|3] "SED" Vector__XXX
 SG_ Memory_Cmd : 15|4@0+ (1,0) [0|15] "SED"  PDM,DDM
 SG_ Cancel_Auto_Movement : 1|1@0+ (1,0) [0|1] "SED"  PDM,DDM

BO_ 2613219544 SymKeyPhysGWM_ECGtoPDM: 64 GWM
 SG_ SymKeyPhysGWM_ECGtoPDM : 7|29@0+ (1,0) [0|536870911] "unitless"  PDM

CM_ "New CAN FD network (Flexible Data Rate)";
CM_ BU_ HCM "Headlamp Ctrl. Mod.A, Adaptive Headlamps";
CM_ BU_ IPMA_ADAS "Image Processing Module A - Advanced Driver Assistance System";
CM_ BU_ PSCM "Power Steering Control Module";
CM_ BU_ GWM "Gateway Module";
CM_ BU_ SCCM "Steering Column Control Module, SWC Steering Wheel Controller (Stalk Module) ";
CM_ BU_ PDM "Passenger Front Door Module ";
CM_ BU_ DDM "Driver Front Door Module";
CM_ BU_ GENERIC "Holding pattern ECU for developmental messages";
CM_ BU_ TSTR "Diagnostic Tester";
CM_ BO_ 3221225472 "This is a message for not used signals, created by Vector CANdb++ DBC OLE DB Provider.";
CM_ SG_ 3221225472 BrkObdData_No_Actl "Signal not transmitted on gas, diesel and HEV.  Only supported on PHEV.";
CM_ SG_ 3221225472 BrkObdIndex_No_Actl "Signal not transmitted on gas, diesel and HEV.  Only supported on PHEV.";
CM_ SG_ 3221225472 Mc_VehDayNightUsrSel_St "Object.BodyInterface.Settings.VehicleDayNightUserSelection
Object.BodyInterface.Status.AMDayNightSensitivity";
CM_ SG_ 3221225472 Mc_VehThemeUsrSel_St "Object.BodyInterface.Settings.VehicleThemeUserSelection";
CM_ SG_ 931 CrnkInhbt_No_Cs "Signal not transmitted on gas and HEV variants.";
CM_ SG_ 931 CrnkInhbt_No_Cnt "Signal not transmitted on gas and HEV variants.";
CM_ SG_ 757 ACU_AutoStoreResult_St "Object Tuner. RadioSeekModeResult";
CM_ SG_ 757 ACU_DirectTune_St "Object.Tuner.DirectTune";
CM_ SG_ 757 ACU_RadioSeekMode2_St "Object Tuner.RadioSeekMode2";
CM_ SG_ 757 ACU_CurrTUBand_St "Object.Tuner.CurrentTUBand";
CM_ SG_ 725 ACU_CompLogic_St "Object.CDCompLogic_St ";
CM_ SG_ 725 ACU_RadioError_St "Object Audio Management Audio Client.AudioError.RadioError";
CM_ SG_ 725 ACU_HardwareError_St "Object Audio Management Audio Client.AudioError.HardwareError";
CM_ SG_ 725 ACU_CurrentRadioBand_St "Object Tuner.CurrentRadioBand";
CM_ SG_ 725 ACU_CurrentPTYCode_St "Object Tuner.CurrentPTYCode

$0: Invalid
$1: PTY 1 (News)
..
$1F: PTY 31 (Alarm)";
CM_ SG_ 725 ACU_CurrentPICode_St "Object Tuner.CurrentPICode";
CM_ SG_ 725 ACU_CurrentFreq_St "Object Tuner.CurrentFreq

AM: Freq = 153+ Offset kHz.
Offset 0..1557 

FM: Freq = 76+ Offset*0.05 MHz. Offset 0..640
Selected tuned band determine frequency (kHz or MHz).";
CM_ SG_ 725 ACU_AFMode_St "Object Tuner.AFMode";
CM_ BO_ 932 "NOTE: START BITS 8-11 MUST BE OPEN SPEC REQUIREMENT";
CM_ SG_ 932 CanMsg3A4_No_Crc "Signal not transmitted on gas and HEV variants.";
CM_ SG_ 932 CanMsg3A4_No_Cnt "Signal not transmitted on gas and HEV variants.";
CM_ SG_ 772 Memory_Feedback_Rqst "Updated to 1 bit for CGEA, Not backwards compatible";
BA_DEF_ BO_  "VFrameFormat" ENUM  "StandardCAN","ExtendedCAN","reserved","reserved","reserved","reserved","reserved","reserved","reserved","reserved","reserved","reserved","reserved","reserved","StandardCAN_FD","ExtendedCAN_FD";
BA_DEF_  "BusType" STRING ;
BA_DEF_ BO_  "FrameRouting" STRING ;
BA_DEF_ BO_  "NetworkInitialization" ENUM  "No","Yes";
BA_DEF_ BO_  "GenMsgStartDelayTime" INT 0 10000;
BA_DEF_ BO_  "GenMsgNrOfRepetition" INT 0 100;
BA_DEF_ BO_  "GenMsgDelayTime" INT 0 1000;
BA_DEF_ BO_  "GenMsgCycleTime" INT 0 100000;
BA_DEF_ BO_  "GenMsgSendType" ENUM  "FixedPeriodic","Event","EnabledPeriodic","NotUsed","NotUsed","EventPeriodic","NotUsed","NotUsed","NoMsgSendType";
BA_DEF_ SG_  "U_P702_MY2024_Tx" ENUM  "No","Yes";
BA_DEF_ SG_  "U_V710_MY2023_Tx" ENUM  "No","Yes";
BA_DEF_ SG_  "U_CDX74X_MY2024_Tx" ENUM  "No","Yes";
BA_DEF_ SG_  "U_P708_MY2023_Tx" ENUM  "No","Yes";
BA_DEF_ SG_  "U_V713AV_MY2022_Tx" ENUM  "No","Yes";
BA_DEF_ SG_  "U_V713N_MY2022_Tx" ENUM  "No","Yes";
BA_DEF_ SG_  "ECGUsedTxSignal" ENUM  "No","Yes";
BA_DEF_ SG_  "U_P702_MY2024_Rx" ENUM  "No","Yes";
BA_DEF_ SG_  "U_V710_MY2023_Rx" ENUM  "No","Yes";
BA_DEF_ SG_  "U_CDX74X_MY2024_Rx" ENUM  "No","Yes";
BA_DEF_ SG_  "U_CDX707_MY2023_Rx" ENUM  "No","Yes";
BA_DEF_ SG_  "U_P708_MY2023_Rx" ENUM  "No","Yes";
BA_DEF_ SG_  "U_V713N_MY2022_Rx" ENUM  "No","Yes";
BA_DEF_ SG_  "ECGUsedRxSignal" ENUM  "No","Yes";
BA_DEF_ SG_  "UsedOnPgmDBC" ENUM  "No","Yes";
BA_DEF_ SG_  "ContentDependant" ENUM  "No","Yes";
BA_DEF_ SG_  "GenSigStartValue" HEX 0 268435455;
BA_DEF_ SG_  "MetaData" ENUM  "No","Yes";
BA_DEF_ SG_  "WakeupSignal" ENUM  "No","Yes";
BA_DEF_ SG_  "GenSigInactiveValue" INT 0 100000;
BA_DEF_ SG_  "GenSigSendType" ENUM  "Cyclic","OnWrite","vector_leerstring","OnChange","vector_leerstring","IfActive","vector_leerstring","NoSigSendType";
BA_DEF_ BO_  "TpTxIndex" INT 0 536870911;
BA_DEF_ BO_  "OvtpPushApplication" ENUM  "FALSE","TRUE";
BA_DEF_ BO_  "SCP_FreshnessValueLength" INT 0 512;
BA_DEF_ BO_  "SCP_DataId" INT 0 17663;
BA_DEF_ BO_  "SCP_FreshnessValueTxLength" INT 0 512;
BA_DEF_ BO_  "SCP_AuthInfoTxLength" INT 0 512;
BA_DEF_ BO_  "SC_Message" ENUM  "No","Yes";
BA_DEF_ BO_  "GenMsgRoutingTimeoutTime" INT 0 5000;
BA_DEF_ BO_  "MessageGateway" ENUM  "No","Yes";
BA_DEF_ BO_  "NmAsrMessage" ENUM  "No","Yes";
BA_DEF_ BO_  "DiagState" ENUM  "No","Yes";
BA_DEF_ BO_  "DiagRequest" ENUM  "No","Yes";
BA_DEF_ BO_  "DiagResponse" ENUM  "No","Yes";
BA_DEF_ BO_  "GenMsgILSupport" ENUM  "No","Yes";
BA_DEF_ BU_  "OvtpOperationMode" ENUM  "SERVER","CLIENT";
BA_DEF_ BU_  "OvtpEcuAddress" INT 0 1022;
BA_DEF_ BU_  "ILUsed" ENUM  "No","Yes";
BA_DEF_ BU_  "Terminator" ENUM  "No","Yes";
BA_DEF_ BU_  "NodeWakeUpTime" INT 0 10000;
BA_DEF_ BU_  "NodeStartUpTime" INT 0 10000;
BA_DEF_ BU_  "NmAsrNodeIdentifier" HEX 0 255;
BA_DEF_ BU_  "NmAsrNode" ENUM  "No","Yes";
BA_DEF_ BU_  "PowerType" ENUM  "Switched","Latched","Sleep","vector_leerstring","vector_leerstring";
BA_DEF_ BU_  "NmNode" ENUM  "No","Yes";
BA_DEF_ BU_  "NmStationAddress" INT 0 255;
BA_DEF_ BU_  "NosPackage" ENUM  "None","I3_1","I3_2","1.0.1","RP","EuCD","Volcano","I3_3","FNOS_Autosar";
BA_DEF_ BU_  "LIN_Master" ENUM  "No","Yes";
BA_DEF_ BU_  "PackageID" STRING ;
BA_DEF_ BU_  "GatewayECU" ENUM  "No","Yes";
BA_DEF_  "NetworkSpeed" ENUM  "500kBits/s","125kBit/s";
BA_DEF_  "VersionNumber" INT 0 10000;
BA_DEF_  "StarNetworkGwType" ENUM  "0=NotDefined","1=HS1","2=HS2","3=HS3","4=HS4","5=HS5","6=MS1","7=HS6","8=HS7","9=MS2","10=FD1","11=FD2","12=FD3","13=FD4","14=FD5","15=FD6","16=FD7","17=FD8";
BA_DEF_  "CMDB_Version" STRING ;
BA_DEF_  "NmType" STRING ;
BA_DEF_  "NmAsrMessageCount" INT 128 256;
BA_DEF_  "NmAsrBaseAddress" HEX 1280 1408;
BA_DEF_  "DBName" STRING ;
BA_DEF_  "VersionDay" INT 1 31;
BA_DEF_  "Manufacturer" STRING ;
BA_DEF_  "VersionMonth" INT 1 12;
BA_DEF_  "VersionYear" INT 2000 3000;
BA_DEF_  "NmBaseAddress" HEX 1280 1280;
BA_DEF_  "NmMessageCount" INT 0 128;
BA_DEF_REL_ BU_SG_REL_  "SC_Verification" ENUM  "No","Yes";
BA_DEF_DEF_  "VFrameFormat" "ExtendedCAN_FD";
BA_DEF_DEF_  "BusType" "";
BA_DEF_DEF_  "FrameRouting" "";
BA_DEF_DEF_  "NetworkInitialization" "Yes";
BA_DEF_DEF_  "GenMsgStartDelayTime" 0;
BA_DEF_DEF_  "GenMsgNrOfRepetition" 1;
BA_DEF_DEF_  "GenMsgDelayTime" 20;
BA_DEF_DEF_  "GenMsgCycleTime" 0;
BA_DEF_DEF_  "GenMsgSendType" "NoMsgSendType";
BA_DEF_DEF_  "U_P702_MY2024_Tx" "No";
BA_DEF_DEF_  "U_V710_MY2023_Tx" "No";
BA_DEF_DEF_  "U_CDX74X_MY2024_Tx" "No";
BA_DEF_DEF_  "U_P708_MY2023_Tx" "No";
BA_DEF_DEF_  "U_V713AV_MY2022_Tx" "No";
BA_DEF_DEF_  "U_V713N_MY2022_Tx" "No";
BA_DEF_DEF_  "ECGUsedTxSignal" "No";
BA_DEF_DEF_  "U_P702_MY2024_Rx" "No";
BA_DEF_DEF_  "U_V710_MY2023_Rx" "No";
BA_DEF_DEF_  "U_CDX74X_MY2024_Rx" "No";
BA_DEF_DEF_  "U_CDX707_MY2023_Rx" "No";
BA_DEF_DEF_  "U_P708_MY2023_Rx" "No";
BA_DEF_DEF_  "U_V713N_MY2022_Rx" "No";
BA_DEF_DEF_  "ECGUsedRxSignal" "No";
BA_DEF_DEF_  "UsedOnPgmDBC" "Yes";
BA_DEF_DEF_  "ContentDependant" "No";
BA_DEF_DEF_  "GenSigStartValue" 0;
BA_DEF_DEF_  "MetaData" "No";
BA_DEF_DEF_  "WakeupSignal" "No";
BA_DEF_DEF_  "GenSigInactiveValue" 0;
BA_DEF_DEF_  "GenSigSendType" "NoSigSendType";
BA_DEF_DEF_  "TpTxIndex" 0;
BA_DEF_DEF_  "OvtpPushApplication" "FALSE";
BA_DEF_DEF_  "SCP_FreshnessValueLength" 64;
BA_DEF_DEF_  "SCP_DataId" 0;
BA_DEF_DEF_  "SCP_FreshnessValueTxLength" 11;
BA_DEF_DEF_  "SCP_AuthInfoTxLength" 53;
BA_DEF_DEF_  "SC_Message" "No";
BA_DEF_DEF_  "GenMsgRoutingTimeoutTime" 0;
BA_DEF_DEF_  "MessageGateway" "No";
BA_DEF_DEF_  "NmAsrMessage" "No";
BA_DEF_DEF_  "DiagState" "No";
BA_DEF_DEF_  "DiagRequest" "No";
BA_DEF_DEF_  "DiagResponse" "No";
BA_DEF_DEF_  "GenMsgILSupport" "Yes";
BA_DEF_DEF_  "OvtpOperationMode" "SERVER";
BA_DEF_DEF_  "OvtpEcuAddress" 0;
BA_DEF_DEF_  "ILUsed" "Yes";
BA_DEF_DEF_  "Terminator" "No";
BA_DEF_DEF_  "NodeWakeUpTime" 10;
BA_DEF_DEF_  "NodeStartUpTime" 250;
BA_DEF_DEF_  "NmAsrNodeIdentifier" 128;
BA_DEF_DEF_  "NmAsrNode" "No";
BA_DEF_DEF_  "PowerType" "Switched";
BA_DEF_DEF_  "NmNode" "No";
BA_DEF_DEF_  "NmStationAddress" 0;
BA_DEF_DEF_  "NosPackage" "I3_3";
BA_DEF_DEF_  "LIN_Master" "No";
BA_DEF_DEF_  "PackageID" "08.05.00.00.71.xx.xx.rr.00.00";
BA_DEF_DEF_  "GatewayECU" "No";
BA_DEF_DEF_  "NetworkSpeed" "500kBits/s";
BA_DEF_DEF_  "VersionNumber" 1;
BA_DEF_DEF_  "StarNetworkGwType" "0=NotDefined";
BA_DEF_DEF_  "CMDB_Version" "v11.01";
BA_DEF_DEF_  "NmType" "Ford-OSEK";
BA_DEF_DEF_  "NmAsrMessageCount" 128;
BA_DEF_DEF_  "NmAsrBaseAddress" 1408;
BA_DEF_DEF_  "DBName" "";
BA_DEF_DEF_  "VersionDay" 1;
BA_DEF_DEF_  "Manufacturer" "Ford";
BA_DEF_DEF_  "VersionMonth" 1;
BA_DEF_DEF_  "VersionYear" 2011;
BA_DEF_DEF_  "NmBaseAddress" 1280;
BA_DEF_DEF_  "NmMessageCount" 128;
BA_DEF_DEF_REL_ "SC_Verification" "No";
BA_ "BusType" "CAN FD";
BA_ "VersionYear" 2021;
BA_ "VersionMonth" 5;
BA_ "VersionDay" 21;
BA_ "CMDB_Version" "FNV3_v21.04 Draft vG";
BA_ "StarNetworkGwType" 12;
BA_ "VersionNumber" 4;
BA_ "DBName" "FD3_CAN";
BA_ "NmStationAddress" BU_ HCM 55;
BA_ "NmAsrNodeIdentifier" BU_ HCM 183;
BA_ "NodeWakeUpTime" BU_ HCM 100;
BA_ "OvtpEcuAddress" BU_ HCM 113;
BA_ "NmStationAddress" BU_ IPMA_ADAS 28;
BA_ "PowerType" BU_ IPMA_ADAS 1;
BA_ "NmAsrNodeIdentifier" BU_ IPMA_ADAS 156;
BA_ "NodeStartUpTime" BU_ IPMA_ADAS 300;
BA_ "NodeWakeUpTime" BU_ IPMA_ADAS 100;
BA_ "OvtpEcuAddress" BU_ IPMA_ADAS 33;
BA_ "NmStationAddress" BU_ PSCM 53;
BA_ "PowerType" BU_ PSCM 1;
BA_ "NmAsrNode" BU_ PSCM 1;
BA_ "NmAsrNodeIdentifier" BU_ PSCM 181;
BA_ "NodeWakeUpTime" BU_ PSCM 100;
BA_ "Terminator" BU_ PSCM 1;
BA_ "OvtpEcuAddress" BU_ PSCM 48;
BA_ "NmStationAddress" BU_ GWM 30;
BA_ "PowerType" BU_ GWM 2;
BA_ "NmAsrNode" BU_ GWM 1;
BA_ "NmAsrNodeIdentifier" BU_ GWM 158;
BA_ "NodeStartUpTime" BU_ GWM 100;
BA_ "NodeWakeUpTime" BU_ GWM 100;
BA_ "Terminator" BU_ GWM 1;
BA_ "OvtpEcuAddress" BU_ GWM 216;
BA_ "OvtpOperationMode" BU_ GWM 1;
BA_ "GatewayECU" BU_ GWM 1;
BA_ "NosPackage" BU_ GWM 4;
BA_ "NodeWakeUpTime" BU_ _delete 100;
BA_ "NmStationAddress" BU_ SCCM 51;
BA_ "PowerType" BU_ SCCM 2;
BA_ "NmAsrNode" BU_ SCCM 1;
BA_ "NmAsrNodeIdentifier" BU_ SCCM 179;
BA_ "NodeStartUpTime" BU_ SCCM 1000;
BA_ "NodeWakeUpTime" BU_ SCCM 100;
BA_ "Terminator" BU_ SCCM 1;
BA_ "OvtpEcuAddress" BU_ SCCM 68;
BA_ "PackageID" BU_ SCCM "08.06.00.01.11.00.90.02.00.00";
BA_ "LIN_Master" BU_ SCCM 1;
BA_ "NmStationAddress" BU_ PDM 5;
BA_ "PowerType" BU_ PDM 2;
BA_ "NmAsrNode" BU_ PDM 1;
BA_ "NmAsrNodeIdentifier" BU_ PDM 133;
BA_ "NodeStartUpTime" BU_ PDM 1000;
BA_ "NodeWakeUpTime" BU_ PDM 200;
BA_ "NmStationAddress" BU_ DDM 4;
BA_ "PowerType" BU_ DDM 2;
BA_ "NmAsrNode" BU_ DDM 1;
BA_ "NmAsrNodeIdentifier" BU_ DDM 132;
BA_ "NodeStartUpTime" BU_ DDM 1000;
BA_ "NodeWakeUpTime" BU_ DDM 200;
BA_ "NodeWakeUpTime" BU_ GENERIC 100;
BA_ "NodeWakeUpTime" BU_ TSTR 100;
BA_ "VFrameFormat" BO_ 1563 14;
BA_ "VFrameFormat" BO_ 1562 14;
BA_ "VFrameFormat" BO_ 1565 14;
BA_ "VFrameFormat" BO_ 1564 14;
BA_ "VFrameFormat" BO_ 1569 14;
BA_ "VFrameFormat" BO_ 1568 14;
BA_ "VFrameFormat" BO_ 1567 14;
BA_ "VFrameFormat" BO_ 1566 14;
BA_ "FrameRouting" BO_ 465 "FD1_CAN,0x1D1;";
BA_ "VFrameFormat" BO_ 465 14;
BA_ "TpTxIndex" BO_ 2609967320 462483672;
BA_ "GenMsgSendType" BO_ 2609967320 1;
BA_ "GenMsgDelayTime" BO_ 2609967320 0;
BA_ "NetworkInitialization" BO_ 2609967320 0;
BA_ "TpTxIndex" BO_ 2611015896 463532248;
BA_ "GenMsgSendType" BO_ 2611015896 1;
BA_ "GenMsgDelayTime" BO_ 2611015896 0;
BA_ "NetworkInitialization" BO_ 2611015896 0;
BA_ "OvtpPushApplication" BO_ 2612064472 1;
BA_ "TpTxIndex" BO_ 2612064472 464580824;
BA_ "GenMsgSendType" BO_ 2612064472 1;
BA_ "GenMsgDelayTime" BO_ 2612064472 0;
BA_ "NetworkInitialization" BO_ 2612064472 0;
BA_ "TpTxIndex" BO_ 2613113048 465629400;
BA_ "GenMsgSendType" BO_ 2613113048 1;
BA_ "GenMsgDelayTime" BO_ 2613113048 0;
BA_ "NetworkInitialization" BO_ 2613113048 0;
BA_ "TpTxIndex" BO_ 2609966296 462482648;
BA_ "GenMsgSendType" BO_ 2609966296 1;
BA_ "GenMsgDelayTime" BO_ 2609966296 0;
BA_ "NetworkInitialization" BO_ 2609966296 0;
BA_ "TpTxIndex" BO_ 2611014872 463531224;
BA_ "GenMsgSendType" BO_ 2611014872 1;
BA_ "GenMsgDelayTime" BO_ 2611014872 0;
BA_ "NetworkInitialization" BO_ 2611014872 0;
BA_ "OvtpPushApplication" BO_ 2612063448 1;
BA_ "TpTxIndex" BO_ 2612063448 464579800;
BA_ "GenMsgSendType" BO_ 2612063448 1;
BA_ "GenMsgDelayTime" BO_ 2612063448 0;
BA_ "NetworkInitialization" BO_ 2612063448 0;
BA_ "TpTxIndex" BO_ 2613112024 465628376;
BA_ "GenMsgSendType" BO_ 2613112024 1;
BA_ "GenMsgDelayTime" BO_ 2613112024 0;
BA_ "NetworkInitialization" BO_ 2613112024 0;
BA_ "TpTxIndex" BO_ 2609975512 462491864;
BA_ "GenMsgSendType" BO_ 2609975512 1;
BA_ "GenMsgDelayTime" BO_ 2609975512 0;
BA_ "NetworkInitialization" BO_ 2609975512 0;
BA_ "TpTxIndex" BO_ 2610126916 462491864;
BA_ "GenMsgSendType" BO_ 2610126916 1;
BA_ "GenMsgDelayTime" BO_ 2610126916 0;
BA_ "NetworkInitialization" BO_ 2610126916 0;
BA_ "OvtpPushApplication" BO_ 2612072664 1;
BA_ "TpTxIndex" BO_ 2612072664 464589016;
BA_ "GenMsgSendType" BO_ 2612072664 1;
BA_ "GenMsgDelayTime" BO_ 2612072664 0;
BA_ "NetworkInitialization" BO_ 2612072664 0;
BA_ "OvtpPushApplication" BO_ 2612224068 1;
BA_ "TpTxIndex" BO_ 2612224068 464589016;
BA_ "GenMsgSendType" BO_ 2612224068 1;
BA_ "GenMsgDelayTime" BO_ 2612224068 0;
BA_ "NetworkInitialization" BO_ 2612224068 0;
BA_ "TpTxIndex" BO_ 2613121240 465637592;
BA_ "GenMsgSendType" BO_ 2613121240 1;
BA_ "GenMsgDelayTime" BO_ 2613121240 0;
BA_ "NetworkInitialization" BO_ 2613121240 0;
BA_ "TpTxIndex" BO_ 2613272644 465637592;
BA_ "GenMsgSendType" BO_ 2613272644 1;
BA_ "GenMsgDelayTime" BO_ 2613272644 0;
BA_ "NetworkInitialization" BO_ 2613272644 0;
BA_ "FrameRouting" BO_ 787 "MS1_CAN,0x313;MS2_CAN,0x313";
BA_ "VFrameFormat" BO_ 787 14;
BA_ "FrameRouting" BO_ 781 "MS2_CAN,0x30D;";
BA_ "VFrameFormat" BO_ 781 14;
BA_ "FrameRouting" BO_ 931 "FD1_CAN,0x3A3;";
BA_ "SCP_DataId" BO_ 931 5027;
BA_ "SC_Message" BO_ 931 1;
BA_ "VFrameFormat" BO_ 931 14;
BA_ "FrameRouting" BO_ 757 "HS3_CAN,0x2F5;";
BA_ "VFrameFormat" BO_ 757 14;
BA_ "FrameRouting" BO_ 725 "HS3_CAN,0x2D5;";
BA_ "VFrameFormat" BO_ 725 14;
BA_ "FrameRouting" BO_ 932 "FD1_CAN,0x3A4;";
BA_ "SCP_DataId" BO_ 932 5028;
BA_ "SC_Message" BO_ 932 1;
BA_ "VFrameFormat" BO_ 932 14;
BA_ "FrameRouting" BO_ 993 "MS1_CAN,0x3E1;";
BA_ "VFrameFormat" BO_ 993 14;
BA_ "FrameRouting" BO_ 945 "FD1_CAN,0x3B1;";
BA_ "SCP_DataId" BO_ 945 5041;
BA_ "SC_Message" BO_ 945 1;
BA_ "VFrameFormat" BO_ 945 14;
BA_ "FrameRouting" BO_ 772 "MS1_CAN,0x304;";
BA_ "VFrameFormat" BO_ 772 14;
BA_ "GenMsgSendType" BO_ 2613219544 1;
BA_ "GenMsgDelayTime" BO_ 2613219544 0;
BA_ "NetworkInitialization" BO_ 2613219544 0;
BA_ "GenSigStartValue" SG_ 3221225472 CrnkInhbtActv_B_Stat 1;
BA_ "GenSigStartValue" SG_ 3221225472 VehVActlBrk_No_Corr 254;
BA_ "MetaData" SG_ 3221225472 BpedDiffLckTq_No_Cs 1;
BA_ "GenSigStartValue" SG_ 3221225472 CabnAmb_Te2_Actl 84;
BA_ "GenSigStartValue" SG_ 3221225472 RearDiffLck_D_RqDrv4 2;
BA_ "WakeupSignal" SG_ 3221225472 GlvBoxRleas_No_Actl 1;
BA_ "MetaData" SG_ 3221225472 PrkAidSwtch_No_Cnt 1;
BA_ "GenSigStartValue" SG_ 3221225472 EngExhMdeQuiet_D_Rq 2;
BA_ "MetaData" SG_ 3221225472 ApaSwtch_No_Cnt 1;
BA_ "GenSigStartValue" SG_ 3221225472 OffRdSwtch_D_RqMnu 2;
BA_ "GenSigStartValue" SG_ 465 Fleet2_D_ResLim 1;
BA_ "GenSigStartValue" SG_ 465 Fleet1_D_ResLim 1;
BA_ "GenSigStartValue" SG_ 465 StlnVeh2_D_ResLim 1;
BA_ "GenSigStartValue" SG_ 465 StlnVeh1_D_ResLim 1;
BA_ "GenSigSendType" SG_ 2609967320 OTAPhysGWM_ECGtoDCMH 3;
BA_ "ECGUsedTxSignal" SG_ 2609967320 OTAPhysGWM_ECGtoDCMH 1;
BA_ "U_P708_MY2023_Tx" SG_ 2609967320 OTAPhysGWM_ECGtoDCMH 1;
BA_ "U_P702_MY2024_Tx" SG_ 2609967320 OTAPhysGWM_ECGtoDCMH 1;
BA_ "GenSigSendType" SG_ 2611015896 PARSEDPhysGWM_ECGtoDCMH 3;
BA_ "ECGUsedTxSignal" SG_ 2611015896 PARSEDPhysGWM_ECGtoDCMH 1;
BA_ "U_P708_MY2023_Tx" SG_ 2611015896 PARSEDPhysGWM_ECGtoDCMH 1;
BA_ "U_P702_MY2024_Tx" SG_ 2611015896 PARSEDPhysGWM_ECGtoDCMH 1;
BA_ "GenSigSendType" SG_ 2612064472 PARSEDPushFcGWM_ECGtoDCMH 3;
BA_ "ECGUsedTxSignal" SG_ 2612064472 PARSEDPushFcGWM_ECGtoDCMH 1;
BA_ "U_P708_MY2023_Tx" SG_ 2612064472 PARSEDPushFcGWM_ECGtoDCMH 1;
BA_ "U_P702_MY2024_Tx" SG_ 2612064472 PARSEDPushFcGWM_ECGtoDCMH 1;
BA_ "GenSigSendType" SG_ 2613113048 SymKeyPhysGWM_ECGtoDCMH 3;
BA_ "ECGUsedTxSignal" SG_ 2613113048 SymKeyPhysGWM_ECGtoDCMH 1;
BA_ "U_P708_MY2023_Tx" SG_ 2613113048 SymKeyPhysGWM_ECGtoDCMH 1;
BA_ "U_P702_MY2024_Tx" SG_ 2613113048 SymKeyPhysGWM_ECGtoDCMH 1;
BA_ "GenSigSendType" SG_ 2609966296 OTAPhysGWM_ECGtoDCMG 3;
BA_ "ECGUsedTxSignal" SG_ 2609966296 OTAPhysGWM_ECGtoDCMG 1;
BA_ "U_P708_MY2023_Tx" SG_ 2609966296 OTAPhysGWM_ECGtoDCMG 1;
BA_ "U_P702_MY2024_Tx" SG_ 2609966296 OTAPhysGWM_ECGtoDCMG 1;
BA_ "GenSigSendType" SG_ 2611014872 PARSEDPhysGWM_ECGtoDCMG 3;
BA_ "ECGUsedTxSignal" SG_ 2611014872 PARSEDPhysGWM_ECGtoDCMG 1;
BA_ "U_P708_MY2023_Tx" SG_ 2611014872 PARSEDPhysGWM_ECGtoDCMG 1;
BA_ "U_P702_MY2024_Tx" SG_ 2611014872 PARSEDPhysGWM_ECGtoDCMG 1;
BA_ "GenSigSendType" SG_ 2612063448 PARSEDPushFcGWM_ECGtoDCMG 3;
BA_ "ECGUsedTxSignal" SG_ 2612063448 PARSEDPushFcGWM_ECGtoDCMG 1;
BA_ "U_P708_MY2023_Tx" SG_ 2612063448 PARSEDPushFcGWM_ECGtoDCMG 1;
BA_ "U_P702_MY2024_Tx" SG_ 2612063448 PARSEDPushFcGWM_ECGtoDCMG 1;
BA_ "GenSigSendType" SG_ 2613112024 SymKeyPhysGWM_ECGtoDCMG 3;
BA_ "ECGUsedTxSignal" SG_ 2613112024 SymKeyPhysGWM_ECGtoDCMG 1;
BA_ "U_P708_MY2023_Tx" SG_ 2613112024 SymKeyPhysGWM_ECGtoDCMG 1;
BA_ "U_P702_MY2024_Tx" SG_ 2613112024 SymKeyPhysGWM_ECGtoDCMG 1;
BA_ "GenSigSendType" SG_ 2609975512 OTAPhysGWM_ECGtoSCCM 3;
BA_ "U_P708_MY2023_Rx" SG_ 2609975512 OTAPhysGWM_ECGtoSCCM 1;
BA_ "ECGUsedTxSignal" SG_ 2609975512 OTAPhysGWM_ECGtoSCCM 1;
BA_ "U_P708_MY2023_Tx" SG_ 2609975512 OTAPhysGWM_ECGtoSCCM 1;
BA_ "U_P702_MY2024_Tx" SG_ 2609975512 OTAPhysGWM_ECGtoSCCM 1;
BA_ "GenSigSendType" SG_ 2610126916 OTAPhysSCCMtoGWM_ECG 3;
BA_ "ECGUsedRxSignal" SG_ 2610126916 OTAPhysSCCMtoGWM_ECG 1;
BA_ "U_P708_MY2023_Rx" SG_ 2610126916 OTAPhysSCCMtoGWM_ECG 1;
BA_ "U_P702_MY2024_Rx" SG_ 2610126916 OTAPhysSCCMtoGWM_ECG 1;
BA_ "U_P708_MY2023_Tx" SG_ 2610126916 OTAPhysSCCMtoGWM_ECG 1;
BA_ "U_P702_MY2024_Tx" SG_ 2610126916 OTAPhysSCCMtoGWM_ECG 1;
BA_ "GenSigSendType" SG_ 2612072664 PARSEDPushFcGWM_ECGtoSCCM 3;
BA_ "U_P708_MY2023_Rx" SG_ 2612072664 PARSEDPushFcGWM_ECGtoSCCM 1;
BA_ "ECGUsedTxSignal" SG_ 2612072664 PARSEDPushFcGWM_ECGtoSCCM 1;
BA_ "U_P708_MY2023_Tx" SG_ 2612072664 PARSEDPushFcGWM_ECGtoSCCM 1;
BA_ "U_P702_MY2024_Tx" SG_ 2612072664 PARSEDPushFcGWM_ECGtoSCCM 1;
BA_ "GenSigSendType" SG_ 2612224068 PARSEDPushSCCMtoGWM_ECG 3;
BA_ "ECGUsedRxSignal" SG_ 2612224068 PARSEDPushSCCMtoGWM_ECG 1;
BA_ "U_P708_MY2023_Rx" SG_ 2612224068 PARSEDPushSCCMtoGWM_ECG 1;
BA_ "U_P702_MY2024_Rx" SG_ 2612224068 PARSEDPushSCCMtoGWM_ECG 1;
BA_ "U_P708_MY2023_Tx" SG_ 2612224068 PARSEDPushSCCMtoGWM_ECG 1;
BA_ "U_P702_MY2024_Tx" SG_ 2612224068 PARSEDPushSCCMtoGWM_ECG 1;
BA_ "GenSigSendType" SG_ 2613121240 SymKeyPhysGWM_ECGtoSCCM 3;
BA_ "U_P708_MY2023_Rx" SG_ 2613121240 SymKeyPhysGWM_ECGtoSCCM 1;
BA_ "ECGUsedTxSignal" SG_ 2613121240 SymKeyPhysGWM_ECGtoSCCM 1;
BA_ "U_P708_MY2023_Tx" SG_ 2613121240 SymKeyPhysGWM_ECGtoSCCM 1;
BA_ "U_P702_MY2024_Tx" SG_ 2613121240 SymKeyPhysGWM_ECGtoSCCM 1;
BA_ "GenSigSendType" SG_ 2613272644 SymKeyPhysSCCMtoGWM_ECG 3;
BA_ "ECGUsedRxSignal" SG_ 2613272644 SymKeyPhysSCCMtoGWM_ECG 1;
BA_ "U_P708_MY2023_Rx" SG_ 2613272644 SymKeyPhysSCCMtoGWM_ECG 1;
BA_ "U_P702_MY2024_Rx" SG_ 2613272644 SymKeyPhysSCCMtoGWM_ECG 1;
BA_ "U_P708_MY2023_Tx" SG_ 2613272644 SymKeyPhysSCCMtoGWM_ECG 1;
BA_ "U_P702_MY2024_Tx" SG_ 2613272644 SymKeyPhysSCCMtoGWM_ECG 1;
BA_ "U_P708_MY2023_Rx" SG_ 787 DrTgatePos_Pc_Actl 1;
BA_ "U_P702_MY2024_Rx" SG_ 787 DrTgatePos_Pc_Actl 1;
BA_ "WakeupSignal" SG_ 787 DrLckCnt_No_ActlTgate 1;
BA_ "WakeupSignal" SG_ 787 DrTgateChime2_D_Rq 1;
BA_ "WakeupSignal" SG_ 787 DrTGate_D_Rq 1;
BA_ "WakeupSignal" SG_ 787 PwLftgtIntSw_B_Stat 1;
BA_ "U_P708_MY2023_Rx" SG_ 781 TrlrTireSys_D_Stat 1;
BA_ "U_P702_MY2024_Rx" SG_ 781 TrlrTireSys_D_Stat 1;
BA_ "U_P708_MY2023_Rx" SG_ 931 VehOnSrc_D_Stat 1;
BA_ "U_P702_MY2024_Rx" SG_ 931 VehOnSrc_D_Stat 1;
BA_ "MetaData" SG_ 931 StrtrMtrCtlDStat_No_Cs 1;
BA_ "MetaData" SG_ 931 CrnkInhbt_No_Cs 1;
BA_ "MetaData" SG_ 931 CrnkInhbt_No_Cnt 1;
BA_ "GenSigStartValue" SG_ 931 CrnkInhbt_B_Stat 1;
BA_ "U_P708_MY2023_Rx" SG_ 757 ACU_RadioSeekMode2_St 1;
BA_ "U_P702_MY2024_Rx" SG_ 757 ACU_RadioSeekMode2_St 1;
BA_ "U_P708_MY2023_Rx" SG_ 757 ACU_CurrTUBand_St 1;
BA_ "U_P702_MY2024_Rx" SG_ 757 ACU_CurrTUBand_St 1;
BA_ "U_P708_MY2023_Rx" SG_ 725 ACU_CurrentFreq_St 1;
BA_ "U_P702_MY2024_Rx" SG_ 725 ACU_CurrentFreq_St 1;
BA_ "U_P708_MY2023_Rx" SG_ 932 VehStrtInhbt_D_Stat 1;
BA_ "U_P702_MY2024_Rx" SG_ 932 VehStrtInhbt_D_Stat 1;
BA_ "U_P708_MY2023_Rx" SG_ 932 VehOnSrc2_D_Stat 1;
BA_ "U_P702_MY2024_Rx" SG_ 932 VehOnSrc2_D_Stat 1;
BA_ "MetaData" SG_ 932 CanMsg3A4_No_Crc 1;
BA_ "MetaData" SG_ 932 CanMsg3A4_No_Cnt 1;
BA_ "WakeupSignal" SG_ 932 ChildLck_D_Dsply 1;
BA_ "GenSigStartValue" SG_ 932 ChildLck_D_Dsply 1;
BA_ "U_P708_MY2023_Rx" SG_ 932 ChildLck_D_Dsply 1;
BA_ "U_P702_MY2024_Rx" SG_ 932 ChildLck_D_Dsply 1;
BA_ "WakeupSignal" SG_ 993 MemSwtch_D_RqRecall 1;
BA_ "WakeupSignal" SG_ 993 MemSwtch_D_RqAssoc 1;
BA_ "GenSigStartValue" SG_ 993 PersIndexDsm_D_Actl 4;
BA_ "WakeupSignal" SG_ 945 AdasRelay_B_Stat2 1;
BA_ "WakeupSignal" SG_ 945 PrkLckCtlMsgTxt_D2_Rq 1;
BA_ "WakeupSignal" SG_ 945 PwLoApim_T_Actl 1;
BA_ "U_P708_MY2023_Rx" SG_ 945 KeyOffMde_D_Actl 1;
BA_ "U_P702_MY2024_Rx" SG_ 945 KeyOffMde_D_Actl 1;
BA_ "WakeupSignal" SG_ 945 KeyPadCodeDgt6_D_Dsply 1;
BA_ "WakeupSignal" SG_ 945 KeyPadCodeDgt5_D_Dsply 1;
BA_ "WakeupSignal" SG_ 945 KeyPadCodeDgt4_D_Dsply 1;
BA_ "WakeupSignal" SG_ 945 KeyPadCodeDgt3_D_Dsply 1;
BA_ "WakeupSignal" SG_ 945 KeyPadCodeDgt2_D_Dsply 1;
BA_ "WakeupSignal" SG_ 945 KeyPadCodeDgt1_D_Dsply 1;
BA_ "WakeupSignal" SG_ 772 SeatScrnDrvOn_B_Rq 1;
BA_ "WakeupSignal" SG_ 772 Memory_Feedback_Rqst 1;
BA_ "WakeupSignal" SG_ 772 Easy_Entry_Rqst 1;
BA_ "WakeupSignal" SG_ 772 Memory_Cmd 1;
BA_ "U_P708_MY2023_Rx" SG_ 772 Memory_Cmd 1;
BA_ "U_P702_MY2024_Rx" SG_ 772 Memory_Cmd 1;
BA_ "WakeupSignal" SG_ 772 Cancel_Auto_Movement 1;
BA_ "U_P708_MY2023_Rx" SG_ 772 Cancel_Auto_Movement 1;
BA_ "U_P702_MY2024_Rx" SG_ 772 Cancel_Auto_Movement 1;
BA_ "GenSigSendType" SG_ 2613219544 SymKeyPhysGWM_ECGtoPDM 3;
BA_ "U_P708_MY2023_Rx" SG_ 2613219544 SymKeyPhysGWM_ECGtoPDM 1;
BA_ "U_P702_MY2024_Rx" SG_ 2613219544 SymKeyPhysGWM_ECGtoPDM 1;
BA_ "ECGUsedTxSignal" SG_ 2613219544 SymKeyPhysGWM_ECGtoPDM 1;
BA_ "U_P708_MY2023_Tx" SG_ 2613219544 SymKeyPhysGWM_ECGtoPDM 1;
BA_ "U_CDX74X_MY2024_Tx" SG_ 2613219544 SymKeyPhysGWM_ECGtoPDM 1;
BA_ "U_P702_MY2024_Tx" SG_ 2613219544 SymKeyPhysGWM_ECGtoPDM 1;
BA_REL_ "SC_Verification" BU_SG_REL_ DDM SG_ 932 VehOnSrc2_D_Stat 1;
BA_REL_ "SC_Verification" BU_SG_REL_ PDM SG_ 932 VehOnSrc2_D_Stat 1;
BA_REL_ "SC_Verification" BU_SG_REL_ DDM SG_ 932 ChildLck_D_Dsply 1;
VAL_ 3221225472 TrailOnePdlMde_D_Ind 7 "NotUsed_4" 6 "NotUsed_3" 5 "NotUsed_2" 4 "NotUsed_1" 3 "Standby" 2 "Active" 1 "Fault" 0 "Off" ;
VAL_ 3221225472 RaceTrakMde_D_Stat 3 "NotUsed" 2 "Available" 1 "NotAvailable" 0 "Null" ;
VAL_ 3221225472 SuspClkSync_No_Rq 255 "Faulty" 254 "NoDataExists" ;
VAL_ 3221225472 HsaTrnAout_Tq_Rq 65535 "Fault" 65534 "Unknown" ;
VAL_ 3221225472 HsaStat_D_Dsply 7 "NotUsed3" 6 "NotUsed2" 5 "NotUsed1" 4 "NotAvailable" 3 "SlowReleaseWithChime" 2 "SlowReleaseWithoutChime" 1 "Active" 0 "Inactive" ;
VAL_ 3221225472 CrnkInhbtActv_B_Stat 1 "Yes" 0 "No" ;
VAL_ 3221225472 CrnkInhbtHlthRate_B_Rq 1 "Slow" 0 "Fast" ;
VAL_ 3221225472 VehVActlBrk_No_Corr 255 "Faulty" 254 "NoDataExists" ;
VAL_ 3221225472 SelDrvMdeMsgTxt2_D_Rq 15 "Message15" 14 "Message14" 13 "Message13" 12 "Message12" 11 "Message11" 10 "Message10" 9 "Message9" 8 "Message8" 7 "Message7" 6 "Message6" 5 "Message5" 4 "Message4" 3 "Message3" 2 "Message2" 1 "Message1" 0 "NoMessage" ;
VAL_ 3221225472 RearDiffLckLamp_D_Rq2 3 "Triggered" 2 "Flash" 1 "On" 0 "Off" ;
VAL_ 3221225472 SeatRelxPosDact_B_Stat 1 "Success" 0 "Fail" ;
VAL_ 3221225472 SeatRelxPosActv_B_Stat 1 "Success" 0 "Fail" ;
VAL_ 3221225472 SeatRelxPosSet_B_Stat 1 "Success" 0 "Fail" ;
VAL_ 3221225472 StopStrtImccSel_B_Rq 1 "On" 0 "Off" ;
VAL_ 3221225472 StopStrtImccTxt_D_Stat 7 "NotUsed_3" 6 "NotUsed_2" 5 "NotUsed_1" 4 "ClosedTimeout" 3 "ClosedYes" 2 "ClosedNo" 1 "ActiveOnDsply" 0 "NotActive" ;
VAL_ 3221225472 StopStrtImccSel_B_Falt 1 "Yes" 0 "No" ;
VAL_ 3221225472 LnchCtl_D_Rq2 3 "NotUsed2" 2 "NotUsed1" 1 "LC_On" 0 "LC_Off" ;
VAL_ 3221225472 DrvSlipCtlMde_B_Rq6 1 "Pressed" 0 "Not_Pressed" ;
VAL_ 3221225472 TrakApplActvSet_D_Rq 15 "NotUsed_12" 14 "NotUsed_11" 13 "NotUsed_10" 12 "NotUsed_9" 11 "NotUsed_8" 10 "NotUsed_7" 9 "NotUsed_6" 8 "NotUsed_5" 7 "NotUsed_4" 6 "NotUsed_3" 5 "NotUsed_2" 4 "NotUsed_1" 3 "AccTimer_Start_Track" 2 "AccTimer_Start_Drag" 1 "AccTimer_Start_Automatic" 0 "Null" ;
VAL_ 3221225472 TrakAppl_D_RqMnu 31 "NotUsed_15" 30 "NotUsed_14" 29 "NotUsed_13" 28 "NotUsed_12" 27 "NotUsed_11" 26 "NotUsed_10" 25 "NotUsed_9" 24 "NotUsed_8" 23 "NotUsed_7" 22 "NotUsed_6" 21 "NotUsed_5" 20 "NotUsed_4" 19 "NotUsed_3" 18 "NotUsed_2" 17 "NotUsed_1" 16 "Activate_LineLock" 15 "Activate_LapTimer" 14 "Activate_400m" 13 "Activate_200m" 12 "Activate_1/4mile" 11 "Activate_1/8mile" 10 "Activate_0-200kph" 9 "Activate_0-100kph" 8 "Activate_0-50kph" 7 "Activate_0-100mph" 6 "Activate_0-60mph" 5 "Activate_0-30mph" 4 "Activate_200-0kph" 3 "Activate_100-0kph" 2 "Activate_100-0mph" 1 "Activate_60-0mph" 0 "Deactivate_TrackApp" ;
VAL_ 3221225472 VgfSet_D_Stat 3 "NotUsed" 2 "On" 1 "Off" 0 "Null" ;
VAL_ 3221225472 PtDrvMde_D_Rq 15 "Faulty" 14 "NotUsed11" 13 "NotUsed10" 12 "NotUsed9" 11 "NotUsed8" 10 "NotUsed7" 9 "NotUsed6" 8 "Track" 7 "Drag" 6 "Rock" 5 "Baja" 4 "Sand" 3 "TowHaulGradeAssist" 2 "SnowWet" 1 "Sport" 0 "Normal" ;
VAL_ 3221225472 DrvPerfMde_D_Rq 3 "Sport" 2 "Normal" 1 "NotUsed" 0 "NoModeSelected" ;
VAL_ 3221225472 StopStrtDrvMde_D_RqMnu 3 "NotUsed2" 2 "NotUsed1" 1 "StopStart_Deselected" 0 "StopStart_Selected" ;
VAL_ 3221225472 FrostWarn_D_Stat 3 "NotUsed" 2 "On_Amber" 1 "On_Red" 0 "Off" ;
VAL_ 3221225472 PrkLckCtlEnbl_D_RqIpc 3 "Rq_Towing" 2 "Rq_Enable" 1 "Rq_Disable" 0 "Null" ;
VAL_ 3221225472 Fda_B_Stat 1 "On" 0 "Off" ;
VAL_ 3221225472 RearDiffLck_D_RqDrv4 3 "Faulty" 2 "NoRequest" 1 "On" 0 "Off" ;
VAL_ 3221225472 CamraRearBttn_D_Stat 1 "Pressed" 0 "Not_Pressed" ;
VAL_ 3221225472 TrailCtlSwtch_B_Stat 1 "Pressed" 0 "Not_Pressed" ;
VAL_ 3221225472 LpdbDfrstFrOn_B_Rq 1 "On" 0 "Off" ;
VAL_ 3221225472 LpdbDfrstFlOn_B_Rq 1 "On" 0 "Off" ;
VAL_ 3221225472 LpdbAuxBlwr_B_Rq 1 "On" 0 "Off" ;
VAL_ 3221225472 PrkAidSwtch_D_RqDrv 1 "Pressed" 0 "Not_Pressed" ;
VAL_ 3221225472 DrvSlipCtlMde_B_Rq 1 "Pressed" 0 "Not_Pressed" ;
VAL_ 3221225472 CamraFrntBttn_D_Stat 1 "Pressed" 0 "Not_Pressed" ;
VAL_ 3221225472 AutoTowAllw_D_RqMnu 3 "TowHaulCommandedOn" 2 "AutoTowHaulEnabled" 1 "AutoTowHaulDisabled" 0 "NoSelection" ;
VAL_ 3221225472 EngExhMdeQuiet_D_Rq 3 "Faulty" 2 "QuietExhaust" 1 "LoudExhaust" 0 "Null" ;
VAL_ 3221225472 Mc_VehDayNightUsrSel_St 2 "Night" 1 "Day" 0 "Invalid" ;
VAL_ 3221225472 Mc_VehThemeUsrSel_St 2 "Theme_2" 1 "Theme_1" 0 "Invalid" ;
VAL_ 3221225472 EngExhMdeQuiet_D2_Rq 7 "NotUsed_3" 6 "NotUsed_2" 5 "NotUsed_1" 4 "Track" 3 "Sport" 2 "Normal" 1 "Stealth" 0 "Null" ;
VAL_ 3221225472 BrkLineLck_D_Rq 3 "Off" 2 "Engage" 1 "Initiate" 0 "NoRequest" ;
VAL_ 3221225472 ApaSwtch_D_RqDrv 3 "NotUsed2" 2 "NotUsed1" 1 "Pressed" 0 "Not_Pressed" ;
VAL_ 3221225472 HvacBlwrRear_D_Stat 31 "Not_Used" 20 "Full_On" 19 "95_Percent" 18 "90_Percent" 17 "85_Percent" 16 "80_Percent" 15 "75_Percent" 14 "70_Percent" 13 "65_Percent" 12 "60_Percent" 11 "55_Percent" 10 "50_Percent" 9 "45_Percent" 8 "40_Percent" 7 "35_Percent" 6 "30_Percent" 5 "25_Percent" 4 "20_Percent" 3 "15_Percent" 2 "10_Percent" 1 "5_Percent" 0 "Off" ;
VAL_ 3221225472 BattTracLoThres_D_Rq2 7 "NotUsed" 6 "Thres80km_50mi" 5 "Thres50km_31mi" 4 "Thres30km_18mi" 3 "Thres50mi_80km" 2 "Thres30mi_48km" 1 "Thres20mi_32km" 0 "Null" ;
VAL_ 3221225472 WwaActv_B_Stat 1 "Active" 0 "Inactive" ;
VAL_ 3221225472 OffRdSwtch_D_RqMnu 3 "Faulty" 2 "NoRequest" 1 "On" 0 "Off" ;
VAL_ 3221225472 SelDrvMdeSwtchOk_D_Stat 3 "Faulty" 2 "Pressed" 1 "NotPressed" 0 "Null" ;
VAL_ 3221225472 AutoHoldSwtch_D_Stat2 3 "Faulty" 2 "NotUsed" 1 "Pressed" 0 "Not_Pressed" ;
VAL_ 3221225472 PrkAidSwtch_D_RqDrv3 1 "Pressed" 0 "Not_Pressed" ;
VAL_ 3221225472 ApaSwtch_D_RqDrv3 3 "NotUsed2" 2 "NotUsed1" 1 "Pressed" 0 "Not_Pressed" ;
VAL_ 3221225472 StopStrtDrvMde_B_RqBtn2 1 "Pressed" 0 "Not_Pressed" ;
VAL_ 465 NnMtvMdeLim_B_Stat 1 "Yes" 0 "Null" ;
VAL_ 465 HwyVLim_B_Stat 1 "Yes" 0 "Null" ;
VAL_ 465 CtyVLim_B_Stat 1 "Yes" 0 "Null" ;
VAL_ 465 SecMdeLim_B_Stat 1 "Yes" 0 "Null" ;
VAL_ 465 PrkLotVLim_B_Stat 1 "Yes" 0 "Null" ;
VAL_ 465 PwPckInhbtLim_B_Stat 1 "Yes" 0 "Null" ;
VAL_ 465 PrplLim_B_Stat 1 "Yes" 0 "Null" ;
VAL_ 465 VflCstmLim_B_Stat 1 "Yes" 0 "Null" ;
VAL_ 465 VflCstmVLim_B_Stat 1 "Yes" 0 "Null" ;
VAL_ 465 Fleet2_D_StatLim 7 "NotUsed_3" 6 "NotUsed_2" 5 "NotUsed_1" 4 "Accepted" 3 "Pending" 2 "Denied" 1 "Possible" 0 "NotPossible" ;
VAL_ 465 Fleet1_D_StatLim 7 "NotUsed_3" 6 "NotUsed_2" 5 "NotUsed_1" 4 "Accepted" 3 "Pending" 2 "Denied" 1 "Possible" 0 "NotPossible" ;
VAL_ 465 Fleet2_D_ResLim 31 "NotUsed_14" 30 "NotUsed_13" 29 "NotUsed_12" 28 "NotUsed_11" 27 "NotUsed_10" 26 "NotUsed_9" 25 "NotUsed_8" 24 "NotUsed_7" 23 "NotUsed_6" 22 "NotUsed_5" 21 "NotUsed_4" 20 "NotUsed_3" 19 "NotUsed_2" 18 "NotUsed_1" 17 "ReversePropulsionOnly" 16 "ForwardPropulsionOnly" 15 "SaveEv" 14 "EvOnly" 13 "TqLimitMed_ReducedPower" 12 "TqLimitHigh_Truncation" 11 "VslCustom" 10 "VslHigh_HighwaySpeeds" 9 "VslMed_UrbanSpeeds" 8 "VslLow_ParkingLowSpeed" 7 "LimitedPropulsion" 6 "NonMotiveMode" 5 "SecureMode" 4 "PowerPackBlock_Inhibit" 3 "Custom2" 2 "Custom1" 1 "NoLimitRequested" 0 "Initializing" ;
VAL_ 465 Fleet1_D_ResLim 31 "NotUsed_14" 30 "NotUsed_13" 29 "NotUsed_12" 28 "NotUsed_11" 27 "NotUsed_10" 26 "NotUsed_9" 25 "NotUsed_8" 24 "NotUsed_7" 23 "NotUsed_6" 22 "NotUsed_5" 21 "NotUsed_4" 20 "NotUsed_3" 19 "NotUsed_2" 18 "NotUsed_1" 17 "ReversePropulsionOnly" 16 "ForwardPropulsionOnly" 15 "SaveEv" 14 "EvOnly" 13 "TqLimitMed_ReducedPower" 12 "TqLimitHigh_Truncation" 11 "VslCustom" 10 "VslHigh_HighwaySpeeds" 9 "VslMed_UrbanSpeeds" 8 "VslLow_ParkingLowSpeed" 7 "LimitedPropulsion" 6 "NonMotiveMode" 5 "SecureMode" 4 "PowerPackBlock_Inhibit" 3 "Custom2" 2 "Custom1" 1 "NoLimitRequested" 0 "Initializing" ;
VAL_ 465 StlnVeh2_D_StatLim 7 "NotUsed_3" 6 "NotUsed_2" 5 "NotUsed_1" 4 "Accepted" 3 "Pending" 2 "Denied" 1 "Possible" 0 "NotPossible" ;
VAL_ 465 StlnVeh1_D_StatLim 7 "NotUsed_3" 6 "NotUsed_2" 5 "NotUsed_1" 4 "Accepted" 3 "Pending" 2 "Denied" 1 "Possible" 0 "NotPossible" ;
VAL_ 465 StlnVeh2_D_ResLim 31 "NotUsed_14" 30 "NotUsed_13" 29 "NotUsed_12" 28 "NotUsed_11" 27 "NotUsed_10" 26 "NotUsed_9" 25 "NotUsed_8" 24 "NotUsed_7" 23 "NotUsed_6" 22 "NotUsed_5" 21 "NotUsed_4" 20 "NotUsed_3" 19 "NotUsed_2" 18 "NotUsed_1" 17 "ReversePropulsionOnly" 16 "ForwardPropulsionOnly" 15 "SaveEv" 14 "EvOnly" 13 "TqLimitMed_ReducedPower" 12 "TqLimitHigh_Truncation" 11 "VslCustom" 10 "VslHigh_HighwaySpeeds" 9 "VslMed_UrbanSpeeds" 8 "VslLow_ParkingLowSpeed" 7 "LimitedPropulsion" 6 "NonMotiveMode" 5 "SecureMode" 4 "PowerPackBlock_Inhibit" 3 "Custom2" 2 "Custom1" 1 "NoLimitRequested" 0 "Initializing" ;
VAL_ 465 StlnVeh1_D_ResLim 31 "NotUsed_14" 30 "NotUsed_13" 29 "NotUsed_12" 28 "NotUsed_11" 27 "NotUsed_10" 26 "NotUsed_9" 25 "NotUsed_8" 24 "NotUsed_7" 23 "NotUsed_6" 22 "NotUsed_5" 21 "NotUsed_4" 20 "NotUsed_3" 19 "NotUsed_2" 18 "NotUsed_1" 17 "ReversePropulsionOnly" 16 "ForwardPropulsionOnly" 15 "SaveEv" 14 "EvOnly" 13 "TqLimitMed_ReducedPower" 12 "TqLimitHigh_Truncation" 11 "VslCustom" 10 "VslHigh_HighwaySpeeds" 9 "VslMed_UrbanSpeeds" 8 "VslLow_ParkingLowSpeed" 7 "LimitedPropulsion" 6 "NonMotiveMode" 5 "SecureMode" 4 "PowerPackBlock_Inhibit" 3 "Custom2" 2 "Custom1" 1 "NoLimitRequested" 0 "Initializing" ;
VAL_ 787 DrTgatePos_Pc_Actl 127 "Faulty" 126 "NoDataExists" ;
VAL_ 787 PwTgateInhbtMsgTxt_B_Rq 1 "DisplayMessage" 0 "NoMessage" ;
VAL_ 787 DrTgateChime2_D_Rq 7 "NotUsed3" 6 "NotUsed2" 5 "NotUsed1" 4 "Long_Repeated" 3 "Fast" 2 "Short" 1 "Long" 0 "Off" ;
VAL_ 787 DrTGate_D_Rq 3 "NotUsed" 2 "Closing" 1 "Opening" 0 "Not_Moving" ;
VAL_ 787 PwLftgtIntSw_B_Stat 1 "Pressed" 0 "Null" ;
VAL_ 787 Power_Liftgate_Mode_Stt 2 "Unused" 3 "Not_Supported" 1 "Enabled" 0 "Disabled" ;
VAL_ 787 PwTgateMsgTxt_B_Rq 1 "DisplayMessage" 0 "NoMessage" ;
VAL_ 787 PwTgateLamp_B_Rq 1 "On" 0 "Off" ;
VAL_ 787 PwTgateStepMsgTxt_B_Rq 1 "DisplayMessage" 0 "NoMessage" ;
VAL_ 781 TrlrTireDual_D_Stat 15 "NotUsed_11" 14 "NotUsed_10" 13 "NotUsed_9" 12 "NotUsed_8" 11 "NotUsed_7" 10 "NotUsed_6" 9 "NotUsed_5" 8 "NotUsed_4" 7 "NotUsed_3" 6 "NotUsed_2" 5 "NotUsed_1" 4 "NotSupported" 3 "Invalid" 2 "InnerTire" 1 "OuterTire" 0 "SystemUnknown" ;
VAL_ 781 TrlrTireSys_D_Stat 15 "NotUsed" 14 "TiresNotTrained" 13 "TrainingComplete" 12 "TrainLMTire" 11 "TrainLRTire" 10 "TrainRMTire" 9 "TrainRRTire" 8 "TrainRFTire" 7 "TrainLFTire" 6 "RequestPressureThresh" 5 "RequestTireCount" 4 "SystemActive" 3 "TireLow" 2 "SensorFault" 1 "System Fault" 0 "SystemUnknown" ;
VAL_ 781 TrlrTireCnt_D_Stat 7 "Faulty" 6 "TwelveTire" 5 "EightTire" 4 "FourTireOneAxle" 3 "SixTire" 2 "FourTire" 1 "TwoTire" 0 "Unconfigured" ;
VAL_ 781 Chirp_D_RqTrlr 3 "NotUsed" 2 "Chirp_2" 1 "Chirp_1" 0 "NoRequest" ;
VAL_ 931 VehOnSrc_D_Stat 15 "NotUsed_11" 14 "NotUsed_10" 13 "NotUsed_9" 12 "NotUsed_8" 11 "NotUsed_7" 10 "NotUsed_6" 9 "EsclRssd" 8 "AutonomousVehicle" 7 "SecureIdle" 6 "FleetVehicleInhibit" 5 "StolenVehicleInhibit" 4 "OverTheAir" 3 "RemoteParkAssist" 2 "RemoteStart" 1 "Manual" 0 "Off" ;
VAL_ 931 EngStrtActv_B_Stat 1 "Active" 0 "Inactive" ;
VAL_ 931 EngStrt_B_Rq 1 "Request" 0 "NoRequest" ;
VAL_ 931 DrvInCtl_B_Stat 1 "Yes" 0 "No" ;
VAL_ 931 PtWakeReas_D_Stat 15 "NotUsed_9" 14 "NotUsed_8" 13 "NotUsed_7" 12 "NotUsed_6" 11 "NotUsed_5" 10 "NotUsed_4" 9 "NotUsed_3" 8 "NotUsed_2" 7 "NotUsed_1" 6 "ElapsedTime" 5 "ThirdPartyWakeup" 4 "DoorAjar" 3 "EarlyWake" 2 "NonMotiveStart" 1 "MotiveStart" 0 "Null" ;
VAL_ 931 CrnkInhbt_B_Stat 1 "Inhibit" 0 "NoInhibit" ;
VAL_ 931 IgnPreOffActv_B_Stat 1 "Active" 0 "Inactive" ;
VAL_ 757 SpkrStdRight_D_Stat 3 "Faulty" 2 "Normal" 1 "NotPresent" 0 "Null" ;
VAL_ 757 SpkrStdLeft_D_Stat 3 "Faulty" 2 "Normal" 1 "NotPresent" 0 "Null" ;
VAL_ 757 SpkrStdCntr_D_Stat 3 "Faulty" 2 "Normal" 1 "NotPresent" 0 "Null" ;
VAL_ 757 SDARS_ChipControl_St 7 "NotUsed_2" 6 "NotUsed_1" 5 "Ready" 4 "ResetInProgress" 3 "PowerDownInProgress" 2 "PowerUpInProgress" 1 "Off" 0 "Null" ;
VAL_ 757 ACU_AutoStoreResult_St 2 "No_Station_Found" 1 "Inactive" 0 "Invalid" ;
VAL_ 757 ACU_DirectTune_St 2 "Valid_Station" 1 "Invalid_Station" 0 "Invalid" ;
VAL_ 757 ACU_RadioSeekMode2_St 16 "ContAutoDown" 15 "ContAutoUp" 14 "PISeek" 13 "TpSeek" 12 "Autostore" 11 "PtySeekDown" 10 "PtySeekUp" 9 "ScanDown" 8 "ScanUp" 7 "ContManualDown" 6 "ContManualUp" 5 "ManSingleStepDown" 4 "ManSingleStepUp" 3 "AutoDown" 2 "AutoUp" 1 "SeekOff" 0 "Invalid" ;
VAL_ 757 ACU_CurrTUBand_St 10 "SAT2" 9 "SAT1" 8 "DAB2" 7 "DAB1" 6 "Fm3" 5 "AmAst" 4 "Am" 3 "FmAst" 2 "Fm2" 1 "Fm1" 0 "Invalid" 13 "reserved1" 15 "reserved_last" 12 "DAB3" 11 "SAT3" ;
VAL_ 725 InfotainmentAudio_St 3 "NotUsed" 2 "ErrorState_NoAudio" 1 "NormalOperation" 0 "Null" ;
VAL_ 725 ACU_CompLogic_St 0 "Invalid" 1 "Off" 2 "On" ;
VAL_ 725 ACU_RadioError_St 0 "Invalid" 1 "NoError" 2 "PiNotFound" 3 "PtyNotFound" ;
VAL_ 725 ACU_HardwareError_St 0 "Invalid" 1 "NoError" 2 "EepromReadError" 3 "KeycodeLocked" 4 "KeycodeLockedForever" 5 "CommunicationError" 6 "OverTemperature" 7 "FocusError" ;
VAL_ 725 ACU_CurrentRadioBand_St 6 "Fm3" 0 "Invalid" 1 "Fm1" 2 "Fm2" 3 "FmAst" 4 "Am" 5 "AmAst" ;
VAL_ 725 ACU_AFMode_St 0 "Invalid" 1 "AfOn" 2 "AfOff" 3 "Auto" ;
VAL_ 932 RmtCtlBattMntr_B_Falt 1 "Yes" 0 "No" ;
VAL_ 932 VehStrtInhbt_D_Stat 1 "Inhibit" 0 "NoInhibit" ;
VAL_ 932 VehOnCtl_D_Stat 3 "NotUsed" 2 "On" 1 "Off" 0 "Null" ;
VAL_ 932 VehOnSrc2_D_Stat 15 "NotUsed_11" 14 "NotUsed_10" 13 "NotUsed_9" 12 "NotUsed_8" 11 "NotUsed_7" 10 "NotUsed_6" 9 "EsclRssd" 8 "AutonomousVehicle" 7 "SecureIdle" 6 "FleetVehicleInhibit" 5 "StolenVehicleInhibit" 4 "OverTheAir" 3 "RemoteParkAssist" 2 "RemoteStart" 1 "Manual" 0 "Off" ;
VAL_ 932 VehInhbtMde_D_Stat 7 "NotUsed_3" 6 "NotUsed_2" 5 "NotUsed_1" 4 "FullVehicleOta" 3 "Iviota" 2 "SyncOta" 1 "NoOtaSupport" 0 "Unconfigured" ;
VAL_ 932 ChildLck_D_Dsply 3 "NOT_SUPPORTED" 2 "ERROR" 1 "CHILD_UNLOCK" 0 "CHILD_LOCK" ;
VAL_ 993 EmButtn_D_Stat 7 "ButtonAssociationFailed" 6 "ButtonAssociationExited" 5 "ButtonAssociationEntered" 4 "Button4Pressed" 3 "Button3Pressed" 2 "Button2Pressed" 1 "Button1Pressed" 0 "Null" ;
VAL_ 993 StmsScrnDrvOn_B_Rq 1 "On" 0 "Off" ;
VAL_ 993 MemStoreMsgTxt_D_Rq 10 "NotUsed_2" 9 "NotUsed_1" 8 "Mem4Saved_ShowLinkMsg" 7 "Mem3Saved_ShowLinkMsg" 6 "Mem2Saved_ShowLinkMsg" 5 "Mem1Saved_ShowLinkMsg" 4 "Mem4Saved_DoNotShowLinkMsg" 3 "Mem3Saved_DoNotShowLinkMsg" 2 "Mem2Saved_DoNotShowLinkMsg" 1 "Mem1Saved_DoNotShowLinkMsg" 0 "Null" ;
VAL_ 993 MemSetButtnMsgTxt_D_Rq 3 "NotUsed" 2 "Press1or2or3" 1 "Press1or2" 0 "Null" ;
VAL_ 993 PersStore_D_Actl 3 "Unused" 2 "Null" 1 "InProgress" 0 "Complete" ;
VAL_ 993 MemSwtch_D_RqRecall 7 "Unused_3" 6 "Unused_2" 5 "Unused_1" 4 "PERS_4" 3 "PERS_3" 2 "PERS_2" 1 "PERS_1" 0 "Null" ;
VAL_ 993 MemSwtch_D_RqAssoc 7 "Unused_3" 6 "Unused_2" 5 "Unused_1" 4 "PERS_4" 3 "PERS_3" 2 "PERS_2" 1 "PERS_1" 0 "Null" ;
VAL_ 993 PersIndexDsm_D_Actl 7 "Unused_3" 6 "Unused_2" 5 "Unused_1" 4 "Vehicle" 3 "PERS_4" 2 "PERS_3" 1 "PERS_2" 0 "PERS_1" ;
VAL_ 945 AdasRelay_B_Stat2 1 "On" 0 "Off" ;
VAL_ 945 StrtrMtrCtlMsgTxt_D_Rq2 15 "Not_Used_12" 14 "Not_Used_11" 13 "Not_Used_10" 12 "Not_Used_9" 11 "Not_Used_8" 10 "Not_Used_7" 9 "Not_Used_6" 8 "Not_Used_5" 7 "Not_Used_4" 6 "Not_Used_3" 5 "Not_Used_2" 4 "Not_Used_1" 3 "Fault_UnableToStrtOrStop" 2 "PressTwiceToStart" 1 "Fault_GoToDealer" 0 "NoMessage" ;
VAL_ 945 PrkLckCtlMsgTxt_D2_Rq 7 "Message7" 6 "Message6" 5 "Message5" 4 "Message4" 3 "Message3" 2 "Message2" 1 "Message1" 0 "NoMessage" ;
VAL_ 945 KeyOffMde_D_Actl 15 "NotUsed_11" 14 "NotUsed_10" 13 "NotUsed_9" 12 "NotUsed_8" 11 "NotUsed_7" 10 "NotUsed_6" 9 "NotUsed_5" 8 "NotUsed_4" 7 "NotUsed_3" 6 "NotUsed_2" 5 "NotUsed_1" 4 "CriticalBattery" 3 "Hibernate" 2 "Transport" 1 "Factory" 0 "Normal" ;
VAL_ 945 KeyPadCodeDgt7_D_Dsply 15 "NotUsed_4" 14 "NotUsed_3" 13 "NotUsed_2" 12 "NotUsed_1" 11 "Button7_8and9_0" 10 "Button0" 9 "Button9_0or9" 8 "Button8" 7 "Button7_8or7" 6 "Button6" 5 "Button5_6or5" 4 "Button4" 3 "Button3_4or3" 2 "Button2" 1 "Button1_2or1" 0 "EndofString" ;
VAL_ 945 KeyPadCodeDgt6_D_Dsply 15 "NotUsed_4" 14 "NotUsed_3" 13 "NotUsed_2" 12 "NotUsed_1" 11 "Button7_8and9_0" 10 "Button0" 9 "Button9_0or9" 8 "Button8" 7 "Button7_8or7" 6 "Button6" 5 "Button5_6or5" 4 "Button4" 3 "Button3_4or3" 2 "Button2" 1 "Button1_2or1" 0 "EndofString" ;
VAL_ 945 KeyPadCodeDgt5_D_Dsply 15 "NotUsed_4" 14 "NotUsed_3" 13 "NotUsed_2" 12 "NotUsed_1" 11 "Button7_8and9_0" 10 "Button0" 9 "Button9_0or9" 8 "Button8" 7 "Button7_8or7" 6 "Button6" 5 "Button5_6or5" 4 "Button4" 3 "Button3_4or3" 2 "Button2" 1 "Button1_2or1" 0 "EndofString" ;
VAL_ 945 KeyPadCodeDgt4_D_Dsply 15 "NotUsed_4" 14 "NotUsed_3" 13 "NotUsed_2" 12 "NotUsed_1" 11 "Button7_8and9_0" 10 "Button0" 9 "Button9_0or9" 8 "Button8" 7 "Button7_8or7" 6 "Button6" 5 "Button5_6or5" 4 "Button4" 3 "Button3_4or3" 2 "Button2" 1 "Button1_2or1" 0 "EndofString" ;
VAL_ 945 KeyPadCodeDgt3_D_Dsply 15 "NotUsed_4" 14 "NotUsed_3" 13 "NotUsed_2" 12 "NotUsed_1" 11 "Button7_8and9_0" 10 "Button0" 9 "Button9_0or9" 8 "Button8" 7 "Button7_8or7" 6 "Button6" 5 "Button5_6or5" 4 "Button4" 3 "Button3_4or3" 2 "Button2" 1 "Button1_2or1" 0 "EndofString" ;
VAL_ 945 KeyPadCodeDgt2_D_Dsply 15 "NotUsed_4" 14 "NotUsed_3" 13 "NotUsed_2" 12 "NotUsed_1" 11 "Button7_8and9_0" 10 "Button0" 9 "Button9_0or9" 8 "Button8" 7 "Button7_8or7" 6 "Button6" 5 "Button5_6or5" 4 "Button4" 3 "Button3_4or3" 2 "Button2" 1 "Button1_2or1" 0 "EndofString" ;
VAL_ 945 KeyPadCodeDgt1_D_Dsply 15 "NotUsed_4" 14 "NotUsed_3" 13 "NotUsed_2" 12 "NotUsed_1" 11 "Button7_8and9_0" 10 "Button0" 9 "Button9_0or9" 8 "Button8" 7 "Button7_8or7" 6 "Button6" 5 "Button5_6or5" 4 "Button4" 3 "Button3_4or3" 2 "Button2" 1 "Button1_2or1" 0 "EndofString" ;
VAL_ 945 PrkLckCtlLatch_B_Rq 1 "On" 0 "Off" ;
VAL_ 772 SeatScrnDrvOn_B_Rq 1 "On" 0 "Off" ;
VAL_ 772 PwRnngBoardT_D_Stat 3 "NotUsed" 2 "Timer2" 1 "Timer1" 0 "Inactive" ;
VAL_ 772 PwRnngBoardSwtch_D_Stat 3 "NotUsed" 2 "DeployUnlocked" 1 "AlwaysActive" 0 "Inactive" ;
VAL_ 772 SeatSlprPosPsngr_D_Stat 3 "Faulty" 2 "Sleeper" 1 "Upright" 0 "Null" ;
VAL_ 772 SeatSlprPosMsgTxt_B_Rq 1 "On" 0 "Off" ;
VAL_ 772 SeatPos_D_Stat 7 "NotUsed3" 6 "NotUsed2" 5 "Error" 4 "Drive" 3 "Moving" 2 "Pending" 1 "EasyEntry" 0 "Null" ;
VAL_ 772 MemDrvDeny_B_Stat 1 "Yes" 0 "No" ;
VAL_ 772 Memory_Feedback_Rqst 1 "Yes" 0 "No" ;
VAL_ 772 Easy_Entry_Rqst 2 "Easy_Entry" 1 "Drive" 0 "Null" ;
VAL_ 772 Memory_Cmd 7 "Recall_3" 4 "Store_4" 3 "Store_3" 6 "Recall_2" 5 "Recall_1" 2 "Store_2" 1 "Store_1" 0 "Null" 8 "Recall_4" ;
VAL_ 772 Cancel_Auto_Movement 1 "Cancel" 0 "Null" ;
SIG_GROUP_ 932 Profile1A_SigGroup_FD3_3A4 1 : VehOnSrc2_D_Stat VehOnCtl_D_Stat VehStrtInhbt_D_Stat CanMsg3A4_No_Cnt VehInhbtMde_D_Stat CanMsg3A4_No_Crc;
